VERSION ""

NS_ :

BS_:

BU_: WPC2 PSB SHVU_RR vHS_B2 FCS EMCU SLB GW_APSU GW_DLBCU RCM ARS CGW_CCU vDummy_HS_B GW_RLPSU ATS RLHV SGU PFSU GW_RRPSU ALBCU DSAU SWRC SHVU_FR RCS GW_DPSU BLTN_CAM SCM OHCL RWPC RRHV WPC HOD ASAU

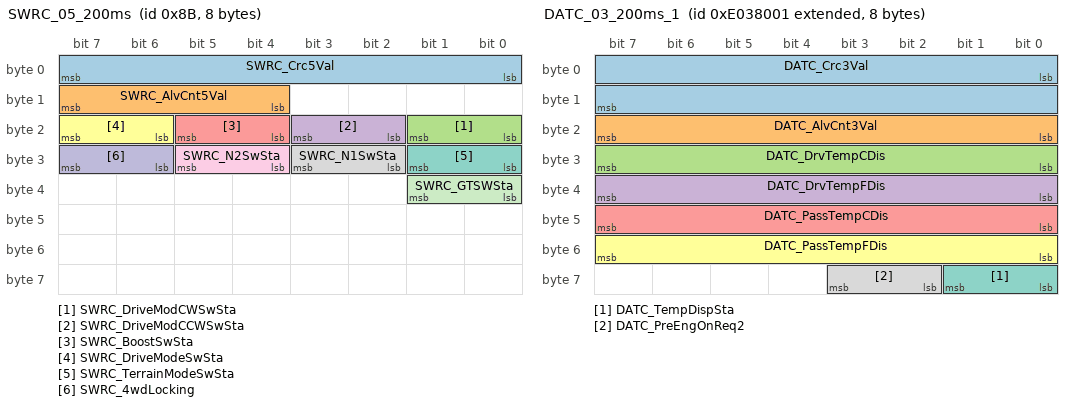
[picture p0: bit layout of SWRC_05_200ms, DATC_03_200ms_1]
BO_ 139 SWRC_05_200ms: 8 SWRC
 SG_ SWRC_Crc5Val : 0|8@1+ (1,0) [0|0] ""  CGW_CCU
 SG_ SWRC_AlvCnt5Val : 12|4@1+ (1,0) [0|0] ""  CGW_CCU
 SG_ SWRC_DriveModCWSwSta : 16|2@1+ (1,0) [0|0] ""  CGW_CCU
 SG_ SWRC_DriveModCCWSwSta : 18|2@1+ (1,0) [0|0] ""  CGW_CCU
 SG_ SWRC_BoostSwSta : 20|2@1+ (1,0) [0|0] ""  CGW_CCU
 SG_ SWRC_DriveModeSwSta : 22|2@1+ (1,0) [0|0] ""  CGW_CCU
 SG_ SWRC_TerrainModeSwSta : 24|2@1+ (1,0) [0|0] ""  CGW_CCU
 SG_ SWRC_N1SwSta : 26|2@1+ (1,0) [0|0] ""  CGW_CCU
 SG_ SWRC_N2SwSta : 28|2@1+ (1,0) [0|0] ""  CGW_CCU
 SG_ SWRC_4wdLocking : 30|2@1+ (1,0) [0|0] "Watt"  CGW_CCU
 SG_ SWRC_GTSWSta : 32|2@1+ (1,0) [0|0] ""  CGW_CCU

BO_ 2382594049 DATC_03_200ms_1: 8 CGW_CCU
 SG_ DATC_Crc3Val : 0|16@1+ (1,0) [0|0] ""  Vector__XXX
 SG_ DATC_AlvCnt3Val : 16|8@1+ (1,0) [0|0] ""  Vector__XXX
 SG_ DATC_DrvTempCDis : 24|8@1+ (0.5,14) [0|0] "¡É"  ATS
 SG_ DATC_DrvTempFDis : 32|8@1+ (1,56) [0|0] "¢µ"  ATS
 SG_ DATC_PassTempCDis : 40|8@1+ (0.5,14) [0|0] "¡É"  ATS
 SG_ DATC_PassTempFDis : 48|8@1+ (1,56) [0|0] "¢µ"  ATS
 SG_ DATC_TempDispSta : 56|2@1+ (1,0) [0|0] ""  Vector__XXX
 SG_ DATC_PreEngOnReq2 : 58|2@1+ (1,0) [0|0] ""  Vector__XXX

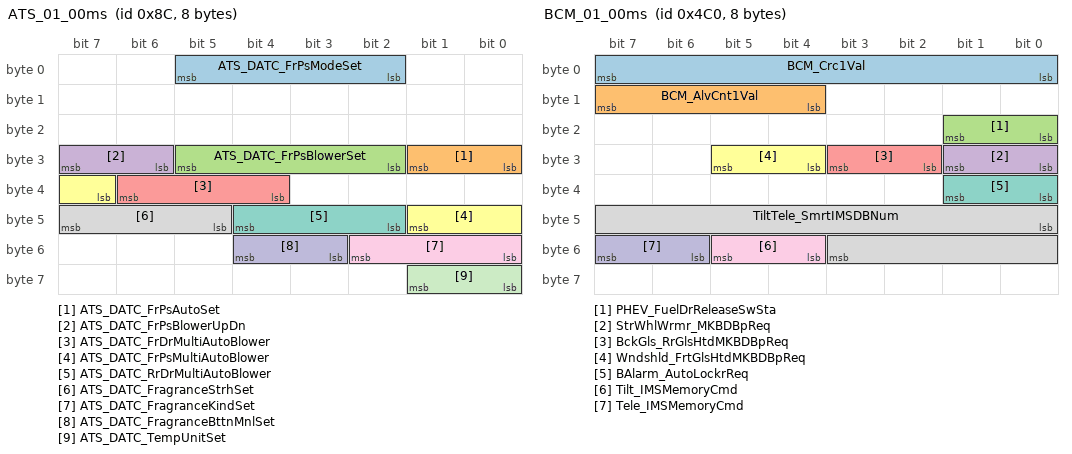
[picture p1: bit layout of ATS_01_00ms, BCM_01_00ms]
BO_ 140 ATS_01_00ms: 8 ATS
 SG_ ATS_DATC_FrPsModeSet : 2|4@1+ (1,0) [0|0] ""  CGW_CCU
 SG_ ATS_DATC_FrPsAutoSet : 24|2@1+ (1,0) [0|0] ""  CGW_CCU
 SG_ ATS_DATC_FrPsBlowerSet : 26|4@1+ (1,0) [0|0] ""  CGW_CCU
 SG_ ATS_DATC_FrPsBlowerUpDn : 30|2@1+ (1,0) [0|0] ""  CGW_CCU
 SG_ ATS_DATC_FrDrMultiAutoBlower : 36|3@1+ (1,0) [0|0] ""  CGW_CCU
 SG_ ATS_DATC_FrPsMultiAutoBlower : 39|3@1+ (1,0) [0|0] ""  CGW_CCU
 SG_ ATS_DATC_RrDrMultiAutoBlower : 42|3@1+ (1,0) [0|0] ""  CGW_CCU
 SG_ ATS_DATC_FragranceStrhSet : 45|3@1+ (1,0) [0|0] ""  CGW_CCU
 SG_ ATS_DATC_FragranceKindSet : 48|3@1+ (1,0) [0|0] ""  CGW_CCU
 SG_ ATS_DATC_FragranceBttnMnlSet : 51|2@1+ (1,0) [0|0] ""  CGW_CCU
 SG_ ATS_DATC_TempUnitSet : 56|2@1+ (1,0) [0|0] ""  CGW_CCU

BO_ 1216 BCM_01_00ms: 8 CGW_CCU
 SG_ BCM_Crc1Val : 0|8@1+ (1,0) [0|0] ""  Vector__XXX
 SG_ BCM_AlvCnt1Val : 12|4@1+ (1,0) [0|0] ""  Vector__XXX
 SG_ PHEV_FuelDrReleaseSwSta : 16|2@1+ (1,0) [0|0] ""  Vector__XXX
 SG_ StrWhlWrmr_MKBDBpReq : 24|2@1+ (1,0) [0|0] ""  Vector__XXX
 SG_ BckGls_RrGlsHtdMKBDBpReq : 26|2@1+ (1,0) [0|0] ""  Vector__XXX
 SG_ Wndshld_FrtGlsHtdMKBDBpReq : 28|2@1+ (1,0) [0|0] ""  Vector__XXX
 SG_ BAlarm_AutoLockrReq : 32|2@1+ (1,0) [0|0] ""  Vector__XXX
 SG_ TiltTele_SmrtIMSDBNum : 40|12@1+ (1,0) [0|0] ""  SCM
 SG_ Tilt_IMSMemoryCmd : 52|2@1+ (1,0) [0|0] ""  SCM
 SG_ Tele_IMSMemoryCmd : 54|2@1+ (1,0) [0|0] ""  SCM

BO_ 1219 HU_BLTN_CAM_E_00: 8 CGW_CCU
 SG_ BLTN_CAM_Rec_OWD_NvalueSet : 0|2@1+ (1,0) [0|0] ""  BLTN_CAM
 SG_ BLTN_CAM_Time_Stm_NvalueSet : 10|2@1+ (1,0) [0|0] ""  BLTN_CAM
 SG_ BLTN_CAM_Spd_Stm_NvalueSet : 12|2@1+ (1,0) [0|0] ""  BLTN_CAM
 SG_ BLTN_CAM_Locatn_Stm_NvalueSet : 14|2@1+ (1,0) [0|0] ""  BLTN_CAM
 SG_ BLTN_CAM_TrnSig_Stm_NvalueSet : 16|2@1+ (1,0) [0|0] ""  BLTN_CAM
 SG_ BLTN_CAM_AclBrk_Stm_NvalueSet : 18|2@1+ (1,0) [0|0] ""  BLTN_CAM
 SG_ BLTN_CAM_Rec_DEV_NvalueSet : 2|2@1+ (1,0) [0|0] ""  BLTN_CAM
 SG_ BLTN_CAM_GearPos_Stm_NvalueSet : 20|2@1+ (1,0) [0|0] ""  BLTN_CAM
 SG_ BLTN_CAM_EVSen_Stm_NvalueSet : 22|2@1+ (1,0) [0|0] ""  BLTN_CAM
 SG_ BLTN_CAM_Strangl_Stm_NvalueSet : 24|2@1+ (1,0) [0|0] ""  BLTN_CAM
 SG_ BLTN_CAM_EV_RecMaxTime_NvalueSet : 26|2@1+ (1,0) [0|0] ""  BLTN_CAM
 SG_ BLTN_CAM_PrkTime_NvalueSet : 30|8@1+ (1,0) [0|0] "Hour"  BLTN_CAM
 SG_ BLTN_CAM_EV_BfrTime_NvalueSet : 38|5@1+ (1,0) [0|0] ""  BLTN_CAM
 SG_ BLTN_CAM_Rec_OWP_NvalueSet : 4|2@1+ (1,0) [0|0] ""  BLTN_CAM
 SG_ BLTN_CAM_EV_AftTime_NvalueSet : 43|5@1+ (1,0) [0|0] ""  BLTN_CAM
 SG_ BLTN_CAM_TML_Int_NvalueSet : 48|4@1+ (1,0) [0|0] ""  BLTN_CAM
 SG_ BLTN_CAM_Sen_DEV_NvalueSet : 52|4@1+ (1,0) [0|0] ""  BLTN_CAM
 SG_ BLTN_CAM_Sen_PEV_NvalueSet : 56|4@1+ (1,0) [0|0] ""  BLTN_CAM
 SG_ BLTN_CAM_Rec_PEV_NvalueSet : 6|2@1+ (1,0) [0|0] ""  BLTN_CAM
 SG_ BLTN_CAM_AudRec_NvalueSet : 8|2@1+ (1,0) [0|0] ""  BLTN_CAM

BO_ 1218 HU_USM_E_08: 8 CGW_CCU
 SG_ C_AVN_PTGHeightNValueSet : 13|3@1+ (1,0) [0|0] ""  Vector__XXX
 SG_ CF_AVN_SCCMLReset : 16|2@1+ (1,0) [0|0] ""  Vector__XXX
 SG_ C_TgltAwayCloseNValue : 18|2@1+ (1,0) [0|0] ""  Vector__XXX
 SG_ C_HAnBNValueSet : 20|2@1+ (1,0) [0|0] ""  Vector__XXX
 SG_ CF_AVN_RrSeatRemindNValueSet : 22|2@1+ (1,0) [0|0] ""  Vector__XXX
 SG_ CF_AVN_DSWNValueSet : 24|2@1+ (1,0) [0|0] ""  Vector__XXX
 SG_ CF_AVN_RRPSU_RLNValueSet : 26|3@1+ (1,0) [0|0] ""  GW_APSU,GW_RLPSU,GW_RRPSU
 SG_ CF_AVN_APSUNValueSet : 29|3@1+ (1,0) [0|0] ""  GW_APSU
 SG_ CF_AVN_NCC_CameraNValueSet : 32|3@1+ (1,0) [0|0] ""  Vector__XXX
 SG_ CF_AVN_RRPSU_RRNValueSet : 37|3@1+ (1,0) [0|0] ""  GW_APSU,GW_RLPSU,GW_RRPSU
 SG_ CF_AVN_HtBlcAstNValueSet : 40|4@1+ (1,0) [0|0] ""  GW_APSU,SHVU_FR
 SG_ CF_AVN_HtBlcDrvNValueSet : 44|4@1+ (1,0) [0|0] ""  GW_APSU,GW_DPSU,SHVU_FR
 SG_ CF_AVN_SCCModeNValueSet : 48|2@1+ (1,0) [0|0] ""  Vector__XXX
 SG_ CF_AVN_SCCMLChar1Set : 50|3@1+ (1,0) [0|0] ""  Vector__XXX
 SG_ CF_AVN_UIPNValueSet : 54|2@1+ (1,0) [0|0] ""  Vector__XXX
 SG_ CF_AVN_SCCMLChar2Set : 56|3@1+ (1,0) [0|0] ""  Vector__XXX
 SG_ CF_AVN_SCCMLChar3Set : 59|3@1+ (1,0) [0|0] ""  Vector__XXX
 SG_ CF_AVN_HDALCFuncNValueSet : 8|2@1+ (1,0) [0|0] ""  Vector__XXX

BO_ 2323816451 CCU_CCS_01_00ms_3: 8 CGW_CCU

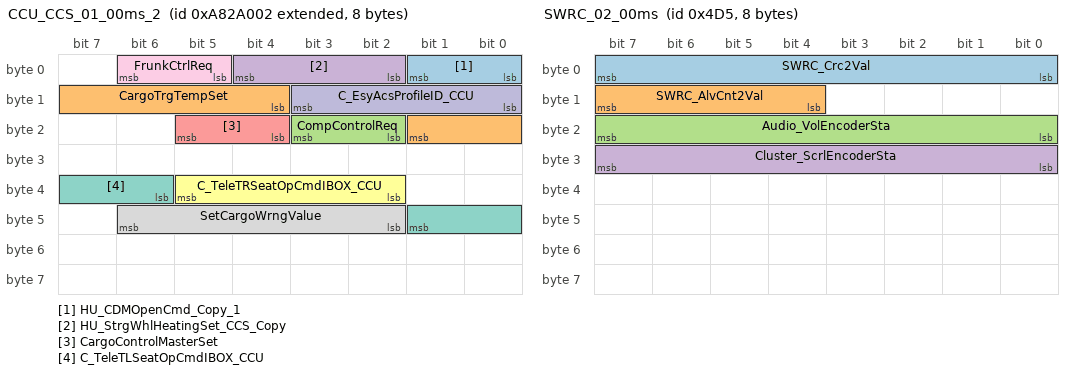
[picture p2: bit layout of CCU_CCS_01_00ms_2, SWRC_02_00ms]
BO_ 2323816450 CCU_CCS_01_00ms_2: 8 CGW_CCU
 SG_ HU_CDMOpenCmd_Copy_1 : 0|2@1+ (1,0) [0|0] ""  Vector__XXX
 SG_ CargoTrgTempSet : 12|6@1+ (1,-30) [0|0] "¡É"  Vector__XXX
 SG_ CompControlReq : 18|2@1+ (1,0) [0|0] ""  Vector__XXX
 SG_ HU_StrgWhlHeatingSet_CCS_Copy : 2|3@1+ (1,0) [0|0] ""  Vector__XXX
 SG_ CargoControlMasterSet : 20|2@1+ (1,0) [0|0] ""  Vector__XXX
 SG_ C_TeleTRSeatOpCmdIBOX_CCU : 34|4@1+ (1,0) [0|0] ""  Vector__XXX
 SG_ C_TeleTLSeatOpCmdIBOX_CCU : 38|4@1+ (1,0) [0|0] ""  Vector__XXX
 SG_ SetCargoWrngValue : 42|5@1+ (1,0) [0|0] "¡É"  Vector__XXX
 SG_ FrunkCtrlReq : 5|2@1+ (1,0) [0|0] ""  Vector__XXX
 SG_ C_EsyAcsProfileID_CCU : 8|4@1+ (1,0) [0|0] ""  GW_DPSU

BO_ 2323816449 CCU_CCS_01_00ms_1: 8 CGW_CCU
 SG_ C_CtrlDrLockRlyCCS_Copy_2 : 0|2@1+ (1,0) [0|0] ""  Vector__XXX
 SG_ C_TeleHeatingCmdIBOX_Copy_2 : 10|2@1+ (1,0) [0|0] ""  Vector__XXX
 SG_ C_TeleStrgWhlHeatingCmdIBOX_Copy_2 : 12|2@1+ (1,0) [0|0] ""  Vector__XXX
 SG_ C_TeleDefoggerHeatingCmdIBOX_Copy_2 : 14|2@1+ (1,0) [0|0] ""  Vector__XXX
 SG_ C_TeleDrvSeatOpCmdIBOX_Copy_2 : 16|4@1+ (1,0) [0|0] ""  GW_APSU,GW_DPSU,SHVU_FR
 SG_ C_CtrlDrUnlockRlyCCS_Copy_2 : 2|2@1+ (1,0) [0|0] ""  Vector__XXX
 SG_ C_TeleAstSeatOpCmdIBOX_Copy_2 : 20|4@1+ (1,0) [0|0] ""  GW_APSU,SHVU_FR
 SG_ C_TeleRRSeatOpCmdIBOX_Copy_2 : 24|4@1+ (1,0) [0|0] ""  ATS,GW_RRPSU,RRHV,SHVU_FR,SHVU_RR
 SG_ C_TeleRLSeatOpCmdIBOX_Copy_1 : 28|4@1+ (1,0) [0|0] ""  ATS,GW_RLPSU,RLHV,SHVU_FR,SHVU_RR
 SG_ C_DrvWindowCmdAVN_Copy_2 : 38|4@1+ (1,0) [0|0] ""  Vector__XXX
 SG_ C_HazardFromCCS_Copy_2 : 4|2@1+ (1,0) [0|0] ""  Vector__XXX
 SG_ C_AstWindowCmdAVN_Copy_2 : 42|4@1+ (1,0) [0|0] ""  Vector__XXX
 SG_ C_RRWindowCmdAVN_Copy_2 : 46|4@1+ (1,0) [0|0] ""  Vector__XXX
 SG_ C_RLWindowCmdAVN_Copy_2 : 50|4@1+ (1,0) [0|0] ""  Vector__XXX
 SG_ TailCtrlReq_Copy : 54|2@1+ (1,0) [0|0] ""  Vector__XXX
 SG_ HazardCtrlReq_Copy : 56|2@1+ (1,0) [0|0] ""  Vector__XXX
 SG_ HU_DATC_AirCleaningSet_Copy_1 : 58|2@1+ (1,0) [0|0] ""  Vector__XXX
 SG_ C_PanicFromCCS_Copy_2 : 6|2@1+ (1,0) [0|0] ""  Vector__XXX
 SG_ C_TeleFrontHeatingCmdIBOX_Copy_1 : 60|2@1+ (1,0) [0|0] ""  Vector__XXX
 SG_ RAC_AirCleaningCtrlReq_Copy_1 : 62|2@1+ (1,0) [0|0] ""  Vector__XXX
 SG_ C_PreCrankReq_Copy : 8|2@1+ (1,0) [0|0] ""  Vector__XXX

BO_ 1227 PSM_01_00ms: 8 GW_DPSU
 SG_ DrvIMS_MemoryP1Req : 0|2@1+ (1,0) [0|0] ""  CGW_CCU
 SG_ DrvIMS_PlyBckP2Req : 10|2@1+ (1,0) [0|0] ""  CGW_CCU
 SG_ DrvIMS_PlyBckP3Req : 12|2@1+ (1,0) [0|0] ""  CGW_CCU
 SG_ DrvIMS_PlyBckStpReq : 14|2@1+ (1,0) [0|0] ""  CGW_CCU
 SG_ SmrtIMS_PlyBckReq : 16|12@1+ (1,0) [0|0] ""  CGW_CCU
 SG_ DrvIMS_MemoryP2Req : 2|2@1+ (1,0) [0|0] ""  CGW_CCU
 SG_ PSM_IMSReq : 28|3@1+ (1,0) [0|0] ""  CGW_CCU
 SG_ SmrtIMS_ImgDBVal : 32|5@1+ (1,0) [0|0] ""  CGW_CCU
 SG_ SmrtIMS_PlyBckStpReq : 37|2@1+ (1,0) [0|0] ""  CGW_CCU
 SG_ DrvIMS_MemoryP3Req : 4|2@1+ (1,0) [0|0] ""  CGW_CCU
 SG_ SmrtIMS_EnterSwSta : 40|2@1+ (1,0) [0|0] ""  CGW_CCU
 SG_ DrvIMS_BzrReq : 42|2@1+ (1,0) [0|0] ""  CGW_CCU
 SG_ DrvIMS_ErrConWmgDis : 46|2@1+ (1,0) [0|0] ""  CGW_CCU
 SG_ PSM_DrvRlxReturn_Req : 48|3@1+ (1,0) [0|0] ""  CGW_CCU
 SG_ Drv_AutoRlxWrngDis : 51|3@1+ (1,0) [0|0] ""  CGW_CCU
 SG_ DrvIMS_AMPBzrReq : 54|2@1+ (1,0) [0|0] ""  CGW_CCU
 SG_ Drv_AutoRlxWrngDis_2 : 56|3@1+ (1,0) [0|0] ""  CGW_CCU
 SG_ Drv_2ndStStdPosMovReq : 59|2@1+ (1,0) [0|0] ""  GW_RLPSU,GW_RRPSU
 SG_ DrvIMS_MemorySetEnaSta : 6|2@1+ (1,0) [0|0] ""  CGW_CCU
 SG_ DrvIMS_PlyBckP1Req : 8|2@1+ (1,0) [0|0] ""  CGW_CCU

BO_ 2323816452 CCU_CCS_01_00ms_4: 8 CGW_CCU

BO_ 1237 SWRC_02_00ms: 8 SWRC
 SG_ SWRC_Crc2Val : 0|8@1+ (1,0) [0|0] ""  Vector__XXX
 SG_ SWRC_AlvCnt2Val : 12|4@1+ (1,0) [0|0] ""  Vector__XXX
 SG_ Audio_VolEncoderSta : 16|8@1+ (1,0) [0|0] ""  CGW_CCU
 SG_ Cluster_ScrlEncoderSta : 24|8@1+ (1,0) [0|0] ""  CGW_CCU

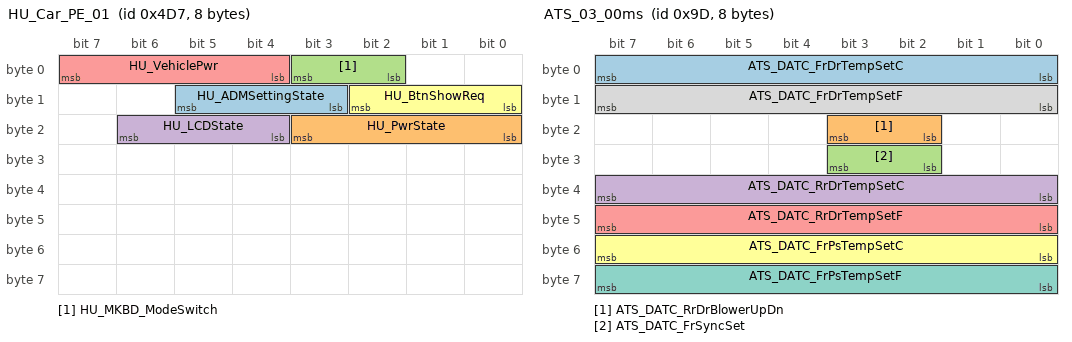
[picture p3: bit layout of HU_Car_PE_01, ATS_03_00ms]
BO_ 1239 HU_Car_PE_01: 8 CGW_CCU
 SG_ HU_ADMSettingState : 11|3@1+ (1,0) [0|0] ""  Vector__XXX
 SG_ HU_PwrState : 16|4@1+ (1,0) [0|0] ""  BLTN_CAM
 SG_ HU_MKBD_ModeSwitch : 2|2@1+ (1,0) [0|0] ""  Vector__XXX
 SG_ HU_LCDState : 20|3@1+ (1,0) [0|0] ""  Vector__XXX
 SG_ HU_VehiclePwr : 4|4@1+ (1,0) [0|0] ""  BLTN_CAM,SGU
 SG_ HU_BtnShowReq : 8|3@1+ (1,0) [0|0] ""  SWRC

BO_ 157 ATS_03_00ms: 8 ATS
 SG_ ATS_DATC_FrDrTempSetC : 0|8@1+ (0.5,14) [0|0] ""  CGW_CCU
 SG_ ATS_DATC_RrDrBlowerUpDn : 18|2@1+ (1,0) [0|0] ""  CGW_CCU
 SG_ ATS_DATC_FrSyncSet : 26|2@1+ (1,0) [0|0] ""  CGW_CCU
 SG_ ATS_DATC_RrDrTempSetC : 32|8@1+ (0.5,14) [0|0] ""  CGW_CCU
 SG_ ATS_DATC_RrDrTempSetF : 40|8@1+ (1,56) [0|0] ""  CGW_CCU
 SG_ ATS_DATC_FrPsTempSetC : 48|8@1+ (0.5,14) [0|0] ""  CGW_CCU
 SG_ ATS_DATC_FrPsTempSetF : 56|8@1+ (1,56) [0|0] ""  CGW_CCU
 SG_ ATS_DATC_FrDrTempSetF : 8|8@1+ (1,56) [0|0] ""  CGW_CCU

BO_ 158 ATS_02_00ms: 8 ATS
 SG_ ATS_DATC_FrDrBlowerSet : 12|4@1+ (1,0) [0|0] ""  CGW_CCU
 SG_ ATS_DATC_RrDrTempUpDn : 2|2@1+ (1,0) [0|0] ""  CGW_CCU
 SG_ ATS_DATC_RrDrBlowerSet : 20|4@1+ (1,0) [0|0] ""  CGW_CCU
 SG_ ATS_DATC_RrDrModeSet : 24|4@1+ (1,0) [0|0] ""  CGW_CCU
 SG_ ATS_DATC_FrDrModeSet : 28|4@1+ (1,0) [0|0] ""  CGW_CCU
 SG_ ATS_DATC_RrOnOffSet : 32|2@1+ (1,0) [0|0] ""  Vector__XXX
 SG_ ATS_DATC_IntakeSet : 34|2@1+ (1,0) [0|0] ""  CGW_CCU
 SG_ ATS_DATC_OffReq : 36|2@1+ (1,0) [0|0] ""  Vector__XXX
 SG_ ATS_DATC_FrDrAutoSet : 38|2@1+ (1,0) [0|0] ""  CGW_CCU
 SG_ ATS_DATC_FrPsTempUpDn : 4|2@1+ (1,0) [0|0] ""  CGW_CCU
 SG_ ATS_DATC_FrDefog : 42|2@1+ (1,0) [0|0] ""  CGW_CCU
 SG_ ATS_DATC_RrSyncSet : 44|2@1+ (1,0) [0|0] ""  CGW_CCU
 SG_ ATS_DATC_AcSet : 46|2@1+ (1,0) [0|0] ""  CGW_CCU
 SG_ ATS_DATC_AirCleaningSet : 56|2@1+ (1,0) [0|0] ""  CGW_CCU
 SG_ ATS_DATC_FrDrBlowerUpDn : 58|2@1+ (1,0) [0|0] ""  CGW_CCU
 SG_ ATS_DATC_FrDrTempUpDn : 6|2@1+ (1,0) [0|0] ""  CGW_CCU
 SG_ ATS_DATC_RrDrAutoSet : 62|2@1+ (1,0) [0|0] ""  CGW_CCU

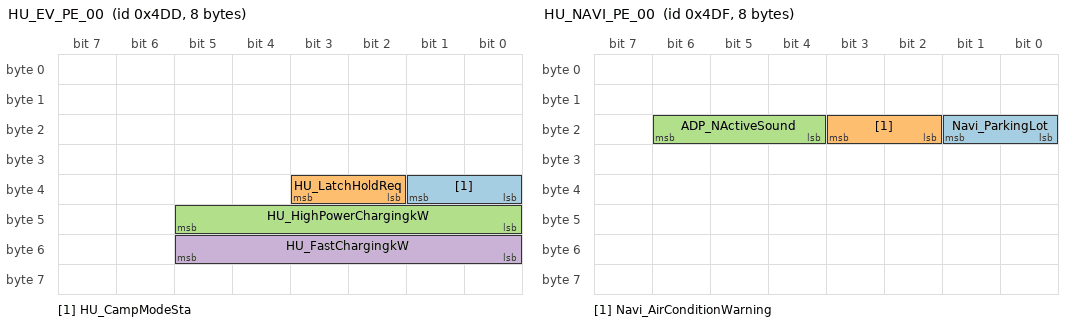
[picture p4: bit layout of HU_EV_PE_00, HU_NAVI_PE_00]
BO_ 1245 HU_EV_PE_00: 8 CGW_CCU
 SG_ HU_CampModeSta : 32|2@1+ (1,0) [0|0] ""  SWRC
 SG_ HU_LatchHoldReq : 34|2@1+ (1,0) [0|0] ""  Vector__XXX
 SG_ HU_HighPowerChargingkW : 40|6@1+ (10,0) [0|0] "kW"  Vector__XXX
 SG_ HU_FastChargingkW : 48|6@1+ (10,0) [0|0] "kW"  Vector__XXX

BO_ 1247 HU_NAVI_PE_00: 8 CGW_CCU
 SG_ Navi_ParkingLot : 16|2@1+ (1,0) [0|0] ""  Vector__XXX
 SG_ Navi_AirConditionWarning : 18|2@1+ (1,0) [0|0] ""  RCM
 SG_ ADP_NActiveSound : 20|3@1+ (1,0) [0|0] ""  Vector__XXX

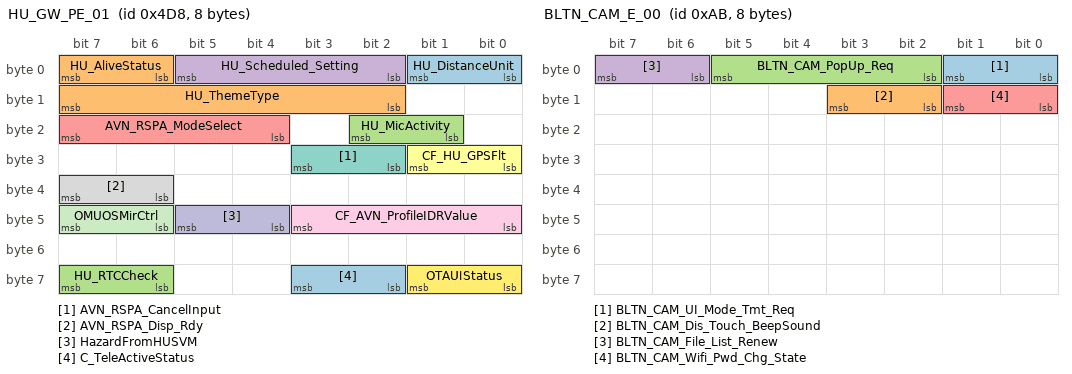
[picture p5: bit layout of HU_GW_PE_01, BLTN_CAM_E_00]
BO_ 1240 HU_GW_PE_01: 8 CGW_CCU
 SG_ HU_DistanceUnit : 0|2@1+ (1,0) [0|0] ""  Vector__XXX
 SG_ HU_ThemeType : 10|6@1+ (1,0) [0|0] ""  ATS,BLTN_CAM
 SG_ HU_MicActivity : 17|2@1+ (1,0) [0|0] ""  Vector__XXX
 SG_ HU_Scheduled_Setting : 2|4@1+ (1,0) [0|0] ""  Vector__XXX
 SG_ AVN_RSPA_ModeSelect : 20|4@1+ (1,0) [0|0] ""  Vector__XXX
 SG_ CF_HU_GPSFlt : 24|2@1+ (1,0) [0|0] ""  Vector__XXX
 SG_ AVN_RSPA_CancelInput : 26|2@1+ (1,0) [0|3] ""  Vector__XXX
 SG_ AVN_RSPA_Disp_Rdy : 38|2@1+ (1,0) [0|0] ""  Vector__XXX
 SG_ CF_AVN_ProfileIDRValue : 40|4@1+ (1,0) [0|0] ""  BLTN_CAM,GW_DLBCU,GW_DPSU,RCM,RWPC,SGU,WPC,WPC2
 SG_ HazardFromHUSVM : 44|2@1+ (1,0) [0|0] ""  Vector__XXX
 SG_ OMUOSMirCtrl : 46|2@1+ (1,0) [0|0] ""  Vector__XXX
 SG_ OTAUIStatus : 56|2@1+ (1,0) [0|0] ""  Vector__XXX
 SG_ C_TeleActiveStatus : 58|2@1+ (1,0) [0|0] ""  Vector__XXX
 SG_ HU_AliveStatus : 6|2@1+ (1,0) [0|0] ""  Vector__XXX
 SG_ HU_RTCCheck : 62|2@1+ (1,0) [0|0] ""  GW_APSU

BO_ 2424580353 DATC_12_200ms_1: 8 CGW_CCU
 SG_ DATC_Crc12Val : 0|16@1+ (1,0) [0|0] ""  Vector__XXX
 SG_ DATC_AlvCnt12Val : 16|8@1+ (1,0) [0|0] ""  Vector__XXX
 SG_ DATC_StrWhlHtrSwReq : 24|2@1+ (1,0) [0|0] ""  Vector__XXX
 SG_ DATC_FRStHtrSwReq : 26|2@1+ (1,0) [0|0] ""  GW_APSU,GW_DPSU,SHVU_FR,SHVU_RR
 SG_ DATC_FRStVentSwReq : 28|2@1+ (1,0) [0|0] ""  GW_APSU,GW_DPSU,SHVU_FR,SHVU_RR
 SG_ DATC_RrDefSw : 30|2@1+ (1,0) [0|0] ""  Vector__XXX
 SG_ DATC_FLStOpReq : 32|4@1+ (1,0) [0|0] ""  GW_APSU,GW_DPSU,SHVU_FR,SHVU_RR
 SG_ DATC_FRStOpReq : 36|4@1+ (1,0) [0|0] ""  GW_APSU,SHVU_FR,SHVU_RR
 SG_ DATC_FLStHtrSwReq : 40|2@1+ (1,0) [0|0] ""  GW_APSU,GW_DPSU,SHVU_FR,SHVU_RR
 SG_ DATC_FLStVentSwReq : 42|2@1+ (1,0) [0|0] ""  GW_APSU,GW_DPSU,SHVU_FR,SHVU_RR
 SG_ DATC_FLStTmblrSwReq : 44|2@1+ (1,0) [0|0] ""  GW_APSU,GW_DPSU,SHVU_FR
 SG_ DATC_FRStTmblrSwReq : 46|2@1+ (1,0) [0|0] ""  GW_APSU,GW_DPSU,SHVU_FR
 SG_ DATC_RRStHtrSwReq : 48|2@1+ (1,0) [0|0] ""  GW_RRPSU,RRHV,SHVU_FR,SHVU_RR
 SG_ DATC_RRStVentSwReq : 50|2@1+ (1,0) [0|0] ""  GW_RRPSU,RRHV,SHVU_FR,SHVU_RR
 SG_ DATC_RLStHtrSwReq : 52|2@1+ (1,0) [0|0] ""  GW_RLPSU,RLHV,SHVU_FR,SHVU_RR
 SG_ DATC_RLStVentSwReq : 54|2@1+ (1,0) [0|0] ""  GW_RLPSU,RLHV,SHVU_FR,SHVU_RR
 SG_ DATC_FRWndShldHtSW : 56|2@1+ (1,0) [0|0] ""  Vector__XXX
 SG_ DATC_WhistlelNoise : 58|2@1+ (1,0) [0|0] ""  Vector__XXX
 SG_ DATC_WdwClsReq : 60|2@1+ (1,0) [0|0] ""  Vector__XXX
 SG_ DATC_RRSyncDis : 62|2@1+ (1,0) [0|0] ""  ATS

BO_ 171 BLTN_CAM_E_00: 8 BLTN_CAM
 SG_ BLTN_CAM_UI_Mode_Tmt_Req : 0|2@1+ (1,0) [0|0] ""  CGW_CCU
 SG_ BLTN_CAM_Dis_Touch_BeepSound : 10|2@1+ (1,0) [0|0] ""  CGW_CCU
 SG_ BLTN_CAM_PopUp_Req : 2|4@1+ (1,0) [0|0] ""  CGW_CCU
 SG_ BLTN_CAM_File_List_Renew : 6|2@1+ (1,0) [0|0] ""  CGW_CCU
 SG_ BLTN_CAM_Wifi_Pwd_Chg_State : 8|2@1+ (1,0) [0|0] ""  CGW_CCU

BO_ 1253 SMK_01_00ms: 8 CGW_CCU
 SG_ SMK_Crc1Val : 0|8@1+ (1,0) [0|0] ""  Vector__XXX
 SG_ SMK_AlvCnt1Val : 12|4@1+ (1,0) [0|0] ""  Vector__XXX
 SG_ DoorLock_PsvDrLkReq : 16|3@1+ (1,0) [0|0] ""  Vector__XXX
 SG_ DoorLock_PsvDrUnLkReq : 19|3@1+ (1,0) [0|0] ""  Vector__XXX
 SG_ DoorLock_DrvDrPsvAcsReq : 22|2@1+ (1,0) [0|0] ""  Vector__XXX
 SG_ DoorLock_AsstDrPsvAcsReq : 24|2@1+ (1,0) [0|0] ""  Vector__XXX
 SG_ DoorLock_TrnkTlgtPsvAcsReq : 26|2@1+ (1,0) [0|0] ""  Vector__XXX
 SG_ DoorLock_RrLftDrPsvAcsReq : 28|2@1+ (1,0) [0|0] ""  Vector__XXX
 SG_ DoorLock_RrRtDrPsvAcsReq : 30|2@1+ (1,0) [0|0] ""  Vector__XXX
 SG_ DoorLock_PsdPsvAcsReq : 32|3@1+ (1,0) [0|0] ""  Vector__XXX
 SG_ Auth_Req : 35|3@1+ (1,0) [0|0] ""  Vector__XXX
 SG_ RSPA_DigitalKeyAuth : 38|2@1+ (1,0) [0|0] ""  Vector__XXX
 SG_ Auth_Method : 42|4@1+ (1,0) [0|0] ""  GW_DPSU
 SG_ DoorLock_StrgbxPsvAcsReq : 46|2@1+ (1,0) [0|0] ""  Vector__XXX
 SG_ Auth_ISKLearnFdbck : 50|4@1+ (1,0) [0|0] ""  Vector__XXX
 SG_ DoorLock_FrnkWrngOpnReq : 54|2@1+ (1,0) [0|0] ""  Vector__XXX
 SG_ DoorLock_SmrtPsdPsvAcsReq : 61|3@1+ (1,0) [0|0] ""  Vector__XXX
 SG_ Auth_Event : 8|4@1+ (1,0) [0|0] ""  GW_DPSU

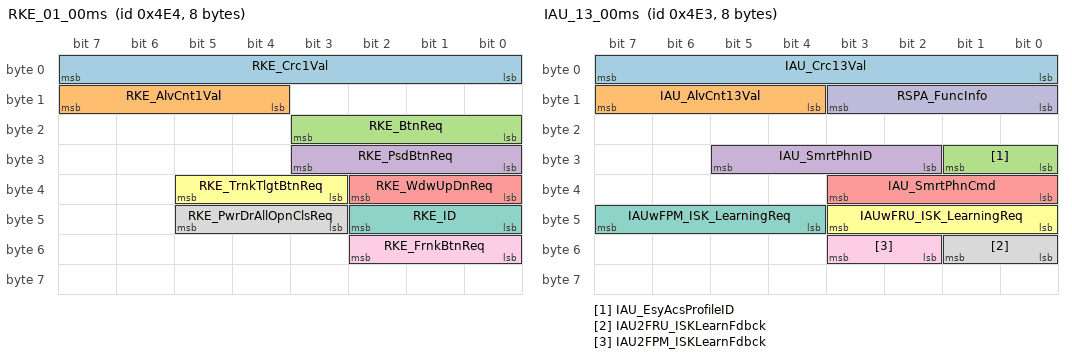
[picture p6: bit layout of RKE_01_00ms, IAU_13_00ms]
BO_ 1252 RKE_01_00ms: 8 CGW_CCU
 SG_ RKE_Crc1Val : 0|8@1+ (1,0) [0|0] ""  Vector__XXX
 SG_ RKE_AlvCnt1Val : 12|4@1+ (1,0) [0|0] ""  Vector__XXX
 SG_ RKE_BtnReq : 16|4@1+ (1,0) [0|0] ""  ATS
 SG_ RKE_PsdBtnReq : 24|4@1+ (1,0) [0|0] ""  Vector__XXX
 SG_ RKE_WdwUpDnReq : 32|3@1+ (1,0) [0|0] ""  RCM
 SG_ RKE_TrnkTlgtBtnReq : 35|3@1+ (1,0) [0|0] ""  Vector__XXX
 SG_ RKE_ID : 40|3@1+ (1,0) [0|0] ""  Vector__XXX
 SG_ RKE_PwrDrAllOpnClsReq : 43|3@1+ (1,0) [0|0] ""  Vector__XXX
 SG_ RKE_FrnkBtnReq : 48|3@1+ (1,0) [0|0] ""  Vector__XXX

BO_ 1251 IAU_13_00ms: 8 CGW_CCU
 SG_ IAU_Crc13Val : 0|8@1+ (1,0) [0|0] ""  Vector__XXX
 SG_ IAU_AlvCnt13Val : 12|4@1+ (1,0) [0|0] ""  Vector__XXX
 SG_ IAU_EsyAcsProfileID : 24|2@1+ (1,0) [0|0] ""  GW_DPSU
 SG_ IAU_SmrtPhnID : 26|4@1+ (1,0) [0|0] ""  Vector__XXX
 SG_ IAU_SmrtPhnCmd : 32|4@1+ (1,0) [0|0] ""  Vector__XXX
 SG_ IAUwFRU_ISK_LearningReq : 40|4@1+ (1,0) [0|0] ""  Vector__XXX
 SG_ IAUwFPM_ISK_LearningReq : 44|4@1+ (1,0) [0|0] ""  Vector__XXX
 SG_ IAU2FRU_ISKLearnFdbck : 48|2@1+ (1,0) [0|0] ""  Vector__XXX
 SG_ IAU2FPM_ISKLearnFdbck : 50|2@1+ (1,0) [0|0] ""  Vector__XXX
 SG_ RSPA_FuncInfo : 8|4@1+ (1,0) [0|0] ""  Vector__XXX

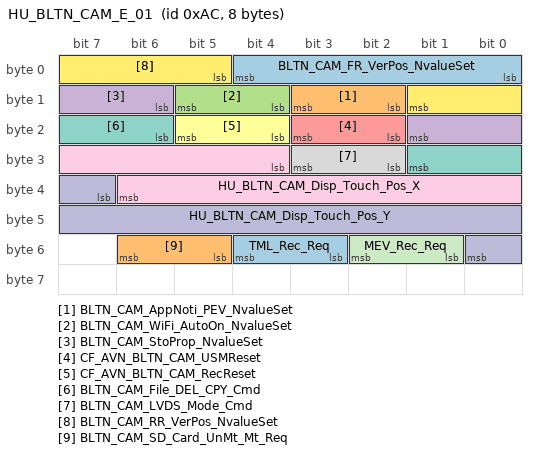
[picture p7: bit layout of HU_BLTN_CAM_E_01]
BO_ 172 HU_BLTN_CAM_E_01: 8 CGW_CCU
 SG_ BLTN_CAM_FR_VerPos_NvalueSet : 0|5@1+ (1,0) [0|0] ""  BLTN_CAM
 SG_ BLTN_CAM_AppNoti_PEV_NvalueSet : 10|2@1+ (1,0) [0|0] ""  BLTN_CAM
 SG_ BLTN_CAM_WiFi_AutoOn_NvalueSet : 12|2@1+ (1,0) [0|0] ""  BLTN_CAM
 SG_ BLTN_CAM_StoProp_NvalueSet : 14|4@1+ (1,0) [0|0] ""  BLTN_CAM
 SG_ CF_AVN_BLTN_CAM_USMReset : 18|2@1+ (1,0) [0|0] ""  BLTN_CAM
 SG_ CF_AVN_BLTN_CAM_RecReset : 20|2@1+ (1,0) [0|0] ""  BLTN_CAM
 SG_ BLTN_CAM_File_DEL_CPY_Cmd : 22|4@1+ (1,0) [0|0] ""  BLTN_CAM
 SG_ BLTN_CAM_LVDS_Mode_Cmd : 26|2@1+ (1,0) [0|0] ""  BLTN_CAM
 SG_ HU_BLTN_CAM_Disp_Touch_Pos_X : 28|11@1+ (1,0) [0|0] ""  BLTN_CAM
 SG_ HU_BLTN_CAM_Disp_Touch_Pos_Y : 39|10@1+ (1,0) [0|0] ""  BLTN_CAM
 SG_ MEV_Rec_Req : 49|2@1+ (1,0) [0|0] ""  BLTN_CAM
 SG_ BLTN_CAM_RR_VerPos_NvalueSet : 5|5@1+ (1,0) [0|0] ""  BLTN_CAM
 SG_ TML_Rec_Req : 51|2@1+ (1,0) [0|0] ""  BLTN_CAM
 SG_ BLTN_CAM_SD_Card_UnMt_Mt_Req : 53|2@1+ (1,0) [0|0] ""  BLTN_CAM

CM_ BO_ 140 "[EC] On Event and On Change";
CM_ SG_ 140 ATS_DATC_FrPsModeSet "Front Passenger side Mode Set";
CM_ SG_ 140 ATS_DATC_FrPsAutoSet "Front Passenger side Auto Set";
CM_ SG_ 140 ATS_DATC_FrPsBlowerSet "Front Passenger side Blower Set";
CM_ SG_ 140 ATS_DATC_FrPsBlowerUpDn "Front Passenger side Blower Up Down";
CM_ SG_ 140 ATS_DATC_FrDrMultiAutoBlower "Front Driver side Multi-Auto Blower set";
CM_ SG_ 140 ATS_DATC_FrPsMultiAutoBlower "Front Passenger side Multi-Auto Blower set";
CM_ SG_ 140 ATS_DATC_RrDrMultiAutoBlower "Rear Driver side Multi-Auto Blower set";
CM_ SG_ 140 ATS_DATC_FragranceStrhSet "Fragrance Strength Set (¹ßÇâ ±â´É Çâ ¼¼±â ¼³Á¤)";
CM_ SG_ 140 ATS_DATC_FragranceKindSet "Fragrance Kind Set (¹ßÇâ ±â´É Çâ Á¾·ù ¼³Á¤)";
CM_ SG_ 140 ATS_DATC_FragranceBttnMnlSet "Fragrance Button Manual Set (¹ßÇâ ±â´É ¹öÆ° ¼öµ¿ ÀÔ·Â)";
CM_ SG_ 140 ATS_DATC_TempUnitSet "Temp Unit Set (¿Âµµ ´ÜÀ§ ¼³Á¤)";
CM_ BO_ 158 "[EC] On Event and On Change";
CM_ SG_ 158 ATS_DATC_FrDrBlowerSet "Front Driver side Blower Set";
CM_ SG_ 158 ATS_DATC_RrDrTempUpDn "Rear Driver side Temp Up Down";
CM_ SG_ 158 ATS_DATC_RrDrBlowerSet "Rear Driver side Blower Up Down";
CM_ SG_ 158 ATS_DATC_RrDrModeSet "Rear Driver side Mode Set";
CM_ SG_ 158 ATS_DATC_FrDrModeSet "Front Driver side Mode Set";
CM_ SG_ 158 ATS_DATC_RrOnOffSet "Rear Climate On/Off Set";
CM_ SG_ 158 ATS_DATC_IntakeSet "Intake Set";
CM_ SG_ 158 ATS_DATC_OffReq "Front Climate Off Set";
CM_ SG_ 158 ATS_DATC_FrDrAutoSet "Front Driver side Auto Set";
CM_ SG_ 158 ATS_DATC_FrPsTempUpDn "Front Passenger side Temp Up Down";
CM_ SG_ 158 ATS_DATC_FrDefog "Front Defog set";
CM_ SG_ 158 ATS_DATC_RrSyncSet "Rear Sync Set";
CM_ SG_ 158 ATS_DATC_AcSet "Ac Set";
CM_ SG_ 158 ATS_DATC_AirCleaningSet "AirCleaning Set";
CM_ SG_ 158 ATS_DATC_FrDrBlowerUpDn "Front Driver Blower Up Down";
CM_ SG_ 158 ATS_DATC_FrDrTempUpDn "Front Driver side Temp Up Down";
CM_ SG_ 158 ATS_DATC_RrDrAutoSet "Rear Driver side Auto Set";
CM_ BO_ 157 "[EC] On Event and On Change";
CM_ SG_ 157 ATS_DATC_FrDrTempSetC "Front Driver side Temp Set (Celsius)";
CM_ SG_ 157 ATS_DATC_RrDrBlowerUpDn "Rear Driver side Blower Up Down";
CM_ SG_ 157 ATS_DATC_FrSyncSet "Front Sync Set";
CM_ SG_ 157 ATS_DATC_RrDrTempSetC "Rear Driver side Temp Set (Celsius)";
CM_ SG_ 157 ATS_DATC_RrDrTempSetF "Rear Driver side Temp Set (Fahrenheit)";
CM_ SG_ 157 ATS_DATC_FrPsTempSetC "Front Passenger side Temp Set (Celsius)";
CM_ SG_ 157 ATS_DATC_FrPsTempSetF "Front Passenger side Temp Set (Fahrenheit)";
CM_ SG_ 157 ATS_DATC_FrDrTempSetF "Front Driver side Temp Set (Fahrenheit)";
CM_ BO_ 1216 "[EC] On Event and On Change";
CM_ SG_ 1216 BCM_Crc1Val "BCM_CyclicRedundancyCheck1Value";
CM_ SG_ 1216 BCM_AlvCnt1Val "BCM_AliveCounter1Value";
CM_ SG_ 1216 PHEV_FuelDrReleaseSwSta "PHEV Fuel Filler Door Release Sw State";
CM_ SG_ 1216 BAlarm_AutoLockrReq "BAlarm_AutoLockRequest ##2G##BCM - BCMmsg01 - C_AutoLockCmd";
CM_ BO_ 171 "[EC] On Event and On Change";
CM_ SG_ 171 BLTN_CAM_UI_Mode_Tmt_Req "Built-in Cam UI Mode terminate request.";
CM_ SG_ 171 BLTN_CAM_Dis_Touch_BeepSound "Display Touch Beep Sound of valid space touch.";
CM_ SG_ 171 BLTN_CAM_PopUp_Req "Built-in Cam Operating and SD Card related Popup Request on HU Display.";
CM_ SG_ 171 BLTN_CAM_File_List_Renew "The Storage information is renewed inform to HU.";
CM_ SG_ 171 BLTN_CAM_Wifi_Pwd_Chg_State "The Response, when HU change Wifi Passowrd via SOME/IP";
CM_ BO_ 2323816449 "[EC] On Event and On Change";
CM_ SG_ 2323816449 C_CtrlDrLockRlyCCS_Copy_2 "Command for Remote Door Lock";
CM_ SG_ 2323816449 C_TeleHeatingCmdIBOX_Copy_2 "'Command for Remote Heating

(Steering Wheel, Rear Window, Side Mirror)";
CM_ SG_ 2323816449 C_TeleStrgWhlHeatingCmdIBOX_Copy_2 "'Command for Remote Heating
(Steering Wheel)";
CM_ SG_ 2323816449 C_TeleDefoggerHeatingCmdIBOX_Copy_2 "'Command for Remote Heating
(Rear Window, Side Mirror)";
CM_ SG_ 2323816449 C_TeleDrvSeatOpCmdIBOX_Copy_2 "Command for Remote Seat Heat/Vent control (Driver)";
CM_ SG_ 2323816449 C_CtrlDrUnlockRlyCCS_Copy_2 "Command for Remote Door UnLock";
CM_ SG_ 2323816449 C_TeleAstSeatOpCmdIBOX_Copy_2 "Command for Remote Seat Heat/Vent control (Passenger)";
CM_ SG_ 2323816449 C_TeleRRSeatOpCmdIBOX_Copy_2 "Command for Remote Seat Heat/Vent control (Rear Right)";
CM_ SG_ 2323816449 C_TeleRLSeatOpCmdIBOX_Copy_1 "Command for Remote Seat Heat/Vent control (Rear Left)";
CM_ SG_ 2323816449 C_DrvWindowCmdAVN_Copy_2 "This signal indicates DRV Window Open/Close Command";
CM_ SG_ 2323816449 C_HazardFromCCS_Copy_2 "Command for Remote Hazard";
CM_ SG_ 2323816449 C_AstWindowCmdAVN_Copy_2 "This signal indicates AST Window Open/Close Command";
CM_ SG_ 2323816449 C_RRWindowCmdAVN_Copy_2 "This signal indicates RR Window Open/Close Command";
CM_ SG_ 2323816449 C_RLWindowCmdAVN_Copy_2 "This signal indicates RL Window Open/Close Command";
CM_ SG_ 2323816449 TailCtrlReq_Copy "This signal is for cotroling Tail lamp.";
CM_ SG_ 2323816449 HazardCtrlReq_Copy "This signal is request for controling Hazard lamp.";
CM_ SG_ 2323816449 HU_DATC_AirCleaningSet_Copy_1 "Air Cleaning System set";
CM_ SG_ 2323816449 C_PanicFromCCS_Copy_2 "Command for Remote Panic (Only for USA)";
CM_ SG_ 2323816449 C_TeleFrontHeatingCmdIBOX_Copy_1 "Command for Remote Heating (Front Window)";
CM_ SG_ 2323816449 RAC_AirCleaningCtrlReq_Copy_1 "RAC_Air Cleaning Control Request";
CM_ SG_ 2323816449 C_PreCrankReq_Copy "Command for B-CAN wake up singal (Need to send this signal before other remote commands)";
CM_ BO_ 2323816450 "[EC] On Event and On Change";
CM_ SG_ 2323816450 HU_CDMOpenCmd_Copy_1 "Command for CDM open/close";
CM_ SG_ 2323816450 CargoTrgTempSet "This signal is to set the target temperature of cargo";
CM_ SG_ 2323816450 CompControlReq "This signal to control the compressor of Cargo";
CM_ SG_ 2323816450 CargoControlMasterSet "This signal is to set the control master of Carge teperature control.";
CM_ SG_ 2323816450 C_TeleTRSeatOpCmdIBOX_CCU "Command for Remote Seat Heat/Vent control (3RD Right)";
CM_ SG_ 2323816450 C_TeleTLSeatOpCmdIBOX_CCU "Command for Remote Seat Heat/Vent control (3RD Left)";
CM_ SG_ 2323816450 SetCargoWrngValue "This signal is to set the Threshold value for the Cargo warning.";
CM_ SG_ 2323816450 FrunkCtrlReq "This signal is request for controling Frunk.";
CM_ SG_ 2323816450 C_EsyAcsProfileID_CCU "This signal indicates the current detected profile ID by smartphone APP.
(The drv seat move to the easy access position of the detected profile ID when receive the signal)";
CM_ BO_ 2323816451 "[EC] On Event and On Change";
CM_ BO_ 2323816452 "[EC] On Event and On Change";
CM_ BO_ 2382594049 "[PE] Periodic and On Event";
CM_ SG_ 2382594049 DATC_Crc3Val "DATC_CyclicRedundancyCheck3Value";
CM_ SG_ 2382594049 DATC_AlvCnt3Val "DATC_AliveCounter3Value";
CM_ SG_ 2382594049 DATC_DrvTempCDis "DATC_DriverTemperatureCelciusDisplay";
CM_ SG_ 2382594049 DATC_DrvTempFDis "DATC_DriverTemperatureFahrenheitDisplay";
CM_ SG_ 2382594049 DATC_PassTempCDis "DATC_PassengerTemperatureCelciusDisplay";
CM_ SG_ 2382594049 DATC_PassTempFDis "DATC_PassengerTemperatureFahrenheitDisplay";
CM_ SG_ 2382594049 DATC_TempDispSta "DATCTempDisplayStatus";
CM_ SG_ 2382594049 DATC_PreEngOnReq2 "Pre Engine On Request";
CM_ BO_ 2424580353 "[PE] Periodic and On Event";
CM_ SG_ 2424580353 DATC_Crc12Val "DATC_CyclicRedundancyCheck12Value";
CM_ SG_ 2424580353 DATC_AlvCnt12Val "DATC_AliveCounter12Value";
CM_ SG_ 2424580353 DATC_StrWhlHtrSwReq "DATC_SteeringWheelHeaterSwitchRequest";
CM_ SG_ 2424580353 DATC_FRStHtrSwReq "DATC_FrontRightSeatHeaterSwitchRequest";
CM_ SG_ 2424580353 DATC_FRStVentSwReq "DATC_FrontRightSeatVentilationSwitchRequest";
CM_ SG_ 2424580353 DATC_RrDefSw "Rear Defog Switch";
CM_ SG_ 2424580353 DATC_FLStOpReq "DATC_FrontLeftSeatOperationRequest";
CM_ SG_ 2424580353 DATC_FRStOpReq "DATC_FrontRightSeatOperationRequest";
CM_ SG_ 2424580353 DATC_FLStHtrSwReq "DATC_FrontLeftSeatHeaterSwitchRequest";
CM_ SG_ 2424580353 DATC_FLStVentSwReq "DATC_FrontLefttSeatVentilationSwitchRequest";
CM_ SG_ 2424580353 DATC_FLStTmblrSwReq "DATC_FrontLefttSeatTumblerSwitchRequest";
CM_ SG_ 2424580353 DATC_FRStTmblrSwReq "DATC_FrontRightSeatTumblerSwitchRequest";
CM_ SG_ 2424580353 DATC_RRStHtrSwReq "DATC_RearRightSeatHeaterSwitchRequest";
CM_ SG_ 2424580353 DATC_RRStVentSwReq "DATC_RearRightSeatVentilationSwitchRequest";
CM_ SG_ 2424580353 DATC_RLStHtrSwReq "DATC_RearLeftSeatHeaterSwitchRequest";
CM_ SG_ 2424580353 DATC_RLStVentSwReq "DATC_RearLefttSeatVentilationSwitchRequest";
CM_ SG_ 2424580353 DATC_WdwClsReq "DATC_WindowCloseRequest";
CM_ SG_ 2424580353 DATC_RRSyncDis "DATC_RRSyncDisplay";
CM_ BO_ 1219 "[EC] On Event and On Change";
CM_ SG_ 1219 BLTN_CAM_Rec_OWD_NvalueSet "Record On/Off Set of On While Driving";
CM_ SG_ 1219 BLTN_CAM_Time_Stm_NvalueSet "Record Set of Date and Time Stamp";
CM_ SG_ 1219 BLTN_CAM_Spd_Stm_NvalueSet "Record Set of Speed Stamp";
CM_ SG_ 1219 BLTN_CAM_Locatn_Stm_NvalueSet "Record Set of Location Stamp";
CM_ SG_ 1219 BLTN_CAM_TrnSig_Stm_NvalueSet "Record Set of Turn Signal Stamp";
CM_ SG_ 1219 BLTN_CAM_AclBrk_Stm_NvalueSet "Record Set of Accelerator Brake Stamp";
CM_ SG_ 1219 BLTN_CAM_Rec_DEV_NvalueSet "Record On/Off Set of Driving Event";
CM_ SG_ 1219 BLTN_CAM_GearPos_Stm_NvalueSet "Record Set of Gear Position Stamp";
CM_ SG_ 1219 BLTN_CAM_EVSen_Stm_NvalueSet "Record Set of Event Sensitivity Stamp";
CM_ SG_ 1219 BLTN_CAM_Strangl_Stm_NvalueSet "Record Set of Steering Angle Stamp";
CM_ SG_ 1219 BLTN_CAM_EV_RecMaxTime_NvalueSet "Record Set of  EV Parking Rec Max Time On/Off";
CM_ SG_ 1219 BLTN_CAM_PrkTime_NvalueSet "Parking Operation Setting Time, Resolution : hr";
CM_ SG_ 1219 BLTN_CAM_EV_BfrTime_NvalueSet "Driving Event Time Setting - Before, Resolution : sec";
CM_ SG_ 1219 BLTN_CAM_Rec_OWP_NvalueSet "Record On/Off Set of On While Parked, 0x0(Default) : Parking recording function not supported";
CM_ SG_ 1219 BLTN_CAM_EV_AftTime_NvalueSet "Driving Event Time Setting - After, Resolution : sec";
CM_ SG_ 1219 BLTN_CAM_TML_Int_NvalueSet "Record Set of Time-lapse Interval, Resolution : sec";
CM_ SG_ 1219 BLTN_CAM_Sen_DEV_NvalueSet "Set of Event  Detection Sensitivity of Driving Mode";
CM_ SG_ 1219 BLTN_CAM_Sen_PEV_NvalueSet "Set of Event  Detection Sensitivity of Parking Mode";
CM_ SG_ 1219 BLTN_CAM_Rec_PEV_NvalueSet "Record Set of Parked Event, 0x0(Default) : Parking recording function not supported";
CM_ SG_ 1219 BLTN_CAM_AudRec_NvalueSet "Audio Record On/Off Set";
CM_ BO_ 172 "[EC] On Event and On Change";
CM_ SG_ 172 BLTN_CAM_FR_VerPos_NvalueSet "Front Camera Vertical position setting value.";
CM_ SG_ 172 BLTN_CAM_AppNoti_PEV_NvalueSet "Parked Event notification to Connectivity Phone App. On/Off";
CM_ SG_ 172 BLTN_CAM_WiFi_AutoOn_NvalueSet "Wifi On/Off User setting";
CM_ SG_ 172 BLTN_CAM_StoProp_NvalueSet "Propotion of built-in Cam SD card Propotion set of the Recording Categories";
CM_ SG_ 172 CF_AVN_BLTN_CAM_USMReset "Buit-in Cam USM Reset Request.";
CM_ SG_ 172 CF_AVN_BLTN_CAM_RecReset "Buit-in Cam format(all file delete/Reset) Request.";
CM_ SG_ 172 BLTN_CAM_File_DEL_CPY_Cmd "Buit-in Cam operation control of copying and deleting.";
CM_ SG_ 172 BLTN_CAM_LVDS_Mode_Cmd "This Signal is for LVDS output commend to BLTN_CAM";
CM_ SG_ 172 HU_BLTN_CAM_Disp_Touch_Pos_X "X position of touch of display when BLTN-in CAM Engineer mode in";
CM_ SG_ 172 HU_BLTN_CAM_Disp_Touch_Pos_Y "Y position of touch of display when BLTN-in CAM Engineer mode in";
CM_ SG_ 172 MEV_Rec_Req "0x1(On) : MEV Record Request.";
CM_ SG_ 172 BLTN_CAM_RR_VerPos_NvalueSet "Rear Camera Vertical position setting value.";
CM_ SG_ 172 TML_Rec_Req "0x1 : Start Request, 0x2 : End Request";
CM_ SG_ 172 BLTN_CAM_SD_Card_UnMt_Mt_Req "0x0(Default), 0x1(UnMount Request), 0x2(Mount Request), 0x3(Invalid)";
CM_ BO_ 1239 "[PE] Periodic and On Event";
CM_ SG_ 1239 HU_ADMSettingState "Information for ADM(Accessry Delay Mode) Setting Vaule in HU / Made at 2021.1.25";
CM_ SG_ 1239 HU_MKBD_ModeSwitch "This signal is used for the 'AVNT/Climate Switching Keyboard' to switch the display of buttons.";
CM_ SG_ 1239 HU_VehiclePwr "Information for the H/U power status for ADM(Accessary Delay Mode)";
CM_ BO_ 1245 "[PE] Periodic and On Event";
CM_ SG_ 1245 HU_LatchHoldReq "Request Signal for Latchlod of control uni to get valid info during HU ADM condition";
CM_ SG_ 1245 HU_HighPowerChargingkW "High Power Charging Power value(kW) of charger";
CM_ SG_ 1245 HU_FastChargingkW "Fast Power Charging Power value(kW) of charger";
CM_ BO_ 1240 "[PE] Periodic and On Event";
CM_ SG_ 1240 HU_DistanceUnit "Request to set CLU Distance Unit";
CM_ SG_ 1240 HU_MicActivity "HU send this signal to eCall for MIC using status.
eCall unit stop the diagonosis when received 0x1:Activated from HU
Otherwise, eCall unit keep diagnosis every 1 sec. and HU can not use MIC";
CM_ SG_ 1240 CF_HU_GPSFlt "Information of GPS Fault 

0x0: Normal
0x1 : Fault operation
0x2 : RESERVED
0x3:Invalid";
CM_ SG_ 1240 AVN_RSPA_CancelInput "Request Signal to cancel RSPA function";
CM_ SG_ 1240 AVN_RSPA_Disp_Rdy "Signal to inform RSPA of AVN's display ready status
(RSPA È­¸é Ç¥½Ã °¡´É/ºÒ°¡´É »óÅÂ¸¦ ¾Ë¸®±â À§ÇÑ ½ÅÈ£)";
CM_ SG_ 1240 CF_AVN_ProfileIDRValue "This signal is User ID value in H/Unit.";
CM_ SG_ 1240 HazardFromHUSVM "This signal is for Hazard control";
CM_ SG_ 1240 OMUOSMirCtrl "This signal is for the OutSide Mirror Control (Fold or Unfold)";
CM_ SG_ 1240 OTAUIStatus "Information of the status of Head Unit";
CM_ SG_ 1240 C_TeleActiveStatus "This signal is for check TMS active status";
CM_ SG_ 1240 HU_AliveStatus "Information of the status of Head Unit
0x00 : Headunit is booting so, Headunit cant display any state
0x01 : Headunit is normal state, Headunit could display according to MM CAN  command.
0x02 : Headunit is doing their internal process, so Headunit cant communicate with other node.
For CLU/SCC/eCall
-AVN System transmission signal";
CM_ SG_ 1240 HU_RTCCheck "Checking whether RTC of AVN and HCU is operationg normally.";
CM_ BO_ 1247 "[PE] Periodic and On Event";
CM_ SG_ 1247 Navi_ParkingLot "Parking Lot Information";
CM_ SG_ 1247 Navi_AirConditionWarning "this signal describe the circumstance and window state.";
CM_ SG_ 1247 ADP_NActiveSound "This signal is transmitted from navigation for ADP's N Active Sound function.";
CM_ BO_ 1218 "[EC] On Event and On Change";
CM_ SG_ 1218 C_AVN_PTGHeightNValueSet "Power Tailgate(Trunk) Height Request Signal";
CM_ SG_ 1218 CF_AVN_SCCMLReset "Request for SCC-ML reset";
CM_ SG_ 1218 C_HAnBNValueSet "USM Request for Horn Feedback";
CM_ SG_ 1218 CF_AVN_RrSeatRemindNValueSet "USM Request for Rear Seat Remind function";
CM_ SG_ 1218 CF_AVN_DSWNValueSet "Request for driver state warning";
CM_ SG_ 1218 CF_AVN_RRPSU_RLNValueSet "Request for Seat easy access of rear left seat";
CM_ SG_ 1218 CF_AVN_APSUNValueSet "Request for easy access of passenger seat";
CM_ SG_ 1218 CF_AVN_NCC_CameraNValueSet "Request for Eco Vehicle NCC";
CM_ SG_ 1218 CF_AVN_RRPSU_RRNValueSet "Request for seat easy access of rear right seat";
CM_ SG_ 1218 CF_AVN_HtBlcAstNValueSet "Request for Passenger seat heater balance";
CM_ SG_ 1218 CF_AVN_HtBlcDrvNValueSet "Request for Driver seat heater balance";
CM_ SG_ 1218 CF_AVN_SCCModeNValueSet "This signal request for scc setting(Whether sccml or following driving mode)";
CM_ SG_ 1218 CF_AVN_SCCMLChar1Set "Request for scc-ml acceleration learning result change";
CM_ SG_ 1218 CF_AVN_UIPNValueSet "USM Request for Ultrasonic Intrusion Protection function";
CM_ SG_ 1218 CF_AVN_SCCMLChar2Set "Request for scc-ml distnace learning result change";
CM_ SG_ 1218 CF_AVN_SCCMLChar3Set "Request for scc-ml reaction learning result change";
CM_ SG_ 1218 CF_AVN_HDALCFuncNValueSet "Request for highway lane change assist";
CM_ BO_ 1251 "[EC] On Event and On Change";
CM_ SG_ 1251 IAU_Crc13Val "IAU_CyclicRedundancyCheck13Value";
CM_ SG_ 1251 IAU_AlvCnt13Val "IAU_AliveCounter13Value";
CM_ SG_ 1251 RSPA_FuncInfo "RSPA Function selection";
CM_ BO_ 1227 "[EC] On Event and On Change";
CM_ SG_ 1227 DrvIMS_MemoryP1Req "PSM_DriverSeatPositionMemoryP1Request";
CM_ SG_ 1227 DrvIMS_PlyBckP2Req "PSM_PlayBackP2Request";
CM_ SG_ 1227 DrvIMS_PlyBckP3Req "PSM_PlayBackP3Request";
CM_ SG_ 1227 DrvIMS_PlyBckStpReq "PSM_PlayBackStopRequest";
CM_ SG_ 1227 SmrtIMS_PlyBckReq "HCIMS_PlayBackRequest";
CM_ SG_ 1227 DrvIMS_MemoryP2Req "PSM_DriverSeatPositionMemoryP2Request";
CM_ SG_ 1227 SmrtIMS_ImgDBVal "Smart IMS image DB number";
CM_ SG_ 1227 SmrtIMS_PlyBckStpReq "HCIMS_Status";
CM_ SG_ 1227 DrvIMS_MemoryP3Req "PSM_DriverSeatPositionMemoryP3Request";
CM_ SG_ 1227 SmrtIMS_EnterSwSta "Smart IMS switch on using IMS switch";
CM_ SG_ 1227 DrvIMS_BzrReq "PSM_DriverSeatImsBuzzerRequest";
CM_ SG_ 1227 DrvIMS_ErrConWmgDis "Warning about IMS Mem/Play Error Condition";
CM_ SG_ 1227 Drv_AutoRlxWrngDis "Drive seat auto relax warning information for AVN display";
CM_ SG_ 1227 DrvIMS_AMPBzrReq "SEAT IMS Buzzer Request for AMP";
CM_ SG_ 1227 Drv_AutoRlxWrngDis_2 "Drive seat auto relax warning information for AVN display";
CM_ SG_ 1227 DrvIMS_MemorySetEnaSta "PSM_MemorySetEnableStatus";
CM_ SG_ 1227 DrvIMS_PlyBckP1Req "PSM_PlayBackP1Request";
CM_ BO_ 1252 "[EC] On Event and On Change";
CM_ SG_ 1252 RKE_Crc1Val "RKE_CyclicRedundancyCheck1Value";
CM_ SG_ 1252 RKE_AlvCnt1Val "RKE_AliveCounter1Value";
CM_ SG_ 1252 RKE_BtnReq "RemoteKey_ButtonRequest ##2G##BCM - BCMmsg01 - C_RKECmd";
CM_ SG_ 1252 RKE_PsdBtnReq "RemoteKey_PowerSlindingDoorButtonRequest ##2G##BCM - BCMmsg01 - C_RKEPSDCmd";
CM_ SG_ 1252 RKE_WdwUpDnReq "RemoteKey_WindowUpDownRequest ##2G##BCM - BCMmsg01 - C_WdwComfortCMDBCM";
CM_ SG_ 1252 RKE_TrnkTlgtBtnReq "RemoteKey_Trunk/TailgateButtonRequest ##2G##BCM - BCMmsg01 - C_TailgateTrunkRKECMD";
CM_ SG_ 1252 RKE_ID "RemoteKey_ID ##2G##BCM - BCMmsg01 - C_BCMRKEID";
CM_ BO_ 1253 "[EC] On Event and On Change";
CM_ SG_ 1253 SMK_Crc1Val "SMK_CyclicRedundancyCheck1Value";
CM_ SG_ 1253 SMK_AlvCnt1Val "SMK_AliveCounter1Value";
CM_ SG_ 1253 DoorLock_PsvDrLkReq "DoorLock_PassiveDoorLockRequest ##2G##SMK - SMKmsg01 - C_PassiveAccessLock";
CM_ SG_ 1253 DoorLock_PsvDrUnLkReq "DoorLock_PassiveDoorUnLockRequest ##2G##SMK - SMKmsg01 - C_PassiveAccessUnlock";
CM_ SG_ 1253 DoorLock_DrvDrPsvAcsReq "DoorLock_DriverDoorPassiveAccessRequest ##2G##SMK - SMKmsg01 - C_PassiveFrtDrv";
CM_ SG_ 1253 DoorLock_AsstDrPsvAcsReq "DoorLock_AssistDoorPassiveAccessRequest ##2G##SMK - SMKmsg01 - C_PassiveFrtAst";
CM_ SG_ 1253 DoorLock_TrnkTlgtPsvAcsReq "DoorLock_TrunkTailgatePassiveAccessRequest ##2G##SMK - SMKmsg01 - C_PassiveTrunkTg";
CM_ SG_ 1253 DoorLock_RrLftDrPsvAcsReq "DoorLock_RearLeftDoorPassiveAccessRequest ##2G##SMK - SMKmsg01 - C_PassiveRrDrv";
CM_ SG_ 1253 DoorLock_RrRtDrPsvAcsReq "DoorLock_RearRightDoorPassiveAccessRequest ##2G##SMK - SMKmsg01 - C_PassiveRrAst";
CM_ SG_ 1253 DoorLock_PsdPsvAcsReq "DoorLock_PowerSlidingDoorPassiveAccessRequest ##2G##SMK - SMKmsg01 - C_PassivePSD";
CM_ SG_ 1253 Auth_Req "Authentication_Request ##2G##SMK - SMKmsg03 - C_SMK_AuthReq";
CM_ SG_ 1253 RSPA_DigitalKeyAuth "2G##SMK - SMKmsg01 - C_RSPADigitalKeyAuth";
CM_ SG_ 1253 Auth_Method "Authentication_Request ##2G##SMK - SMKmsg01 -C_SMK_AuthMethod";
CM_ SG_ 1253 DoorLock_StrgbxPsvAcsReq "DoorLock_StorageBoxPassiveAccessRequest";
CM_ SG_ 1253 Auth_ISKLearnFdbck "Authentication_Request ##2G##SMK - SMKmsg01 - C_IBUISKLearnFB";
CM_ BO_ 1237 "[EC] On Event and On Change";
CM_ SG_ 1237 SWRC_Crc2Val "SWRC_CyclicRedundancyCheck2Value";
CM_ SG_ 1237 SWRC_AlvCnt2Val "SWRC_AliveCounter2Value";
CM_ SG_ 1237 Audio_VolEncoderSta "Audio_VolumeScrollSwitchStatus";
CM_ SG_ 1237 Cluster_ScrlEncoderSta "Cluster_ScrollSwitchStatus";
CM_ BO_ 139 "[PE] Periodic and On Event";
CM_ SG_ 139 SWRC_Crc5Val "SWRC_CyclicRedundancyCheck5Value";
CM_ SG_ 139 SWRC_AlvCnt5Val "SWRC_AliveCounter5Value";
CM_ SG_ 139 SWRC_4wdLocking "4wd locking on/off signal";
BA_DEF_ BO_ "DiagState" ENUM "No","Yes" ;
BA_DEF_ BO_ "DiagResponse" ENUM "No","Yes" ;
BA_DEF_ BO_ "DiagRequest" ENUM "No","Yes" ;
BA_DEF_ BO_ "TpMessage" ENUM "No","Yes" ;
BA_DEF_ BO_ "UsrMsgIDSforwardDeviation" INT 0 100 ;
BA_DEF_ BO_ "UsrMsgIDSbackwardDeviation" INT 50 1000 ;
BA_DEF_ BO_ "GenMsgCycleTime" INT 0 2000 ;
BA_DEF_ BO_ "GenMsgStartDelayTime" INT 0 2000 ;
BA_DEF_ BO_ "GenMsgSendType" ENUM "Cyclic","NoMsgSendType" ;
BA_DEF_ BO_ "GenMsgCycleTimeFast" INT 0 500 ;
BA_DEF_ BO_ "GenMsgDelayTime" INT 0 20 ;
BA_DEF_ BO_ "GenMsgILSupport" ENUM "No","Yes" ;
BA_DEF_ BO_ "GenMsgNrOfRepetition" INT 0 3 ;
BA_DEF_ BO_ "NmMessage" ENUM "No","Yes" ;
BA_DEF_ BO_ "NWM-Botschaft" ENUM "No","Yes" ;
BA_DEF_ BO_ "TpTxIndex" INT 0 65535 ;
BA_DEF_ BO_ "VFrameFormat" ENUM "StandardCAN","ExtendedCAN","reserved","reserved","reserved","reserved","reserved","reserved","reserved","reserved","reserved","reserved","reserved","reserved","StandardCAN_FD","ExtendedCAN_FD" ;
BA_DEF_ SG_ "UserSigValidity" ENUM "B+","ACC","IG","IG1","IG2","IG3","IG1 or IG2","IG1 or IG3","Undef" ;
BA_DEF_ SG_ "TimeoutValue" STRING ;
BA_DEF_ SG_ "UsrSigPurpose" ENUM "Undef","FN","DIAG","DIAG(Req)","DIAG(Res)","DIAG(Phy)","DEV","CCP(Req)","CCP(Res)","NM","TP" ;
BA_DEF_ SG_ "GenSigStartValue" INT 0 1215752192 ;
BA_DEF_ SG_ "NetworkRequest" ENUM "Yes","No" ;
BA_DEF_ SG_ "NetworkRequestHoldingTime" INT 0 65535 ;
BA_DEF_ SG_ "Description" STRING ;
BA_DEF_ SG_ "Version" STRING ;
BA_DEF_ SG_ "GenSigEnvVarType" ENUM "Int","Float","Undef" ;
BA_DEF_ SG_ "GenSigSendType" ENUM "Cyclic","OnWrite","OnWriteWithRepetition","OnChange","OnChangeWithRepetition","IfActive","IfActiveWithRepetition","NoSigSendType","OnChangeAndIfActive","OnChangeAndIfActiveWithRepetition" ;
BA_DEF_ SG_ "GwSigLatencyTime" INT 0 65536 ;
BA_DEF_ SG_ "GwSigMissingSourceType" ENUM "Undef","OldValue","DefaultValue","InitialValue" ;
BA_DEF_ SG_ "NWM-WakeupAllowed" ENUM "<n.a.>" ;
BA_DEF_ SG_ "RoutingFactor" INT 1 1215752192 ;
BA_DEF_REL_ BU_SG_REL_ "GenSigTimeoutTime" INT 0 7000 ;
BA_DEF_DEF_ "DiagState" "No" ;
BA_DEF_DEF_ "DiagResponse" "No" ;
BA_DEF_DEF_ "DiagRequest" "No" ;
BA_DEF_DEF_ "TpMessage" "No" ;
BA_DEF_DEF_ "UsrMsgIDSforwardDeviation" 10 ;
BA_DEF_DEF_ "UsrMsgIDSbackwardDeviation" 100 ;
BA_DEF_DEF_ "GenMsgCycleTime" 200 ;
BA_DEF_DEF_ "GenMsgStartDelayTime" 0 ;
BA_DEF_DEF_ "GenMsgSendType" "NoMsgSendType" ;
BA_DEF_DEF_ "GenMsgCycleTimeFast" 40 ;
BA_DEF_DEF_ "GenMsgDelayTime" 20 ;
BA_DEF_DEF_ "GenMsgILSupport" "Yes" ;
BA_DEF_DEF_ "GenMsgNrOfRepetition" 3 ;
BA_DEF_DEF_ "NmMessage" "No" ;
BA_DEF_DEF_ "NWM-Botschaft" "No" ;
BA_DEF_DEF_ "TpTxIndex" 0 ;
BA_DEF_DEF_ "VFrameFormat" "StandardCAN" ;
BA_DEF_DEF_ "UserSigValidity" "IG" ;
BA_DEF_DEF_ "TimeoutValue" "" ;
BA_DEF_DEF_ "UsrSigPurpose" "FN" ;
BA_DEF_DEF_ "GenSigStartValue" 0 ;
BA_DEF_DEF_ "NetworkRequest" "No" ;
BA_DEF_DEF_ "NetworkRequestHoldingTime" 0 ;
BA_DEF_DEF_ "Description" "" ;
BA_DEF_DEF_ "Version" "" ;
BA_DEF_DEF_ "GenSigEnvVarType" "Undef" ;
BA_DEF_DEF_ "GenSigSendType" "NoSigSendType" ;
BA_DEF_DEF_ "GwSigLatencyTime" 40 ;
BA_DEF_DEF_ "GwSigMissingSourceType" "Undef" ;
BA_DEF_DEF_ "NWM-WakeupAllowed" "<n.a.>" ;
BA_DEF_DEF_ "RoutingFactor" 1 ;
BA_DEF_DEF_REL_ "GenSigTimeoutTime" 500 ;
BA_ "GenMsgCycleTime" BO_ 140 0;
BA_ "Description" SG_ 140 ATS_DATC_FrPsModeSet "Àü¼® Á¶¼ö¼® Ãø ¸ðµå ¼³Á¤";
BA_ "GenSigSendType" SG_ 140 ATS_DATC_FrPsModeSet 4;
BA_ "UserSigValidity" SG_ 140 ATS_DATC_FrPsModeSet 3;
BA_REL_ "GenSigTimeoutTime" BU_SG_REL_ CGW_CCU SG_ 140 ATS_DATC_FrPsModeSet 0;
BA_ "Version" SG_ 140 ATS_DATC_FrPsModeSet "19.12.08";
BA_ "Description" SG_ 140 ATS_DATC_FrPsAutoSet "Àü¼® Á¶¼ö¼® Ãø AUTO ¼³Á¤";
BA_ "GenSigSendType" SG_ 140 ATS_DATC_FrPsAutoSet 4;
BA_ "UserSigValidity" SG_ 140 ATS_DATC_FrPsAutoSet 3;
BA_REL_ "GenSigTimeoutTime" BU_SG_REL_ CGW_CCU SG_ 140 ATS_DATC_FrPsAutoSet 0;
BA_ "Version" SG_ 140 ATS_DATC_FrPsAutoSet "19.12.08";
BA_ "Description" SG_ 140 ATS_DATC_FrPsBlowerSet "Àü¼® Á¶¼ö¼® Ãø ºí·Î¿ö ´Ü¼ö ¼³Á¤";
BA_ "GenSigSendType" SG_ 140 ATS_DATC_FrPsBlowerSet 4;
BA_ "GenSigStartValue" SG_ 140 ATS_DATC_FrPsBlowerSet 15;
BA_ "UserSigValidity" SG_ 140 ATS_DATC_FrPsBlowerSet 3;
BA_REL_ "GenSigTimeoutTime" BU_SG_REL_ CGW_CCU SG_ 140 ATS_DATC_FrPsBlowerSet 0;
BA_ "Version" SG_ 140 ATS_DATC_FrPsBlowerSet "19.12.08";
BA_ "Description" SG_ 140 ATS_DATC_FrPsBlowerUpDn "Àü¼® Á¶¼ö¼® Ãø ºí·Î¿ö Áõ°¨ ¼³Á¤";
BA_ "GenSigSendType" SG_ 140 ATS_DATC_FrPsBlowerUpDn 4;
BA_ "UserSigValidity" SG_ 140 ATS_DATC_FrPsBlowerUpDn 3;
BA_REL_ "GenSigTimeoutTime" BU_SG_REL_ CGW_CCU SG_ 140 ATS_DATC_FrPsBlowerUpDn 0;
BA_ "Version" SG_ 140 ATS_DATC_FrPsBlowerUpDn "19.12.08";
BA_ "Description" SG_ 140 ATS_DATC_FrDrMultiAutoBlower "Àü¼® ¿îÀü¼® Ãø ¸ÖÆ¼¿ÀÅäºí·Î¿ö ¼³Á¤";
BA_ "GenSigSendType" SG_ 140 ATS_DATC_FrDrMultiAutoBlower 4;
BA_ "UserSigValidity" SG_ 140 ATS_DATC_FrDrMultiAutoBlower 3;
BA_REL_ "GenSigTimeoutTime" BU_SG_REL_ CGW_CCU SG_ 140 ATS_DATC_FrDrMultiAutoBlower 0;
BA_ "Version" SG_ 140 ATS_DATC_FrDrMultiAutoBlower "19.12.08";
BA_ "Description" SG_ 140 ATS_DATC_FrPsMultiAutoBlower "Àü¼® Á¶¼ö¼® Ãø ¸ÖÆ¼¿ÀÅäºí·Î¿ö ¼³Á¤";
BA_ "GenSigSendType" SG_ 140 ATS_DATC_FrPsMultiAutoBlower 4;
BA_ "UserSigValidity" SG_ 140 ATS_DATC_FrPsMultiAutoBlower 3;
BA_REL_ "GenSigTimeoutTime" BU_SG_REL_ CGW_CCU SG_ 140 ATS_DATC_FrPsMultiAutoBlower 0;
BA_ "Version" SG_ 140 ATS_DATC_FrPsMultiAutoBlower "19.12.08";
BA_ "Description" SG_ 140 ATS_DATC_RrDrMultiAutoBlower "ÈÄ¼® ¿îÀü¼® Ãø ¸ÖÆ¼¿ÀÅäºí·Î¿ö ¼³Á¤";
BA_ "GenSigSendType" SG_ 140 ATS_DATC_RrDrMultiAutoBlower 4;
BA_ "UserSigValidity" SG_ 140 ATS_DATC_RrDrMultiAutoBlower 3;
BA_REL_ "GenSigTimeoutTime" BU_SG_REL_ CGW_CCU SG_ 140 ATS_DATC_RrDrMultiAutoBlower 0;
BA_ "Version" SG_ 140 ATS_DATC_RrDrMultiAutoBlower "19.12.08";
BA_ "Description" SG_ 140 ATS_DATC_FragranceStrhSet "Fragrance Strength Set (¹ßÇâ ±â´É Çâ ¼¼±â ¼³Á¤)";
BA_ "GenSigSendType" SG_ 140 ATS_DATC_FragranceStrhSet 4;
BA_ "GenSigStartValue" SG_ 140 ATS_DATC_FragranceStrhSet 7;
BA_ "UserSigValidity" SG_ 140 ATS_DATC_FragranceStrhSet 3;
BA_REL_ "GenSigTimeoutTime" BU_SG_REL_ CGW_CCU SG_ 140 ATS_DATC_FragranceStrhSet 0;
BA_ "Version" SG_ 140 ATS_DATC_FragranceStrhSet "20.03.01";
BA_ "Description" SG_ 140 ATS_DATC_FragranceKindSet "Fragrance Kind Set (¹ßÇâ ±â´É Çâ Á¾·ù ¼³Á¤)";
BA_ "GenSigSendType" SG_ 140 ATS_DATC_FragranceKindSet 4;
BA_ "GenSigStartValue" SG_ 140 ATS_DATC_FragranceKindSet 7;
BA_ "UserSigValidity" SG_ 140 ATS_DATC_FragranceKindSet 3;
BA_REL_ "GenSigTimeoutTime" BU_SG_REL_ CGW_CCU SG_ 140 ATS_DATC_FragranceKindSet 0;
BA_ "Version" SG_ 140 ATS_DATC_FragranceKindSet "20.03.01";
BA_ "Description" SG_ 140 ATS_DATC_FragranceBttnMnlSet "Fragrance Button Manual Set (¹ßÇâ ±â´É ¹öÆ° ¼öµ¿ ÀÔ·Â)";
BA_ "GenSigSendType" SG_ 140 ATS_DATC_FragranceBttnMnlSet 4;
BA_ "GenSigStartValue" SG_ 140 ATS_DATC_FragranceBttnMnlSet 3;
BA_ "UserSigValidity" SG_ 140 ATS_DATC_FragranceBttnMnlSet 3;
BA_REL_ "GenSigTimeoutTime" BU_SG_REL_ CGW_CCU SG_ 140 ATS_DATC_FragranceBttnMnlSet 0;
BA_ "Version" SG_ 140 ATS_DATC_FragranceBttnMnlSet "20.03.01";
BA_ "Description" SG_ 140 ATS_DATC_TempUnitSet "Temp Unit Set (¿Âµµ ´ÜÀ§ ¼³Á¤)";
BA_ "GenSigSendType" SG_ 140 ATS_DATC_TempUnitSet 4;
BA_ "GenSigStartValue" SG_ 140 ATS_DATC_TempUnitSet 3;
BA_ "UserSigValidity" SG_ 140 ATS_DATC_TempUnitSet 3;
BA_REL_ "GenSigTimeoutTime" BU_SG_REL_ CGW_CCU SG_ 140 ATS_DATC_TempUnitSet 0;
BA_ "Version" SG_ 140 ATS_DATC_TempUnitSet "20.04.02";
BA_ "GenMsgCycleTime" BO_ 158 0;
BA_ "Description" SG_ 158 ATS_DATC_FrDrBlowerSet "Àü¼® ¿îÀü¼® Ãø ºí·Î¿ö ´Ü¼ö ¼³Á¤";
BA_ "GenSigSendType" SG_ 158 ATS_DATC_FrDrBlowerSet 4;
BA_ "GenSigStartValue" SG_ 158 ATS_DATC_FrDrBlowerSet 15;
BA_ "UserSigValidity" SG_ 158 ATS_DATC_FrDrBlowerSet 3;
BA_REL_ "GenSigTimeoutTime" BU_SG_REL_ CGW_CCU SG_ 158 ATS_DATC_FrDrBlowerSet 0;
BA_ "Version" SG_ 158 ATS_DATC_FrDrBlowerSet "19.12.08";
BA_ "Description" SG_ 158 ATS_DATC_RrDrTempUpDn "ÈÄ¼® ¿îÀü¼® Ãø ¼³Á¤¿Âµµ Áõ°¨ ¼³Á¤";
BA_ "GenSigSendType" SG_ 158 ATS_DATC_RrDrTempUpDn 4;
BA_ "UserSigValidity" SG_ 158 ATS_DATC_RrDrTempUpDn 3;
BA_REL_ "GenSigTimeoutTime" BU_SG_REL_ CGW_CCU SG_ 158 ATS_DATC_RrDrTempUpDn 0;
BA_ "Version" SG_ 158 ATS_DATC_RrDrTempUpDn "19.12.08";
BA_ "Description" SG_ 158 ATS_DATC_RrDrBlowerSet "ÈÄ¼® ¿îÀü¼® Ãø ºí·Î¿ö Áõ°¨ ¼³Á¤";
BA_ "GenSigSendType" SG_ 158 ATS_DATC_RrDrBlowerSet 4;
BA_ "GenSigStartValue" SG_ 158 ATS_DATC_RrDrBlowerSet 15;
BA_ "UserSigValidity" SG_ 158 ATS_DATC_RrDrBlowerSet 3;
BA_REL_ "GenSigTimeoutTime" BU_SG_REL_ CGW_CCU SG_ 158 ATS_DATC_RrDrBlowerSet 0;
BA_ "Version" SG_ 158 ATS_DATC_RrDrBlowerSet "19.12.08";
BA_ "Description" SG_ 158 ATS_DATC_RrDrModeSet "ÈÄ¼® ¿îÀü¼® Ãø ¸ðµå ¼³Á¤";
BA_ "GenSigSendType" SG_ 158 ATS_DATC_RrDrModeSet 4;
BA_ "GenSigStartValue" SG_ 158 ATS_DATC_RrDrModeSet 15;
BA_ "UserSigValidity" SG_ 158 ATS_DATC_RrDrModeSet 3;
BA_REL_ "GenSigTimeoutTime" BU_SG_REL_ CGW_CCU SG_ 158 ATS_DATC_RrDrModeSet 0;
BA_ "Version" SG_ 158 ATS_DATC_RrDrModeSet "19.12.08";
BA_ "Description" SG_ 158 ATS_DATC_FrDrModeSet "Àü¼® ¿îÀü¼® Ãø ¸ðµå ¼³Á¤";
BA_ "GenSigSendType" SG_ 158 ATS_DATC_FrDrModeSet 4;
BA_ "UserSigValidity" SG_ 158 ATS_DATC_FrDrModeSet 3;
BA_REL_ "GenSigTimeoutTime" BU_SG_REL_ CGW_CCU SG_ 158 ATS_DATC_FrDrModeSet 0;
BA_ "Version" SG_ 158 ATS_DATC_FrDrModeSet "19.12.08";
BA_ "Description" SG_ 158 ATS_DATC_RrOnOffSet "ÈÄ¼® °øÁ¶ ¿Â¿ÀÇÁ ¼³Á¤";
BA_ "GenSigSendType" SG_ 158 ATS_DATC_RrOnOffSet 4;
BA_ "GenSigStartValue" SG_ 158 ATS_DATC_RrOnOffSet 3;
BA_ "UserSigValidity" SG_ 158 ATS_DATC_RrOnOffSet 3;
BA_ "Version" SG_ 158 ATS_DATC_RrOnOffSet "19.12.08";
BA_ "Description" SG_ 158 ATS_DATC_IntakeSet "³»¿Ü±â ¼³Á¤";
BA_ "GenSigSendType" SG_ 158 ATS_DATC_IntakeSet 4;
BA_ "GenSigStartValue" SG_ 158 ATS_DATC_IntakeSet 3;
BA_ "UserSigValidity" SG_ 158 ATS_DATC_IntakeSet 3;
BA_REL_ "GenSigTimeoutTime" BU_SG_REL_ CGW_CCU SG_ 158 ATS_DATC_IntakeSet 0;
BA_ "Version" SG_ 158 ATS_DATC_IntakeSet "19.12.08";
BA_ "Description" SG_ 158 ATS_DATC_OffReq "Àü¼® °øÁ¶ ¿ÀÇÁ ¼³Á¤";
BA_ "GenSigSendType" SG_ 158 ATS_DATC_OffReq 4;
BA_ "UserSigValidity" SG_ 158 ATS_DATC_OffReq 3;
BA_ "Version" SG_ 158 ATS_DATC_OffReq "19.12.08";
BA_ "Description" SG_ 158 ATS_DATC_FrDrAutoSet "Àü¼® ¿îÀü¼® Ãø AUTO ¼³Á¤";
BA_ "GenSigSendType" SG_ 158 ATS_DATC_FrDrAutoSet 4;
BA_ "UserSigValidity" SG_ 158 ATS_DATC_FrDrAutoSet 3;
BA_REL_ "GenSigTimeoutTime" BU_SG_REL_ CGW_CCU SG_ 158 ATS_DATC_FrDrAutoSet 0;
BA_ "Version" SG_ 158 ATS_DATC_FrDrAutoSet "19.12.08";
BA_ "Description" SG_ 158 ATS_DATC_FrPsTempUpDn "Àü¼® Á¶¼ö¼® Ãø ¼³Á¤¿Âµµ Áõ°¨ ¼³Á¤";
BA_ "GenSigSendType" SG_ 158 ATS_DATC_FrPsTempUpDn 4;
BA_ "UserSigValidity" SG_ 158 ATS_DATC_FrPsTempUpDn 3;
BA_REL_ "GenSigTimeoutTime" BU_SG_REL_ CGW_CCU SG_ 158 ATS_DATC_FrPsTempUpDn 0;
BA_ "Version" SG_ 158 ATS_DATC_FrPsTempUpDn "19.12.08";
BA_ "Description" SG_ 158 ATS_DATC_FrDefog "Àü¼® DEF ¼³Á¤";
BA_ "GenSigSendType" SG_ 158 ATS_DATC_FrDefog 4;
BA_ "GenSigStartValue" SG_ 158 ATS_DATC_FrDefog 3;
BA_ "UserSigValidity" SG_ 158 ATS_DATC_FrDefog 3;
BA_REL_ "GenSigTimeoutTime" BU_SG_REL_ CGW_CCU SG_ 158 ATS_DATC_FrDefog 0;
BA_ "Version" SG_ 158 ATS_DATC_FrDefog "19.12.08";
BA_ "Description" SG_ 158 ATS_DATC_RrSyncSet "ÈÄ¼® SYNC ¼³Á¤";
BA_ "GenSigSendType" SG_ 158 ATS_DATC_RrSyncSet 4;
BA_ "UserSigValidity" SG_ 158 ATS_DATC_RrSyncSet 3;
BA_REL_ "GenSigTimeoutTime" BU_SG_REL_ CGW_CCU SG_ 158 ATS_DATC_RrSyncSet 0;
BA_ "Version" SG_ 158 ATS_DATC_RrSyncSet "19.12.08";
BA_ "Description" SG_ 158 ATS_DATC_AcSet "AC ¼³Á¤";
BA_ "GenSigSendType" SG_ 158 ATS_DATC_AcSet 4;
BA_ "GenSigStartValue" SG_ 158 ATS_DATC_AcSet 3;
BA_ "UserSigValidity" SG_ 158 ATS_DATC_AcSet 3;
BA_REL_ "GenSigTimeoutTime" BU_SG_REL_ CGW_CCU SG_ 158 ATS_DATC_AcSet 0;
BA_ "Version" SG_ 158 ATS_DATC_AcSet "19.12.08";
BA_ "Description" SG_ 158 ATS_DATC_AirCleaningSet "°ø±âÃ»Á¤¸ðµå ¼³Á¤";
BA_ "GenSigSendType" SG_ 158 ATS_DATC_AirCleaningSet 4;
BA_ "GenSigStartValue" SG_ 158 ATS_DATC_AirCleaningSet 3;
BA_ "UserSigValidity" SG_ 158 ATS_DATC_AirCleaningSet 3;
BA_REL_ "GenSigTimeoutTime" BU_SG_REL_ CGW_CCU SG_ 158 ATS_DATC_AirCleaningSet 0;
BA_ "Version" SG_ 158 ATS_DATC_AirCleaningSet "19.12.08";
BA_ "Description" SG_ 158 ATS_DATC_FrDrBlowerUpDn "Àü¼® ¿îÀü¼® Ãø ºí·Î¿ö Áõ°¨ ¼³Á¤";
BA_ "GenSigSendType" SG_ 158 ATS_DATC_FrDrBlowerUpDn 4;
BA_ "UserSigValidity" SG_ 158 ATS_DATC_FrDrBlowerUpDn 3;
BA_REL_ "GenSigTimeoutTime" BU_SG_REL_ CGW_CCU SG_ 158 ATS_DATC_FrDrBlowerUpDn 0;
BA_ "Version" SG_ 158 ATS_DATC_FrDrBlowerUpDn "19.12.08";
BA_ "Description" SG_ 158 ATS_DATC_FrDrTempUpDn "Àü¼® ¿îÀü¼® Ãø ¼³Á¤¿Âµµ Áõ°¨ ¼³Á¤";
BA_ "GenSigSendType" SG_ 158 ATS_DATC_FrDrTempUpDn 4;
BA_ "UserSigValidity" SG_ 158 ATS_DATC_FrDrTempUpDn 3;
BA_REL_ "GenSigTimeoutTime" BU_SG_REL_ CGW_CCU SG_ 158 ATS_DATC_FrDrTempUpDn 0;
BA_ "Version" SG_ 158 ATS_DATC_FrDrTempUpDn "19.12.08";
BA_ "Description" SG_ 158 ATS_DATC_RrDrAutoSet "ÈÄ¼® ¿îÀü¼® Ãø AUTO ¼³Á¤";
BA_ "GenSigSendType" SG_ 158 ATS_DATC_RrDrAutoSet 4;
BA_ "GenSigStartValue" SG_ 158 ATS_DATC_RrDrAutoSet 3;
BA_ "UserSigValidity" SG_ 158 ATS_DATC_RrDrAutoSet 3;
BA_REL_ "GenSigTimeoutTime" BU_SG_REL_ CGW_CCU SG_ 158 ATS_DATC_RrDrAutoSet 0;
BA_ "Version" SG_ 158 ATS_DATC_RrDrAutoSet "19.12.08";
BA_ "GenMsgCycleTime" BO_ 157 0;
BA_ "Description" SG_ 157 ATS_DATC_FrDrTempSetC "Àü¼® ¿îÀü¼® Ãø ¼³Á¤¿Âµµ°ª(¼·¾¾) ¼³Á¤";
BA_ "GenSigSendType" SG_ 157 ATS_DATC_FrDrTempSetC 4;
BA_ "GenSigStartValue" SG_ 157 ATS_DATC_FrDrTempSetC 255;
BA_ "UserSigValidity" SG_ 157 ATS_DATC_FrDrTempSetC 3;
BA_REL_ "GenSigTimeoutTime" BU_SG_REL_ CGW_CCU SG_ 157 ATS_DATC_FrDrTempSetC 0;
BA_ "Version" SG_ 157 ATS_DATC_FrDrTempSetC "19.12.08";
BA_ "Description" SG_ 157 ATS_DATC_RrDrBlowerUpDn "ÈÄ¼® ¿îÀü¼® Ãø ºí·Î¿ö Áõ°¨ ¼³Á¤";
BA_ "GenSigSendType" SG_ 157 ATS_DATC_RrDrBlowerUpDn 4;
BA_ "UserSigValidity" SG_ 157 ATS_DATC_RrDrBlowerUpDn 3;
BA_REL_ "GenSigTimeoutTime" BU_SG_REL_ CGW_CCU SG_ 157 ATS_DATC_RrDrBlowerUpDn 0;
BA_ "Version" SG_ 157 ATS_DATC_RrDrBlowerUpDn "19.12.08";
BA_ "Description" SG_ 157 ATS_DATC_FrSyncSet "Àü¼® SYNC ¼³Á¤";
BA_ "GenSigSendType" SG_ 157 ATS_DATC_FrSyncSet 4;
BA_ "UserSigValidity" SG_ 157 ATS_DATC_FrSyncSet 3;
BA_REL_ "GenSigTimeoutTime" BU_SG_REL_ CGW_CCU SG_ 157 ATS_DATC_FrSyncSet 0;
BA_ "Version" SG_ 157 ATS_DATC_FrSyncSet "19.12.08";
BA_ "Description" SG_ 157 ATS_DATC_RrDrTempSetC "ÈÄ¼® ¿îÀü¼® Ãø ¼³Á¤¿Âµµ°ª(¼·¾¾) ¼³Á¤";
BA_ "GenSigSendType" SG_ 157 ATS_DATC_RrDrTempSetC 4;
BA_ "GenSigStartValue" SG_ 157 ATS_DATC_RrDrTempSetC 255;
BA_ "UserSigValidity" SG_ 157 ATS_DATC_RrDrTempSetC 3;
BA_REL_ "GenSigTimeoutTime" BU_SG_REL_ CGW_CCU SG_ 157 ATS_DATC_RrDrTempSetC 0;
BA_ "Version" SG_ 157 ATS_DATC_RrDrTempSetC "19.12.08";
BA_ "Description" SG_ 157 ATS_DATC_RrDrTempSetF "ÈÄ¼® ¿îÀü¼® Ãø ¼³Á¤¿Âµµ°ª(È­¾¾) ¼³Á¤";
BA_ "GenSigSendType" SG_ 157 ATS_DATC_RrDrTempSetF 4;
BA_ "GenSigStartValue" SG_ 157 ATS_DATC_RrDrTempSetF 255;
BA_ "UserSigValidity" SG_ 157 ATS_DATC_RrDrTempSetF 3;
BA_REL_ "GenSigTimeoutTime" BU_SG_REL_ CGW_CCU SG_ 157 ATS_DATC_RrDrTempSetF 0;
BA_ "Version" SG_ 157 ATS_DATC_RrDrTempSetF "19.12.08";
BA_ "Description" SG_ 157 ATS_DATC_FrPsTempSetC "Àü¼® Á¶¼ö¼® Ãø ¼³Á¤¿Âµµ°ª(¼·¾¾) ¼³Á¤";
BA_ "GenSigSendType" SG_ 157 ATS_DATC_FrPsTempSetC 4;
BA_ "GenSigStartValue" SG_ 157 ATS_DATC_FrPsTempSetC 255;
BA_ "UserSigValidity" SG_ 157 ATS_DATC_FrPsTempSetC 3;
BA_REL_ "GenSigTimeoutTime" BU_SG_REL_ CGW_CCU SG_ 157 ATS_DATC_FrPsTempSetC 0;
BA_ "Version" SG_ 157 ATS_DATC_FrPsTempSetC "19.12.08";
BA_ "Description" SG_ 157 ATS_DATC_FrPsTempSetF "Àü¼® Á¶¼ö¼® Ãø ¼³Á¤¿Âµµ°ª(È­¾¾) ¼³Á¤";
BA_ "GenSigSendType" SG_ 157 ATS_DATC_FrPsTempSetF 4;
BA_ "GenSigStartValue" SG_ 157 ATS_DATC_FrPsTempSetF 255;
BA_ "UserSigValidity" SG_ 157 ATS_DATC_FrPsTempSetF 3;
BA_REL_ "GenSigTimeoutTime" BU_SG_REL_ CGW_CCU SG_ 157 ATS_DATC_FrPsTempSetF 0;
BA_ "Version" SG_ 157 ATS_DATC_FrPsTempSetF "19.12.08";
BA_ "Description" SG_ 157 ATS_DATC_FrDrTempSetF "Àü¼® ¿îÀü¼® Ãø ¼³Á¤¿Âµµ°ª(È­¾¾) ¼³Á¤";
BA_ "GenSigSendType" SG_ 157 ATS_DATC_FrDrTempSetF 4;
BA_ "GenSigStartValue" SG_ 157 ATS_DATC_FrDrTempSetF 255;
BA_ "UserSigValidity" SG_ 157 ATS_DATC_FrDrTempSetF 3;
BA_REL_ "GenSigTimeoutTime" BU_SG_REL_ CGW_CCU SG_ 157 ATS_DATC_FrDrTempSetF 0;
BA_ "Version" SG_ 157 ATS_DATC_FrDrTempSetF "19.12.08";
BA_ "GenMsgCycleTime" BO_ 1216 0;
BA_ "Description" SG_ 1216 BCM_Crc1Val "The data area for CRC calculation is based on the data length (DLC) of the message DB.

The CRC shall be calculated over the entire data block (excluding the CRC bytes) including the user data, alive counter and Data ID 

 

- CRC Polynomial (0x1D) , Initial Value : 0x00, XOR value : 0xFF, Data ID Mode : Both, Data ID : Message ID + 0xF800 

- The initial value is for CRC calculation and the message should be sent with the calculated result value. 

The mathematical expression to 8 bit CRC polynomial is given here. G(x) = x8 + x4 + x3 + x2 + 1";
BA_ "GenSigSendType" SG_ 1216 BCM_Crc1Val 4;
BA_ "UserSigValidity" SG_ 1216 BCM_Crc1Val 0;
BA_ "Version" SG_ 1216 BCM_Crc1Val "21.09.03";
BA_ "Description" SG_ 1216 BCM_AlvCnt1Val "For the first transmission request for a data element the counter shall be initialized with 0 and shall be incremented by 1

for every subsequent send request. When the counter reaches the maximum value(0xE), then it shall restart with 0 for the next send request";
BA_ "GenSigSendType" SG_ 1216 BCM_AlvCnt1Val 4;
BA_ "UserSigValidity" SG_ 1216 BCM_AlvCnt1Val 0;
BA_ "Version" SG_ 1216 BCM_AlvCnt1Val "21.09.03";
BA_ "Description" SG_ 1216 PHEV_FuelDrReleaseSwSta "PHEV Fuel Filler Door Release SW State

- BDC transmits 0x1 value when the circuit (h/wire) between switch and BDC is connected. If it is not connected (e.g., FCS applied), BDC always transmits 0x0 default value.";
BA_ "GenSigSendType" SG_ 1216 PHEV_FuelDrReleaseSwSta 4;
BA_ "UserSigValidity" SG_ 1216 PHEV_FuelDrReleaseSwSta 0;
BA_ "NetworkRequest" SG_ 1216 PHEV_FuelDrReleaseSwSta 0;
BA_ "NetworkRequestHoldingTime" SG_ 1216 PHEV_FuelDrReleaseSwSta 5000;
BA_ "Version" SG_ 1216 PHEV_FuelDrReleaseSwSta "23.10.01";
BA_ "Description" SG_ 1216 StrWhlWrmr_MKBDBpReq "Steering Wheel Warmer Switch Beep Command";
BA_ "GenSigSendType" SG_ 1216 StrWhlWrmr_MKBDBpReq 4;
BA_ "UserSigValidity" SG_ 1216 StrWhlWrmr_MKBDBpReq 0;
BA_ "NetworkRequest" SG_ 1216 StrWhlWrmr_MKBDBpReq 0;
BA_ "NetworkRequestHoldingTime" SG_ 1216 StrWhlWrmr_MKBDBpReq 5000;
BA_ "Version" SG_ 1216 StrWhlWrmr_MKBDBpReq "20.08.02";
BA_ "Description" SG_ 1216 BckGls_RrGlsHtdMKBDBpReq "Rear Glass Heated Switch Beep Request";
BA_ "GenSigSendType" SG_ 1216 BckGls_RrGlsHtdMKBDBpReq 4;
BA_ "UserSigValidity" SG_ 1216 BckGls_RrGlsHtdMKBDBpReq 0;
BA_ "NetworkRequest" SG_ 1216 BckGls_RrGlsHtdMKBDBpReq 0;
BA_ "NetworkRequestHoldingTime" SG_ 1216 BckGls_RrGlsHtdMKBDBpReq 5000;
BA_ "Version" SG_ 1216 BckGls_RrGlsHtdMKBDBpReq "22.05.02";
BA_ "Description" SG_ 1216 Wndshld_FrtGlsHtdMKBDBpReq "Front Glass Heated Switch Beep Request";
BA_ "GenSigSendType" SG_ 1216 Wndshld_FrtGlsHtdMKBDBpReq 4;
BA_ "UserSigValidity" SG_ 1216 Wndshld_FrtGlsHtdMKBDBpReq 0;
BA_ "NetworkRequest" SG_ 1216 Wndshld_FrtGlsHtdMKBDBpReq 0;
BA_ "NetworkRequestHoldingTime" SG_ 1216 Wndshld_FrtGlsHtdMKBDBpReq 5000;
BA_ "Version" SG_ 1216 Wndshld_FrtGlsHtdMKBDBpReq "22.05.02";
BA_ "Description" SG_ 1216 BAlarm_AutoLockrReq "-Lock request by Auto Locking

 (BurglarAlarmFunction)";
BA_ "GenSigSendType" SG_ 1216 BAlarm_AutoLockrReq 4;
BA_ "UserSigValidity" SG_ 1216 BAlarm_AutoLockrReq 0;
BA_ "NetworkRequest" SG_ 1216 BAlarm_AutoLockrReq 0;
BA_ "NetworkRequestHoldingTime" SG_ 1216 BAlarm_AutoLockrReq 5000;
BA_ "Version" SG_ 1216 BAlarm_AutoLockrReq "17.12.00";
BA_ "Description" SG_ 1216 TiltTele_SmrtIMSDBNum "Smart IMS DB Number Information";
BA_ "GenSigSendType" SG_ 1216 TiltTele_SmrtIMSDBNum 4;
BA_ "UserSigValidity" SG_ 1216 TiltTele_SmrtIMSDBNum 0;
BA_REL_ "GenSigTimeoutTime" BU_SG_REL_ SCM SG_ 1216 TiltTele_SmrtIMSDBNum 0;
BA_ "NetworkRequest" SG_ 1216 TiltTele_SmrtIMSDBNum 0;
BA_ "NetworkRequestHoldingTime" SG_ 1216 TiltTele_SmrtIMSDBNum 5000;
BA_ "Version" SG_ 1216 TiltTele_SmrtIMSDBNum "21.07.05";
BA_ "Description" SG_ 1216 Tilt_IMSMemoryCmd "Command for IMS Memory";
BA_ "GenSigSendType" SG_ 1216 Tilt_IMSMemoryCmd 4;
BA_ "UserSigValidity" SG_ 1216 Tilt_IMSMemoryCmd 0;
BA_REL_ "GenSigTimeoutTime" BU_SG_REL_ SCM SG_ 1216 Tilt_IMSMemoryCmd 0;
BA_ "NetworkRequest" SG_ 1216 Tilt_IMSMemoryCmd 0;
BA_ "NetworkRequestHoldingTime" SG_ 1216 Tilt_IMSMemoryCmd 5000;
BA_ "Version" SG_ 1216 Tilt_IMSMemoryCmd "20.08.07";
BA_ "Description" SG_ 1216 Tele_IMSMemoryCmd "Command for IMS Memory";
BA_ "GenSigSendType" SG_ 1216 Tele_IMSMemoryCmd 4;
BA_ "UserSigValidity" SG_ 1216 Tele_IMSMemoryCmd 0;
BA_REL_ "GenSigTimeoutTime" BU_SG_REL_ SCM SG_ 1216 Tele_IMSMemoryCmd 0;
BA_ "NetworkRequest" SG_ 1216 Tele_IMSMemoryCmd 0;
BA_ "NetworkRequestHoldingTime" SG_ 1216 Tele_IMSMemoryCmd 5000;
BA_ "Version" SG_ 1216 Tele_IMSMemoryCmd "20.08.07";
BA_ "GenMsgCycleTime" BO_ 171 0;
BA_ "Description" SG_ 171 BLTN_CAM_UI_Mode_Tmt_Req "Built-in Cam UI Mode terminate request.";
BA_ "GenSigSendType" SG_ 171 BLTN_CAM_UI_Mode_Tmt_Req 4;
BA_ "UserSigValidity" SG_ 171 BLTN_CAM_UI_Mode_Tmt_Req 1;
BA_REL_ "GenSigTimeoutTime" BU_SG_REL_ CGW_CCU SG_ 171 BLTN_CAM_UI_Mode_Tmt_Req 0;
BA_ "Version" SG_ 171 BLTN_CAM_UI_Mode_Tmt_Req "21.05.02";
BA_ "Description" SG_ 171 BLTN_CAM_Dis_Touch_BeepSound "Display Touch Beep Sound of valid space touch.";
BA_ "GenSigSendType" SG_ 171 BLTN_CAM_Dis_Touch_BeepSound 4;
BA_ "UserSigValidity" SG_ 171 BLTN_CAM_Dis_Touch_BeepSound 1;
BA_REL_ "GenSigTimeoutTime" BU_SG_REL_ CGW_CCU SG_ 171 BLTN_CAM_Dis_Touch_BeepSound 0;
BA_ "Version" SG_ 171 BLTN_CAM_Dis_Touch_BeepSound "21.09.05";
BA_ "Description" SG_ 171 BLTN_CAM_PopUp_Req "Built-in Cam Operating and SD Card related Popup Request on HU Display.";
BA_ "GenSigSendType" SG_ 171 BLTN_CAM_PopUp_Req 4;
BA_ "UserSigValidity" SG_ 171 BLTN_CAM_PopUp_Req 0;
BA_REL_ "GenSigTimeoutTime" BU_SG_REL_ CGW_CCU SG_ 171 BLTN_CAM_PopUp_Req 0;
BA_ "Version" SG_ 171 BLTN_CAM_PopUp_Req "23.02.02";
BA_ "Description" SG_ 171 BLTN_CAM_File_List_Renew "The Storage information is renewed inform to HU.";
BA_ "GenSigSendType" SG_ 171 BLTN_CAM_File_List_Renew 4;
BA_ "UserSigValidity" SG_ 171 BLTN_CAM_File_List_Renew 1;
BA_REL_ "GenSigTimeoutTime" BU_SG_REL_ CGW_CCU SG_ 171 BLTN_CAM_File_List_Renew 0;
BA_ "Version" SG_ 171 BLTN_CAM_File_List_Renew "21.05.02";
BA_ "Description" SG_ 171 BLTN_CAM_Wifi_Pwd_Chg_State "The Response, when HU change Wifi Passowrd via SOME/IP";
BA_ "GenSigSendType" SG_ 171 BLTN_CAM_Wifi_Pwd_Chg_State 4;
BA_ "UserSigValidity" SG_ 171 BLTN_CAM_Wifi_Pwd_Chg_State 1;
BA_REL_ "GenSigTimeoutTime" BU_SG_REL_ CGW_CCU SG_ 171 BLTN_CAM_Wifi_Pwd_Chg_State 0;
BA_ "Version" SG_ 171 BLTN_CAM_Wifi_Pwd_Chg_State "21.05.04";
BA_ "GenMsgCycleTime" BO_ 2323816449 0;
BA_ "VFrameFormat" BO_ 2323816449 1;
BA_ "GenSigSendType" SG_ 2323816449 C_CtrlDrLockRlyCCS_Copy_2 4;
BA_ "UserSigValidity" SG_ 2323816449 C_CtrlDrLockRlyCCS_Copy_2 0;
BA_ "NetworkRequest" SG_ 2323816449 C_CtrlDrLockRlyCCS_Copy_2 0;
BA_ "NetworkRequestHoldingTime" SG_ 2323816449 C_CtrlDrLockRlyCCS_Copy_2 2000;
BA_ "Version" SG_ 2323816449 C_CtrlDrLockRlyCCS_Copy_2 "20.08.07";
BA_ "GenSigSendType" SG_ 2323816449 C_TeleHeatingCmdIBOX_Copy_2 4;
BA_ "GenSigStartValue" SG_ 2323816449 C_TeleHeatingCmdIBOX_Copy_2 3;
BA_ "UserSigValidity" SG_ 2323816449 C_TeleHeatingCmdIBOX_Copy_2 0;
BA_ "NetworkRequest" SG_ 2323816449 C_TeleHeatingCmdIBOX_Copy_2 0;
BA_ "NetworkRequestHoldingTime" SG_ 2323816449 C_TeleHeatingCmdIBOX_Copy_2 2000;
BA_ "Version" SG_ 2323816449 C_TeleHeatingCmdIBOX_Copy_2 "20.08.07";
BA_ "GenSigSendType" SG_ 2323816449 C_TeleStrgWhlHeatingCmdIBOX_Copy_2 4;
BA_ "GenSigStartValue" SG_ 2323816449 C_TeleStrgWhlHeatingCmdIBOX_Copy_2 3;
BA_ "UserSigValidity" SG_ 2323816449 C_TeleStrgWhlHeatingCmdIBOX_Copy_2 0;
BA_ "NetworkRequest" SG_ 2323816449 C_TeleStrgWhlHeatingCmdIBOX_Copy_2 0;
BA_ "NetworkRequestHoldingTime" SG_ 2323816449 C_TeleStrgWhlHeatingCmdIBOX_Copy_2 2000;
BA_ "Version" SG_ 2323816449 C_TeleStrgWhlHeatingCmdIBOX_Copy_2 "20.08.07";
BA_ "GenSigSendType" SG_ 2323816449 C_TeleDefoggerHeatingCmdIBOX_Copy_2 4;
BA_ "GenSigStartValue" SG_ 2323816449 C_TeleDefoggerHeatingCmdIBOX_Copy_2 3;
BA_ "UserSigValidity" SG_ 2323816449 C_TeleDefoggerHeatingCmdIBOX_Copy_2 0;
BA_ "NetworkRequest" SG_ 2323816449 C_TeleDefoggerHeatingCmdIBOX_Copy_2 0;
BA_ "NetworkRequestHoldingTime" SG_ 2323816449 C_TeleDefoggerHeatingCmdIBOX_Copy_2 2000;
BA_ "Version" SG_ 2323816449 C_TeleDefoggerHeatingCmdIBOX_Copy_2 "20.08.07";
BA_ "GenSigSendType" SG_ 2323816449 C_TeleDrvSeatOpCmdIBOX_Copy_2 4;
BA_ "UserSigValidity" SG_ 2323816449 C_TeleDrvSeatOpCmdIBOX_Copy_2 3;
BA_REL_ "GenSigTimeoutTime" BU_SG_REL_ GW_APSU SG_ 2323816449 C_TeleDrvSeatOpCmdIBOX_Copy_2 0;
BA_REL_ "GenSigTimeoutTime" BU_SG_REL_ GW_DPSU SG_ 2323816449 C_TeleDrvSeatOpCmdIBOX_Copy_2 0;
BA_REL_ "GenSigTimeoutTime" BU_SG_REL_ SHVU_FR SG_ 2323816449 C_TeleDrvSeatOpCmdIBOX_Copy_2 0;
BA_ "Version" SG_ 2323816449 C_TeleDrvSeatOpCmdIBOX_Copy_2 "20.08.07";
BA_ "GenSigSendType" SG_ 2323816449 C_CtrlDrUnlockRlyCCS_Copy_2 4;
BA_ "UserSigValidity" SG_ 2323816449 C_CtrlDrUnlockRlyCCS_Copy_2 0;
BA_ "NetworkRequest" SG_ 2323816449 C_CtrlDrUnlockRlyCCS_Copy_2 0;
BA_ "NetworkRequestHoldingTime" SG_ 2323816449 C_CtrlDrUnlockRlyCCS_Copy_2 2000;
BA_ "Version" SG_ 2323816449 C_CtrlDrUnlockRlyCCS_Copy_2 "20.08.07";
BA_ "GenSigSendType" SG_ 2323816449 C_TeleAstSeatOpCmdIBOX_Copy_2 4;
BA_ "UserSigValidity" SG_ 2323816449 C_TeleAstSeatOpCmdIBOX_Copy_2 3;
BA_REL_ "GenSigTimeoutTime" BU_SG_REL_ GW_APSU SG_ 2323816449 C_TeleAstSeatOpCmdIBOX_Copy_2 0;
BA_REL_ "GenSigTimeoutTime" BU_SG_REL_ SHVU_FR SG_ 2323816449 C_TeleAstSeatOpCmdIBOX_Copy_2 0;
BA_ "Version" SG_ 2323816449 C_TeleAstSeatOpCmdIBOX_Copy_2 "20.08.07";
BA_ "GenSigSendType" SG_ 2323816449 C_TeleRRSeatOpCmdIBOX_Copy_2 4;
BA_ "UserSigValidity" SG_ 2323816449 C_TeleRRSeatOpCmdIBOX_Copy_2 3;
BA_REL_ "GenSigTimeoutTime" BU_SG_REL_ ATS SG_ 2323816449 C_TeleRRSeatOpCmdIBOX_Copy_2 0;
BA_REL_ "GenSigTimeoutTime" BU_SG_REL_ GW_RRPSU SG_ 2323816449 C_TeleRRSeatOpCmdIBOX_Copy_2 0;
BA_REL_ "GenSigTimeoutTime" BU_SG_REL_ RRHV SG_ 2323816449 C_TeleRRSeatOpCmdIBOX_Copy_2 0;
BA_REL_ "GenSigTimeoutTime" BU_SG_REL_ SHVU_FR SG_ 2323816449 C_TeleRRSeatOpCmdIBOX_Copy_2 0;
BA_REL_ "GenSigTimeoutTime" BU_SG_REL_ SHVU_RR SG_ 2323816449 C_TeleRRSeatOpCmdIBOX_Copy_2 0;
BA_ "Version" SG_ 2323816449 C_TeleRRSeatOpCmdIBOX_Copy_2 "20.08.07";
BA_ "GenSigSendType" SG_ 2323816449 C_TeleRLSeatOpCmdIBOX_Copy_1 4;
BA_ "UserSigValidity" SG_ 2323816449 C_TeleRLSeatOpCmdIBOX_Copy_1 3;
BA_REL_ "GenSigTimeoutTime" BU_SG_REL_ ATS SG_ 2323816449 C_TeleRLSeatOpCmdIBOX_Copy_1 0;
BA_REL_ "GenSigTimeoutTime" BU_SG_REL_ GW_RLPSU SG_ 2323816449 C_TeleRLSeatOpCmdIBOX_Copy_1 0;
BA_REL_ "GenSigTimeoutTime" BU_SG_REL_ RLHV SG_ 2323816449 C_TeleRLSeatOpCmdIBOX_Copy_1 0;
BA_REL_ "GenSigTimeoutTime" BU_SG_REL_ SHVU_FR SG_ 2323816449 C_TeleRLSeatOpCmdIBOX_Copy_1 0;
BA_REL_ "GenSigTimeoutTime" BU_SG_REL_ SHVU_RR SG_ 2323816449 C_TeleRLSeatOpCmdIBOX_Copy_1 0;
BA_ "Version" SG_ 2323816449 C_TeleRLSeatOpCmdIBOX_Copy_1 "20.08.07";
BA_ "GenSigSendType" SG_ 2323816449 C_DrvWindowCmdAVN_Copy_2 4;
BA_ "GenSigStartValue" SG_ 2323816449 C_DrvWindowCmdAVN_Copy_2 15;
BA_ "UserSigValidity" SG_ 2323816449 C_DrvWindowCmdAVN_Copy_2 0;
BA_ "Version" SG_ 2323816449 C_DrvWindowCmdAVN_Copy_2 "20.08.07";
BA_ "GenSigSendType" SG_ 2323816449 C_HazardFromCCS_Copy_2 4;
BA_ "UserSigValidity" SG_ 2323816449 C_HazardFromCCS_Copy_2 0;
BA_ "NetworkRequest" SG_ 2323816449 C_HazardFromCCS_Copy_2 0;
BA_ "NetworkRequestHoldingTime" SG_ 2323816449 C_HazardFromCCS_Copy_2 2000;
BA_ "Version" SG_ 2323816449 C_HazardFromCCS_Copy_2 "20.08.07";
BA_ "GenSigSendType" SG_ 2323816449 C_AstWindowCmdAVN_Copy_2 4;
BA_ "GenSigStartValue" SG_ 2323816449 C_AstWindowCmdAVN_Copy_2 15;
BA_ "UserSigValidity" SG_ 2323816449 C_AstWindowCmdAVN_Copy_2 0;
BA_ "Version" SG_ 2323816449 C_AstWindowCmdAVN_Copy_2 "20.08.07";
BA_ "GenSigSendType" SG_ 2323816449 C_RRWindowCmdAVN_Copy_2 4;
BA_ "GenSigStartValue" SG_ 2323816449 C_RRWindowCmdAVN_Copy_2 15;
BA_ "UserSigValidity" SG_ 2323816449 C_RRWindowCmdAVN_Copy_2 0;
BA_ "Version" SG_ 2323816449 C_RRWindowCmdAVN_Copy_2 "20.08.07";
BA_ "GenSigSendType" SG_ 2323816449 C_RLWindowCmdAVN_Copy_2 4;
BA_ "GenSigStartValue" SG_ 2323816449 C_RLWindowCmdAVN_Copy_2 15;
BA_ "UserSigValidity" SG_ 2323816449 C_RLWindowCmdAVN_Copy_2 0;
BA_ "Version" SG_ 2323816449 C_RLWindowCmdAVN_Copy_2 "20.08.07";
BA_ "Description" SG_ 2323816449 TailCtrlReq_Copy "This signal is for cotroling Tail lamp.";
BA_ "GenSigSendType" SG_ 2323816449 TailCtrlReq_Copy 4;
BA_ "UserSigValidity" SG_ 2323816449 TailCtrlReq_Copy 0;
BA_ "Version" SG_ 2323816449 TailCtrlReq_Copy "20.08.07";
BA_ "Description" SG_ 2323816449 HazardCtrlReq_Copy "This signal is request for controling Hazard lamp.";
BA_ "GenSigSendType" SG_ 2323816449 HazardCtrlReq_Copy 4;
BA_ "UserSigValidity" SG_ 2323816449 HazardCtrlReq_Copy 0;
BA_ "Version" SG_ 2323816449 HazardCtrlReq_Copy "20.08.07";
BA_ "GenSigSendType" SG_ 2323816449 HU_DATC_AirCleaningSet_Copy_1 4;
BA_ "GenSigStartValue" SG_ 2323816449 HU_DATC_AirCleaningSet_Copy_1 3;
BA_ "UserSigValidity" SG_ 2323816449 HU_DATC_AirCleaningSet_Copy_1 3;
BA_ "Version" SG_ 2323816449 HU_DATC_AirCleaningSet_Copy_1 "20.08.07";
BA_ "GenSigSendType" SG_ 2323816449 C_PanicFromCCS_Copy_2 4;
BA_ "UserSigValidity" SG_ 2323816449 C_PanicFromCCS_Copy_2 0;
BA_ "NetworkRequest" SG_ 2323816449 C_PanicFromCCS_Copy_2 0;
BA_ "NetworkRequestHoldingTime" SG_ 2323816449 C_PanicFromCCS_Copy_2 2000;
BA_ "Version" SG_ 2323816449 C_PanicFromCCS_Copy_2 "20.08.07";
BA_ "Description" SG_ 2323816449 C_TeleFrontHeatingCmdIBOX_Copy_1 "Command for Remote Heating (Front Window)";
BA_ "GenSigSendType" SG_ 2323816449 C_TeleFrontHeatingCmdIBOX_Copy_1 4;
BA_ "GenSigStartValue" SG_ 2323816449 C_TeleFrontHeatingCmdIBOX_Copy_1 3;
BA_ "UserSigValidity" SG_ 2323816449 C_TeleFrontHeatingCmdIBOX_Copy_1 0;
BA_ "NetworkRequest" SG_ 2323816449 C_TeleFrontHeatingCmdIBOX_Copy_1 0;
BA_ "NetworkRequestHoldingTime" SG_ 2323816449 C_TeleFrontHeatingCmdIBOX_Copy_1 2000;
BA_ "Version" SG_ 2323816449 C_TeleFrontHeatingCmdIBOX_Copy_1 "20.08.07";
BA_ "Description" SG_ 2323816449 RAC_AirCleaningCtrlReq_Copy_1 "CCS Module(Telematics unit) transmits this signal to control the air cleaning when the remote air-condition is request.";
BA_ "GenSigSendType" SG_ 2323816449 RAC_AirCleaningCtrlReq_Copy_1 4;
BA_ "UserSigValidity" SG_ 2323816449 RAC_AirCleaningCtrlReq_Copy_1 3;
BA_ "Version" SG_ 2323816449 RAC_AirCleaningCtrlReq_Copy_1 "20.09.00";
BA_ "GenSigSendType" SG_ 2323816449 C_PreCrankReq_Copy 4;
BA_ "UserSigValidity" SG_ 2323816449 C_PreCrankReq_Copy 0;
BA_ "NetworkRequest" SG_ 2323816449 C_PreCrankReq_Copy 0;
BA_ "Version" SG_ 2323816449 C_PreCrankReq_Copy "20.08.07";
BA_ "GenMsgCycleTime" BO_ 2323816450 0;
BA_ "VFrameFormat" BO_ 2323816450 1;
BA_ "Description" SG_ 2323816450 HU_CDMOpenCmd_Copy_1 "Command for CDM open/close";
BA_ "GenSigSendType" SG_ 2323816450 HU_CDMOpenCmd_Copy_1 4;
BA_ "UserSigValidity" SG_ 2323816450 HU_CDMOpenCmd_Copy_1 7;
BA_ "Version" SG_ 2323816450 HU_CDMOpenCmd_Copy_1 "20.09.00";
BA_ "Description" SG_ 2323816450 CargoTrgTempSet "This signal is to set the target temperature of cargo";
BA_ "GenSigSendType" SG_ 2323816450 CargoTrgTempSet 4;
BA_ "UserSigValidity" SG_ 2323816450 CargoTrgTempSet 0;
BA_ "NetworkRequest" SG_ 2323816450 CargoTrgTempSet 0;
BA_ "NetworkRequestHoldingTime" SG_ 2323816450 CargoTrgTempSet 2000;
BA_ "Version" SG_ 2323816450 CargoTrgTempSet "22.10.19";
BA_ "Description" SG_ 2323816450 CompControlReq "This signal to control the compressor of Cargo";
BA_ "GenSigSendType" SG_ 2323816450 CompControlReq 4;
BA_ "UserSigValidity" SG_ 2323816450 CompControlReq 0;
BA_ "NetworkRequest" SG_ 2323816450 CompControlReq 0;
BA_ "NetworkRequestHoldingTime" SG_ 2323816450 CompControlReq 2000;
BA_ "Version" SG_ 2323816450 CompControlReq "22.10.19";
BA_ "Description" SG_ 2323816450 HU_StrgWhlHeatingSet_CCS_Copy "steering wheel heating control by step1/2";
BA_ "GenSigSendType" SG_ 2323816450 HU_StrgWhlHeatingSet_CCS_Copy 4;
BA_ "GenSigStartValue" SG_ 2323816450 HU_StrgWhlHeatingSet_CCS_Copy 7;
BA_ "UserSigValidity" SG_ 2323816450 HU_StrgWhlHeatingSet_CCS_Copy 0;
BA_ "Version" SG_ 2323816450 HU_StrgWhlHeatingSet_CCS_Copy "21.05.02";
BA_ "Description" SG_ 2323816450 CargoControlMasterSet "This signal is to set the control master of Carge teperature control.";
BA_ "GenSigSendType" SG_ 2323816450 CargoControlMasterSet 4;
BA_ "UserSigValidity" SG_ 2323816450 CargoControlMasterSet 0;
BA_ "NetworkRequest" SG_ 2323816450 CargoControlMasterSet 0;
BA_ "NetworkRequestHoldingTime" SG_ 2323816450 CargoControlMasterSet 2000;
BA_ "Version" SG_ 2323816450 CargoControlMasterSet "22.10.19";
BA_ "Description" SG_ 2323816450 C_TeleTRSeatOpCmdIBOX_CCU "Command for Remote Seat Heat/Vent control (3RD Right)";
BA_ "GenSigSendType" SG_ 2323816450 C_TeleTRSeatOpCmdIBOX_CCU 4;
BA_ "UserSigValidity" SG_ 2323816450 C_TeleTRSeatOpCmdIBOX_CCU 7;
BA_ "Version" SG_ 2323816450 C_TeleTRSeatOpCmdIBOX_CCU "23.02.05";
BA_ "Description" SG_ 2323816450 C_TeleTLSeatOpCmdIBOX_CCU "Command for Remote Seat Heat/Vent control (3RD Left)";
BA_ "GenSigSendType" SG_ 2323816450 C_TeleTLSeatOpCmdIBOX_CCU 4;
BA_ "UserSigValidity" SG_ 2323816450 C_TeleTLSeatOpCmdIBOX_CCU 7;
BA_ "Version" SG_ 2323816450 C_TeleTLSeatOpCmdIBOX_CCU "23.02.05";
BA_ "Description" SG_ 2323816450 SetCargoWrngValue "This signal is to set the Threshold value for the Cargo warning.";
BA_ "GenSigSendType" SG_ 2323816450 SetCargoWrngValue 4;
BA_ "GenSigStartValue" SG_ 2323816450 SetCargoWrngValue 31;
BA_ "UserSigValidity" SG_ 2323816450 SetCargoWrngValue 0;
BA_ "NetworkRequest" SG_ 2323816450 SetCargoWrngValue 0;
BA_ "NetworkRequestHoldingTime" SG_ 2323816450 SetCargoWrngValue 2000;
BA_ "Version" SG_ 2323816450 SetCargoWrngValue "23.09.00";
BA_ "Description" SG_ 2323816450 FrunkCtrlReq "This signal is request for controling Frunk.";
BA_ "GenSigSendType" SG_ 2323816450 FrunkCtrlReq 4;
BA_ "UserSigValidity" SG_ 2323816450 FrunkCtrlReq 0;
BA_ "NetworkRequest" SG_ 2323816450 FrunkCtrlReq 0;
BA_ "NetworkRequestHoldingTime" SG_ 2323816450 FrunkCtrlReq 2000;
BA_ "Version" SG_ 2323816450 FrunkCtrlReq "22.03.02";
BA_ "Description" SG_ 2323816450 C_EsyAcsProfileID_CCU "This signal indicates the current detected profile ID by smartphone APP.(The drv seat move to the easy access position of the detected profile ID when receive the signal)";
BA_ "GenSigSendType" SG_ 2323816450 C_EsyAcsProfileID_CCU 4;
BA_ "UserSigValidity" SG_ 2323816450 C_EsyAcsProfileID_CCU 0;
BA_REL_ "GenSigTimeoutTime" BU_SG_REL_ GW_DPSU SG_ 2323816450 C_EsyAcsProfileID_CCU 0;
BA_ "Version" SG_ 2323816450 C_EsyAcsProfileID_CCU "23.02.05";
BA_ "GenMsgCycleTime" BO_ 2323816451 0;
BA_ "VFrameFormat" BO_ 2323816451 1;
BA_ "GenMsgCycleTime" BO_ 2323816452 0;
BA_ "VFrameFormat" BO_ 2323816452 1;
BA_ "GenMsgSendType" BO_ 2382594049 0;
BA_ "VFrameFormat" BO_ 2382594049 1;
BA_ "Description" SG_ 2382594049 DATC_Crc3Val "The data area for CRC calculation is based on the data length (DLC) of the message DB.

The CRC shall be calculated over the entire data block (excluding the CRC bytes) including the user data, alive counter and Data ID



- CRC Polynomial (0x1021) , Initial Value : 0xFFFF, XOR value : 0x0000, Data ID : Message ID + 0xF800 

- The initial value is for CRC calculation and the message should be sent with the calculated result value. 

- The mathematical expression to 16 bit CRC polynomial is given here. G(x) = x16 + x12 + x5 + 1



<For CRC calculation of CAN-FD Msg for HS CAN domain ECUs>



- HS-CAN Messages that routed from CAN-FD domain are using 29 bit Extended CAN ID and splitted into 8 Byte Messages.

(from 1 to 4 Msgs, depending on source CAN-FD Msg¡¯s DLC)

- For splitted CAN-FD Msgs¡¯ CRC calculation, HS CAN ECUs should use source CAN-FD Msg¡¯s original STD ID. 

- The original STD ID can be read from Ext ID¡¯s 4~6th Byte.

Eg. STD 0x6AA : EXT SPLT 0x1A8[6AA]01 / 0x1A8[6AA]02 / 0x1A8[6AA]03 / 0x1A8[6AA]04 

(2~4th splitited Msgs can be omitted depending on source CAN-FD Msg¡¯s DLC)

- Aslo, HS-CAN ECUs should use merged data block (from whole splitted Msg) for CRC calculation.";
BA_ "GenSigSendType" SG_ 2382594049 DATC_Crc3Val 4;
BA_ "GenSigStartValue" SG_ 2382594049 DATC_Crc3Val 65535;
BA_ "UserSigValidity" SG_ 2382594049 DATC_Crc3Val 3;
BA_ "Version" SG_ 2382594049 DATC_Crc3Val "21.09.03";
BA_ "Description" SG_ 2382594049 DATC_AlvCnt3Val "For the first transmission request for a data element the counter shall be initialized with 0 and shall be incremented by 1 for every subsequent send request. 

When the counter reaches the maximum value(0xFF), then it shall restart with 0 for the next send request";
BA_ "GenSigSendType" SG_ 2382594049 DATC_AlvCnt3Val 4;
BA_ "UserSigValidity" SG_ 2382594049 DATC_AlvCnt3Val 3;
BA_ "Version" SG_ 2382594049 DATC_AlvCnt3Val "21.09.03";
BA_ "Description" SG_ 2382594049 DATC_DrvTempCDis "This signal indicates setting temperature (¡É) of Driver Side.";
BA_ "GenSigSendType" SG_ 2382594049 DATC_DrvTempCDis 4;
BA_ "UserSigValidity" SG_ 2382594049 DATC_DrvTempCDis 6;
BA_REL_ "GenSigTimeoutTime" BU_SG_REL_ ATS SG_ 2382594049 DATC_DrvTempCDis 1500;
BA_ "Version" SG_ 2382594049 DATC_DrvTempCDis "18.05.01";
BA_ "Description" SG_ 2382594049 DATC_DrvTempFDis "This signal indicates setting temperature (¢µ) of Driver Side.";
BA_ "GenSigSendType" SG_ 2382594049 DATC_DrvTempFDis 4;
BA_ "UserSigValidity" SG_ 2382594049 DATC_DrvTempFDis 6;
BA_REL_ "GenSigTimeoutTime" BU_SG_REL_ ATS SG_ 2382594049 DATC_DrvTempFDis 1500;
BA_ "Version" SG_ 2382594049 DATC_DrvTempFDis "18.05.01";
BA_ "Description" SG_ 2382594049 DATC_PassTempCDis "This signal indicates setting temperature (¡É) of Passenger Side.";
BA_ "GenSigSendType" SG_ 2382594049 DATC_PassTempCDis 4;
BA_ "UserSigValidity" SG_ 2382594049 DATC_PassTempCDis 6;
BA_REL_ "GenSigTimeoutTime" BU_SG_REL_ ATS SG_ 2382594049 DATC_PassTempCDis 1500;
BA_ "Version" SG_ 2382594049 DATC_PassTempCDis "18.05.01";
BA_ "Description" SG_ 2382594049 DATC_PassTempFDis "This signal indicates setting temperature (¢µ) of Passenger Side.";
BA_ "GenSigSendType" SG_ 2382594049 DATC_PassTempFDis 4;
BA_ "UserSigValidity" SG_ 2382594049 DATC_PassTempFDis 6;
BA_REL_ "GenSigTimeoutTime" BU_SG_REL_ ATS SG_ 2382594049 DATC_PassTempFDis 1500;
BA_ "Version" SG_ 2382594049 DATC_PassTempFDis "18.05.01";
BA_ "Description" SG_ 2382594049 DATC_TempDispSta "This signal is an information display of the set temperature range of DATC.";
BA_ "GenSigSendType" SG_ 2382594049 DATC_TempDispSta 4;
BA_ "UserSigValidity" SG_ 2382594049 DATC_TempDispSta 7;
BA_ "Version" SG_ 2382594049 DATC_TempDispSta "21.07.06";
BA_ "Description" SG_ 2382594049 DATC_PreEngOnReq2 "Pre Engine On Request";
BA_ "GenSigSendType" SG_ 2382594049 DATC_PreEngOnReq2 4;
BA_ "UserSigValidity" SG_ 2382594049 DATC_PreEngOnReq2 4;
BA_ "Version" SG_ 2382594049 DATC_PreEngOnReq2 "20.04.03";
BA_ "GenMsgSendType" BO_ 2424580353 0;
BA_ "VFrameFormat" BO_ 2424580353 1;
BA_ "Description" SG_ 2424580353 DATC_Crc12Val "The data area for CRC calculation is based on the data length (DLC) of the message DB.

The CRC shall be calculated over the entire data block (excluding the CRC bytes) including the user data, alive counter and Data ID



- CRC Polynomial (0x1021) , Initial Value : 0xFFFF, XOR value : 0x0000, Data ID : Message ID + 0xF800 

- The initial value is for CRC calculation and the message should be sent with the calculated result value. 

- The mathematical expression to 16 bit CRC polynomial is given here. G(x) = x16 + x12 + x5 + 1



<For CRC calculation of CAN-FD Msg for HS CAN domain ECUs>



- HS-CAN Messages that routed from CAN-FD domain are using 29 bit Extended CAN ID and splitted into 8 Byte Messages.

(from 1 to 4 Msgs, depending on source CAN-FD Msg¡¯s DLC)

- For splitted CAN-FD Msgs¡¯ CRC calculation, HS CAN ECUs should use source CAN-FD Msg¡¯s original STD ID. 

- The original STD ID can be read from Ext ID¡¯s 4~6th Byte.

Eg. STD 0x6AA : EXT SPLT 0x1A8[6AA]01 / 0x1A8[6AA]02 / 0x1A8[6AA]03 / 0x1A8[6AA]04 

(2~4th splitited Msgs can be omitted depending on source CAN-FD Msg¡¯s DLC)

- Aslo, HS-CAN ECUs should use merged data block (from whole splitted Msg) for CRC calculation.";
BA_ "GenSigSendType" SG_ 2424580353 DATC_Crc12Val 4;
BA_ "GenSigStartValue" SG_ 2424580353 DATC_Crc12Val 65535;
BA_ "UserSigValidity" SG_ 2424580353 DATC_Crc12Val 3;
BA_ "Version" SG_ 2424580353 DATC_Crc12Val "21.09.03";
BA_ "Description" SG_ 2424580353 DATC_AlvCnt12Val "For the first transmission request for a data element the counter shall be initialized with 0 and shall be incremented by 1 for every subsequent send request. 

When the counter reaches the maximum value(0xFF), then it shall restart with 0 for the next send request";
BA_ "GenSigSendType" SG_ 2424580353 DATC_AlvCnt12Val 4;
BA_ "UserSigValidity" SG_ 2424580353 DATC_AlvCnt12Val 3;
BA_ "Version" SG_ 2424580353 DATC_AlvCnt12Val "21.09.03";
BA_ "Description" SG_ 2424580353 DATC_StrWhlHtrSwReq "Steering Wheel heater S/W";
BA_ "GenSigSendType" SG_ 2424580353 DATC_StrWhlHtrSwReq 4;
BA_ "UserSigValidity" SG_ 2424580353 DATC_StrWhlHtrSwReq 7;
BA_ "Version" SG_ 2424580353 DATC_StrWhlHtrSwReq "17.11.00";
BA_ "Description" SG_ 2424580353 DATC_FRStHtrSwReq "Front Right Seat heater S/W";
BA_ "GenSigSendType" SG_ 2424580353 DATC_FRStHtrSwReq 4;
BA_ "UserSigValidity" SG_ 2424580353 DATC_FRStHtrSwReq 7;
BA_REL_ "GenSigTimeoutTime" BU_SG_REL_ GW_APSU SG_ 2424580353 DATC_FRStHtrSwReq 1500;
BA_REL_ "GenSigTimeoutTime" BU_SG_REL_ GW_DPSU SG_ 2424580353 DATC_FRStHtrSwReq 1500;
BA_REL_ "GenSigTimeoutTime" BU_SG_REL_ SHVU_FR SG_ 2424580353 DATC_FRStHtrSwReq 1500;
BA_REL_ "GenSigTimeoutTime" BU_SG_REL_ SHVU_RR SG_ 2424580353 DATC_FRStHtrSwReq 1500;
BA_ "Version" SG_ 2424580353 DATC_FRStHtrSwReq "17.11.00";
BA_ "Description" SG_ 2424580353 DATC_FRStVentSwReq "Front Right Seat cooler S/W";
BA_ "GenSigSendType" SG_ 2424580353 DATC_FRStVentSwReq 4;
BA_ "UserSigValidity" SG_ 2424580353 DATC_FRStVentSwReq 7;
BA_REL_ "GenSigTimeoutTime" BU_SG_REL_ GW_APSU SG_ 2424580353 DATC_FRStVentSwReq 1500;
BA_REL_ "GenSigTimeoutTime" BU_SG_REL_ GW_DPSU SG_ 2424580353 DATC_FRStVentSwReq 1500;
BA_REL_ "GenSigTimeoutTime" BU_SG_REL_ SHVU_FR SG_ 2424580353 DATC_FRStVentSwReq 1500;
BA_REL_ "GenSigTimeoutTime" BU_SG_REL_ SHVU_RR SG_ 2424580353 DATC_FRStVentSwReq 1500;
BA_ "Version" SG_ 2424580353 DATC_FRStVentSwReq "17.11.00";
BA_ "Description" SG_ 2424580353 DATC_RrDefSw "Rear Defog Switch";
BA_ "GenSigSendType" SG_ 2424580353 DATC_RrDefSw 4;
BA_ "UserSigValidity" SG_ 2424580353 DATC_RrDefSw 3;
BA_ "Version" SG_ 2424580353 DATC_RrDefSw "19.04.06";
BA_ "Description" SG_ 2424580353 DATC_FLStOpReq "Left Seat warmer / Ventilation Operation request";
BA_ "GenSigSendType" SG_ 2424580353 DATC_FLStOpReq 4;
BA_ "UserSigValidity" SG_ 2424580353 DATC_FLStOpReq 7;
BA_REL_ "GenSigTimeoutTime" BU_SG_REL_ GW_APSU SG_ 2424580353 DATC_FLStOpReq 1500;
BA_REL_ "GenSigTimeoutTime" BU_SG_REL_ GW_DPSU SG_ 2424580353 DATC_FLStOpReq 1500;
BA_REL_ "GenSigTimeoutTime" BU_SG_REL_ SHVU_FR SG_ 2424580353 DATC_FLStOpReq 1500;
BA_REL_ "GenSigTimeoutTime" BU_SG_REL_ SHVU_RR SG_ 2424580353 DATC_FLStOpReq 1500;
BA_ "Version" SG_ 2424580353 DATC_FLStOpReq "17.11.00";
BA_ "Description" SG_ 2424580353 DATC_FRStOpReq "Right Seat Warmer / Ventilation Operation request";
BA_ "GenSigSendType" SG_ 2424580353 DATC_FRStOpReq 4;
BA_ "UserSigValidity" SG_ 2424580353 DATC_FRStOpReq 7;
BA_REL_ "GenSigTimeoutTime" BU_SG_REL_ GW_APSU SG_ 2424580353 DATC_FRStOpReq 1500;
BA_REL_ "GenSigTimeoutTime" BU_SG_REL_ SHVU_FR SG_ 2424580353 DATC_FRStOpReq 1500;
BA_REL_ "GenSigTimeoutTime" BU_SG_REL_ SHVU_RR SG_ 2424580353 DATC_FRStOpReq 1500;
BA_ "Version" SG_ 2424580353 DATC_FRStOpReq "17.11.00";
BA_ "Description" SG_ 2424580353 DATC_FLStHtrSwReq "Front Left Seat heater S/W";
BA_ "GenSigSendType" SG_ 2424580353 DATC_FLStHtrSwReq 4;
BA_ "UserSigValidity" SG_ 2424580353 DATC_FLStHtrSwReq 7;
BA_REL_ "GenSigTimeoutTime" BU_SG_REL_ GW_APSU SG_ 2424580353 DATC_FLStHtrSwReq 1500;
BA_REL_ "GenSigTimeoutTime" BU_SG_REL_ GW_DPSU SG_ 2424580353 DATC_FLStHtrSwReq 1500;
BA_REL_ "GenSigTimeoutTime" BU_SG_REL_ SHVU_FR SG_ 2424580353 DATC_FLStHtrSwReq 1500;
BA_REL_ "GenSigTimeoutTime" BU_SG_REL_ SHVU_RR SG_ 2424580353 DATC_FLStHtrSwReq 1500;
BA_ "Version" SG_ 2424580353 DATC_FLStHtrSwReq "17.11.00";
BA_ "Description" SG_ 2424580353 DATC_FLStVentSwReq "Front Left Seat cooler S/W";
BA_ "GenSigSendType" SG_ 2424580353 DATC_FLStVentSwReq 4;
BA_ "UserSigValidity" SG_ 2424580353 DATC_FLStVentSwReq 7;
BA_REL_ "GenSigTimeoutTime" BU_SG_REL_ GW_APSU SG_ 2424580353 DATC_FLStVentSwReq 1500;
BA_REL_ "GenSigTimeoutTime" BU_SG_REL_ GW_DPSU SG_ 2424580353 DATC_FLStVentSwReq 1500;
BA_REL_ "GenSigTimeoutTime" BU_SG_REL_ SHVU_FR SG_ 2424580353 DATC_FLStVentSwReq 1500;
BA_REL_ "GenSigTimeoutTime" BU_SG_REL_ SHVU_RR SG_ 2424580353 DATC_FLStVentSwReq 1500;
BA_ "Version" SG_ 2424580353 DATC_FLStVentSwReq "17.11.00";
BA_ "Description" SG_ 2424580353 DATC_FLStTmblrSwReq "Front Left Seat cooler S/W";
BA_ "GenSigSendType" SG_ 2424580353 DATC_FLStTmblrSwReq 4;
BA_ "UserSigValidity" SG_ 2424580353 DATC_FLStTmblrSwReq 3;
BA_REL_ "GenSigTimeoutTime" BU_SG_REL_ GW_APSU SG_ 2424580353 DATC_FLStTmblrSwReq 1500;
BA_REL_ "GenSigTimeoutTime" BU_SG_REL_ GW_DPSU SG_ 2424580353 DATC_FLStTmblrSwReq 1500;
BA_REL_ "GenSigTimeoutTime" BU_SG_REL_ SHVU_FR SG_ 2424580353 DATC_FLStTmblrSwReq 1500;
BA_ "Version" SG_ 2424580353 DATC_FLStTmblrSwReq "18.01.07";
BA_ "Description" SG_ 2424580353 DATC_FRStTmblrSwReq "Front Left Seat cooler S/W";
BA_ "GenSigSendType" SG_ 2424580353 DATC_FRStTmblrSwReq 4;
BA_ "UserSigValidity" SG_ 2424580353 DATC_FRStTmblrSwReq 3;
BA_REL_ "GenSigTimeoutTime" BU_SG_REL_ GW_APSU SG_ 2424580353 DATC_FRStTmblrSwReq 1500;
BA_REL_ "GenSigTimeoutTime" BU_SG_REL_ GW_DPSU SG_ 2424580353 DATC_FRStTmblrSwReq 1500;
BA_REL_ "GenSigTimeoutTime" BU_SG_REL_ SHVU_FR SG_ 2424580353 DATC_FRStTmblrSwReq 1500;
BA_ "Version" SG_ 2424580353 DATC_FRStTmblrSwReq "18.01.07";
BA_ "Description" SG_ 2424580353 DATC_RRStHtrSwReq "This signal indicate DATC Rear Right Seat Heater Switch Request";
BA_ "GenSigSendType" SG_ 2424580353 DATC_RRStHtrSwReq 4;
BA_ "UserSigValidity" SG_ 2424580353 DATC_RRStHtrSwReq 7;
BA_REL_ "GenSigTimeoutTime" BU_SG_REL_ GW_RRPSU SG_ 2424580353 DATC_RRStHtrSwReq 1500;
BA_REL_ "GenSigTimeoutTime" BU_SG_REL_ RRHV SG_ 2424580353 DATC_RRStHtrSwReq 1500;
BA_REL_ "GenSigTimeoutTime" BU_SG_REL_ SHVU_FR SG_ 2424580353 DATC_RRStHtrSwReq 1500;
BA_REL_ "GenSigTimeoutTime" BU_SG_REL_ SHVU_RR SG_ 2424580353 DATC_RRStHtrSwReq 1500;
BA_ "Version" SG_ 2424580353 DATC_RRStHtrSwReq "18.03.05";
BA_ "Description" SG_ 2424580353 DATC_RRStVentSwReq "This signal indicates DATC Rear Right Seat Ventilation Switch Request";
BA_ "GenSigSendType" SG_ 2424580353 DATC_RRStVentSwReq 4;
BA_ "UserSigValidity" SG_ 2424580353 DATC_RRStVentSwReq 7;
BA_REL_ "GenSigTimeoutTime" BU_SG_REL_ GW_RRPSU SG_ 2424580353 DATC_RRStVentSwReq 1500;
BA_REL_ "GenSigTimeoutTime" BU_SG_REL_ RRHV SG_ 2424580353 DATC_RRStVentSwReq 1500;
BA_REL_ "GenSigTimeoutTime" BU_SG_REL_ SHVU_FR SG_ 2424580353 DATC_RRStVentSwReq 1500;
BA_REL_ "GenSigTimeoutTime" BU_SG_REL_ SHVU_RR SG_ 2424580353 DATC_RRStVentSwReq 1500;
BA_ "Version" SG_ 2424580353 DATC_RRStVentSwReq "18.03.05";
BA_ "Description" SG_ 2424580353 DATC_RLStHtrSwReq "This signal indicates DATC Rear Left Seat Heater Switch Request";
BA_ "GenSigSendType" SG_ 2424580353 DATC_RLStHtrSwReq 4;
BA_ "UserSigValidity" SG_ 2424580353 DATC_RLStHtrSwReq 7;
BA_REL_ "GenSigTimeoutTime" BU_SG_REL_ GW_RLPSU SG_ 2424580353 DATC_RLStHtrSwReq 1500;
BA_REL_ "GenSigTimeoutTime" BU_SG_REL_ RLHV SG_ 2424580353 DATC_RLStHtrSwReq 1500;
BA_REL_ "GenSigTimeoutTime" BU_SG_REL_ SHVU_FR SG_ 2424580353 DATC_RLStHtrSwReq 1500;
BA_REL_ "GenSigTimeoutTime" BU_SG_REL_ SHVU_RR SG_ 2424580353 DATC_RLStHtrSwReq 1500;
BA_ "Version" SG_ 2424580353 DATC_RLStHtrSwReq "19.06.00";
BA_ "Description" SG_ 2424580353 DATC_RLStVentSwReq "This signal indicates DATC Rear Left Seat Ventilation Switch Request";
BA_ "GenSigSendType" SG_ 2424580353 DATC_RLStVentSwReq 4;
BA_ "UserSigValidity" SG_ 2424580353 DATC_RLStVentSwReq 7;
BA_REL_ "GenSigTimeoutTime" BU_SG_REL_ GW_RLPSU SG_ 2424580353 DATC_RLStVentSwReq 1500;
BA_REL_ "GenSigTimeoutTime" BU_SG_REL_ RLHV SG_ 2424580353 DATC_RLStVentSwReq 1500;
BA_REL_ "GenSigTimeoutTime" BU_SG_REL_ SHVU_FR SG_ 2424580353 DATC_RLStVentSwReq 1500;
BA_REL_ "GenSigTimeoutTime" BU_SG_REL_ SHVU_RR SG_ 2424580353 DATC_RLStVentSwReq 1500;
BA_ "Version" SG_ 2424580353 DATC_RLStVentSwReq "18.03.05";
BA_ "Description" SG_ 2424580353 DATC_FRWndShldHtSW "Front windshield glass heating switch

(Russia / Canada regions applied)";
BA_ "GenSigSendType" SG_ 2424580353 DATC_FRWndShldHtSW 4;
BA_ "UserSigValidity" SG_ 2424580353 DATC_FRWndShldHtSW 3;
BA_ "Version" SG_ 2424580353 DATC_FRWndShldHtSW "19.04.06";
BA_ "Description" SG_ 2424580353 DATC_WhistlelNoise "This signal is to prevent whistle noise from the door glass

(Fresh & Blower more than 4 Step condition)";
BA_ "GenSigSendType" SG_ 2424580353 DATC_WhistlelNoise 4;
BA_ "UserSigValidity" SG_ 2424580353 DATC_WhistlelNoise 3;
BA_ "Version" SG_ 2424580353 DATC_WhistlelNoise "19.04.06";
BA_ "Description" SG_ 2424580353 DATC_WdwClsReq "This signal indicates Window Close Request.

(This signal is used for Closing Control of Window when AirClean Switch is selecting)";
BA_ "GenSigSendType" SG_ 2424580353 DATC_WdwClsReq 4;
BA_ "UserSigValidity" SG_ 2424580353 DATC_WdwClsReq 7;
BA_ "Version" SG_ 2424580353 DATC_WdwClsReq "19.07.06";
BA_ "Description" SG_ 2424580353 DATC_RRSyncDis "This signal indicates SYNC Graphic On & Off.

This signal occurs when Rear SYNC switch(button) is selected either manually or automatically.";
BA_ "GenSigSendType" SG_ 2424580353 DATC_RRSyncDis 4;
BA_ "UserSigValidity" SG_ 2424580353 DATC_RRSyncDis 7;
BA_REL_ "GenSigTimeoutTime" BU_SG_REL_ ATS SG_ 2424580353 DATC_RRSyncDis 1500;
BA_ "Version" SG_ 2424580353 DATC_RRSyncDis "19.12.00";
BA_ "GenMsgCycleTime" BO_ 1219 0;
BA_ "Description" SG_ 1219 BLTN_CAM_Rec_OWD_NvalueSet "Record On/Off Set of On While Driving";
BA_ "GenSigSendType" SG_ 1219 BLTN_CAM_Rec_OWD_NvalueSet 4;
BA_ "UserSigValidity" SG_ 1219 BLTN_CAM_Rec_OWD_NvalueSet 0;
BA_REL_ "GenSigTimeoutTime" BU_SG_REL_ BLTN_CAM SG_ 1219 BLTN_CAM_Rec_OWD_NvalueSet 0;
BA_ "Version" SG_ 1219 BLTN_CAM_Rec_OWD_NvalueSet "21.05.02";
BA_ "Description" SG_ 1219 BLTN_CAM_Time_Stm_NvalueSet "Record Set of Date and Time Stamp";
BA_ "GenSigSendType" SG_ 1219 BLTN_CAM_Time_Stm_NvalueSet 4;
BA_ "UserSigValidity" SG_ 1219 BLTN_CAM_Time_Stm_NvalueSet 0;
BA_REL_ "GenSigTimeoutTime" BU_SG_REL_ BLTN_CAM SG_ 1219 BLTN_CAM_Time_Stm_NvalueSet 0;
BA_ "Version" SG_ 1219 BLTN_CAM_Time_Stm_NvalueSet "21.05.02";
BA_ "Description" SG_ 1219 BLTN_CAM_Spd_Stm_NvalueSet "Record Set of Speed Stamp";
BA_ "GenSigSendType" SG_ 1219 BLTN_CAM_Spd_Stm_NvalueSet 4;
BA_ "UserSigValidity" SG_ 1219 BLTN_CAM_Spd_Stm_NvalueSet 0;
BA_REL_ "GenSigTimeoutTime" BU_SG_REL_ BLTN_CAM SG_ 1219 BLTN_CAM_Spd_Stm_NvalueSet 0;
BA_ "Version" SG_ 1219 BLTN_CAM_Spd_Stm_NvalueSet "21.11.07";
BA_ "Description" SG_ 1219 BLTN_CAM_Locatn_Stm_NvalueSet "Record Set of Location Stamp";
BA_ "GenSigSendType" SG_ 1219 BLTN_CAM_Locatn_Stm_NvalueSet 4;
BA_ "UserSigValidity" SG_ 1219 BLTN_CAM_Locatn_Stm_NvalueSet 0;
BA_REL_ "GenSigTimeoutTime" BU_SG_REL_ BLTN_CAM SG_ 1219 BLTN_CAM_Locatn_Stm_NvalueSet 0;
BA_ "Version" SG_ 1219 BLTN_CAM_Locatn_Stm_NvalueSet "21.05.02";
BA_ "Description" SG_ 1219 BLTN_CAM_TrnSig_Stm_NvalueSet "Record Set of Turn Signal Stamp";
BA_ "GenSigSendType" SG_ 1219 BLTN_CAM_TrnSig_Stm_NvalueSet 4;
BA_ "UserSigValidity" SG_ 1219 BLTN_CAM_TrnSig_Stm_NvalueSet 0;
BA_REL_ "GenSigTimeoutTime" BU_SG_REL_ BLTN_CAM SG_ 1219 BLTN_CAM_TrnSig_Stm_NvalueSet 0;
BA_ "Version" SG_ 1219 BLTN_CAM_TrnSig_Stm_NvalueSet "21.05.02";
BA_ "Description" SG_ 1219 BLTN_CAM_AclBrk_Stm_NvalueSet "Record Set of Accelerator Brake Stamp";
BA_ "GenSigSendType" SG_ 1219 BLTN_CAM_AclBrk_Stm_NvalueSet 4;
BA_ "UserSigValidity" SG_ 1219 BLTN_CAM_AclBrk_Stm_NvalueSet 0;
BA_REL_ "GenSigTimeoutTime" BU_SG_REL_ BLTN_CAM SG_ 1219 BLTN_CAM_AclBrk_Stm_NvalueSet 0;
BA_ "Version" SG_ 1219 BLTN_CAM_AclBrk_Stm_NvalueSet "21.11.07";
BA_ "Description" SG_ 1219 BLTN_CAM_Rec_DEV_NvalueSet "Record On/Off Set of Driving Event";
BA_ "GenSigSendType" SG_ 1219 BLTN_CAM_Rec_DEV_NvalueSet 4;
BA_ "UserSigValidity" SG_ 1219 BLTN_CAM_Rec_DEV_NvalueSet 0;
BA_REL_ "GenSigTimeoutTime" BU_SG_REL_ BLTN_CAM SG_ 1219 BLTN_CAM_Rec_DEV_NvalueSet 0;
BA_ "Version" SG_ 1219 BLTN_CAM_Rec_DEV_NvalueSet "21.05.02";
BA_ "Description" SG_ 1219 BLTN_CAM_GearPos_Stm_NvalueSet "Record Set of Gear Position Stamp";
BA_ "GenSigSendType" SG_ 1219 BLTN_CAM_GearPos_Stm_NvalueSet 4;
BA_ "UserSigValidity" SG_ 1219 BLTN_CAM_GearPos_Stm_NvalueSet 0;
BA_REL_ "GenSigTimeoutTime" BU_SG_REL_ BLTN_CAM SG_ 1219 BLTN_CAM_GearPos_Stm_NvalueSet 0;
BA_ "Version" SG_ 1219 BLTN_CAM_GearPos_Stm_NvalueSet "21.11.07";
BA_ "Description" SG_ 1219 BLTN_CAM_EVSen_Stm_NvalueSet "Record Set of Event Sensitivity Stamp";
BA_ "GenSigSendType" SG_ 1219 BLTN_CAM_EVSen_Stm_NvalueSet 4;
BA_ "UserSigValidity" SG_ 1219 BLTN_CAM_EVSen_Stm_NvalueSet 0;
BA_REL_ "GenSigTimeoutTime" BU_SG_REL_ BLTN_CAM SG_ 1219 BLTN_CAM_EVSen_Stm_NvalueSet 0;
BA_ "Version" SG_ 1219 BLTN_CAM_EVSen_Stm_NvalueSet "21.05.02";
BA_ "Description" SG_ 1219 BLTN_CAM_Strangl_Stm_NvalueSet "Record Set of Steering Angle Stamp";
BA_ "GenSigSendType" SG_ 1219 BLTN_CAM_Strangl_Stm_NvalueSet 4;
BA_ "UserSigValidity" SG_ 1219 BLTN_CAM_Strangl_Stm_NvalueSet 0;
BA_REL_ "GenSigTimeoutTime" BU_SG_REL_ BLTN_CAM SG_ 1219 BLTN_CAM_Strangl_Stm_NvalueSet 0;
BA_ "Version" SG_ 1219 BLTN_CAM_Strangl_Stm_NvalueSet "21.07.05";
BA_ "Description" SG_ 1219 BLTN_CAM_EV_RecMaxTime_NvalueSet "BLTN_CAM EV Parking Rec Max Time NvalueSet";
BA_ "GenSigSendType" SG_ 1219 BLTN_CAM_EV_RecMaxTime_NvalueSet 4;
BA_ "UserSigValidity" SG_ 1219 BLTN_CAM_EV_RecMaxTime_NvalueSet 0;
BA_REL_ "GenSigTimeoutTime" BU_SG_REL_ BLTN_CAM SG_ 1219 BLTN_CAM_EV_RecMaxTime_NvalueSet 0;
BA_ "Version" SG_ 1219 BLTN_CAM_EV_RecMaxTime_NvalueSet "23.02.02";
BA_ "Description" SG_ 1219 BLTN_CAM_PrkTime_NvalueSet "Parking Operation Setting Time, Resolution : hr";
BA_ "GenSigSendType" SG_ 1219 BLTN_CAM_PrkTime_NvalueSet 4;
BA_ "UserSigValidity" SG_ 1219 BLTN_CAM_PrkTime_NvalueSet 0;
BA_REL_ "GenSigTimeoutTime" BU_SG_REL_ BLTN_CAM SG_ 1219 BLTN_CAM_PrkTime_NvalueSet 0;
BA_ "Version" SG_ 1219 BLTN_CAM_PrkTime_NvalueSet "21.11.07";
BA_ "Description" SG_ 1219 BLTN_CAM_EV_BfrTime_NvalueSet "Driving Event Time Setting - Before, Resolution : sec";
BA_ "GenSigSendType" SG_ 1219 BLTN_CAM_EV_BfrTime_NvalueSet 4;
BA_ "GenSigStartValue" SG_ 1219 BLTN_CAM_EV_BfrTime_NvalueSet 31;
BA_ "UserSigValidity" SG_ 1219 BLTN_CAM_EV_BfrTime_NvalueSet 0;
BA_REL_ "GenSigTimeoutTime" BU_SG_REL_ BLTN_CAM SG_ 1219 BLTN_CAM_EV_BfrTime_NvalueSet 0;
BA_ "Version" SG_ 1219 BLTN_CAM_EV_BfrTime_NvalueSet "23.04.02";
BA_ "Description" SG_ 1219 BLTN_CAM_Rec_OWP_NvalueSet "Record On/Off Set of On While Parked, 0x0(Default) : Parking recording function not supported";
BA_ "GenSigSendType" SG_ 1219 BLTN_CAM_Rec_OWP_NvalueSet 4;
BA_ "UserSigValidity" SG_ 1219 BLTN_CAM_Rec_OWP_NvalueSet 0;
BA_REL_ "GenSigTimeoutTime" BU_SG_REL_ BLTN_CAM SG_ 1219 BLTN_CAM_Rec_OWP_NvalueSet 0;
BA_ "Version" SG_ 1219 BLTN_CAM_Rec_OWP_NvalueSet "21.05.02";
BA_ "Description" SG_ 1219 BLTN_CAM_EV_AftTime_NvalueSet "Driving Event Time Setting - After, Resolution : sec";
BA_ "GenSigSendType" SG_ 1219 BLTN_CAM_EV_AftTime_NvalueSet 4;
BA_ "GenSigStartValue" SG_ 1219 BLTN_CAM_EV_AftTime_NvalueSet 31;
BA_ "UserSigValidity" SG_ 1219 BLTN_CAM_EV_AftTime_NvalueSet 0;
BA_REL_ "GenSigTimeoutTime" BU_SG_REL_ BLTN_CAM SG_ 1219 BLTN_CAM_EV_AftTime_NvalueSet 0;
BA_ "Version" SG_ 1219 BLTN_CAM_EV_AftTime_NvalueSet "23.04.02";
BA_ "Description" SG_ 1219 BLTN_CAM_TML_Int_NvalueSet "Record Set of Time-lapse Interval, Resolution : sec";
BA_ "GenSigSendType" SG_ 1219 BLTN_CAM_TML_Int_NvalueSet 4;
BA_ "UserSigValidity" SG_ 1219 BLTN_CAM_TML_Int_NvalueSet 0;
BA_REL_ "GenSigTimeoutTime" BU_SG_REL_ BLTN_CAM SG_ 1219 BLTN_CAM_TML_Int_NvalueSet 0;
BA_ "Version" SG_ 1219 BLTN_CAM_TML_Int_NvalueSet "21.05.02";
BA_ "Description" SG_ 1219 BLTN_CAM_Sen_DEV_NvalueSet "Set of Event  Detection Sensitivity of Driving Mode";
BA_ "GenSigSendType" SG_ 1219 BLTN_CAM_Sen_DEV_NvalueSet 4;
BA_ "UserSigValidity" SG_ 1219 BLTN_CAM_Sen_DEV_NvalueSet 0;
BA_REL_ "GenSigTimeoutTime" BU_SG_REL_ BLTN_CAM SG_ 1219 BLTN_CAM_Sen_DEV_NvalueSet 0;
BA_ "Version" SG_ 1219 BLTN_CAM_Sen_DEV_NvalueSet "21.05.02";
BA_ "Description" SG_ 1219 BLTN_CAM_Sen_PEV_NvalueSet "Set of Event  Detection Sensitivity of Parking Mode";
BA_ "GenSigSendType" SG_ 1219 BLTN_CAM_Sen_PEV_NvalueSet 4;
BA_ "UserSigValidity" SG_ 1219 BLTN_CAM_Sen_PEV_NvalueSet 0;
BA_REL_ "GenSigTimeoutTime" BU_SG_REL_ BLTN_CAM SG_ 1219 BLTN_CAM_Sen_PEV_NvalueSet 0;
BA_ "Version" SG_ 1219 BLTN_CAM_Sen_PEV_NvalueSet "21.05.02";
BA_ "Description" SG_ 1219 BLTN_CAM_Rec_PEV_NvalueSet "Record Set of Parked Event, 0x0(Default) : Parking recording function not supported";
BA_ "GenSigSendType" SG_ 1219 BLTN_CAM_Rec_PEV_NvalueSet 4;
BA_ "UserSigValidity" SG_ 1219 BLTN_CAM_Rec_PEV_NvalueSet 0;
BA_REL_ "GenSigTimeoutTime" BU_SG_REL_ BLTN_CAM SG_ 1219 BLTN_CAM_Rec_PEV_NvalueSet 0;
BA_ "Version" SG_ 1219 BLTN_CAM_Rec_PEV_NvalueSet "21.05.02";
BA_ "Description" SG_ 1219 BLTN_CAM_AudRec_NvalueSet "Audio Record On/Off Set";
BA_ "GenSigSendType" SG_ 1219 BLTN_CAM_AudRec_NvalueSet 4;
BA_ "UserSigValidity" SG_ 1219 BLTN_CAM_AudRec_NvalueSet 0;
BA_REL_ "GenSigTimeoutTime" BU_SG_REL_ BLTN_CAM SG_ 1219 BLTN_CAM_AudRec_NvalueSet 0;
BA_ "Version" SG_ 1219 BLTN_CAM_AudRec_NvalueSet "21.06.10";
BA_ "GenMsgCycleTime" BO_ 172 0;
BA_ "Description" SG_ 172 BLTN_CAM_FR_VerPos_NvalueSet "Front Camera Vertical position setting value.";
BA_ "GenSigSendType" SG_ 172 BLTN_CAM_FR_VerPos_NvalueSet 4;
BA_ "GenSigStartValue" SG_ 172 BLTN_CAM_FR_VerPos_NvalueSet 31;
BA_ "UserSigValidity" SG_ 172 BLTN_CAM_FR_VerPos_NvalueSet 0;
BA_REL_ "GenSigTimeoutTime" BU_SG_REL_ BLTN_CAM SG_ 172 BLTN_CAM_FR_VerPos_NvalueSet 0;
BA_ "Version" SG_ 172 BLTN_CAM_FR_VerPos_NvalueSet "23.04.02";
BA_ "Description" SG_ 172 BLTN_CAM_AppNoti_PEV_NvalueSet "Parked Event notification to Connectivity Phone App. On/Off";
BA_ "GenSigSendType" SG_ 172 BLTN_CAM_AppNoti_PEV_NvalueSet 4;
BA_ "UserSigValidity" SG_ 172 BLTN_CAM_AppNoti_PEV_NvalueSet 0;
BA_REL_ "GenSigTimeoutTime" BU_SG_REL_ BLTN_CAM SG_ 172 BLTN_CAM_AppNoti_PEV_NvalueSet 0;
BA_ "Version" SG_ 172 BLTN_CAM_AppNoti_PEV_NvalueSet "21.05.02";
BA_ "Description" SG_ 172 BLTN_CAM_WiFi_AutoOn_NvalueSet "Wifi On/Off User setting";
BA_ "GenSigSendType" SG_ 172 BLTN_CAM_WiFi_AutoOn_NvalueSet 4;
BA_ "UserSigValidity" SG_ 172 BLTN_CAM_WiFi_AutoOn_NvalueSet 0;
BA_REL_ "GenSigTimeoutTime" BU_SG_REL_ BLTN_CAM SG_ 172 BLTN_CAM_WiFi_AutoOn_NvalueSet 0;
BA_ "Version" SG_ 172 BLTN_CAM_WiFi_AutoOn_NvalueSet "21.05.02";
BA_ "Description" SG_ 172 BLTN_CAM_StoProp_NvalueSet "Propotion of built-in Cam SD card Propotion set of the Recording Categories";
BA_ "GenSigSendType" SG_ 172 BLTN_CAM_StoProp_NvalueSet 4;
BA_ "UserSigValidity" SG_ 172 BLTN_CAM_StoProp_NvalueSet 0;
BA_REL_ "GenSigTimeoutTime" BU_SG_REL_ BLTN_CAM SG_ 172 BLTN_CAM_StoProp_NvalueSet 0;
BA_ "Version" SG_ 172 BLTN_CAM_StoProp_NvalueSet "21.05.02";
BA_ "Description" SG_ 172 CF_AVN_BLTN_CAM_USMReset "Buit-in Cam USM Reset Request.";
BA_ "GenSigSendType" SG_ 172 CF_AVN_BLTN_CAM_USMReset 4;
BA_ "UserSigValidity" SG_ 172 CF_AVN_BLTN_CAM_USMReset 0;
BA_REL_ "GenSigTimeoutTime" BU_SG_REL_ BLTN_CAM SG_ 172 CF_AVN_BLTN_CAM_USMReset 0;
BA_ "Version" SG_ 172 CF_AVN_BLTN_CAM_USMReset "21.05.02";
BA_ "Description" SG_ 172 CF_AVN_BLTN_CAM_RecReset "Buit-in Cam format(all file delete/Reset) Request.";
BA_ "GenSigSendType" SG_ 172 CF_AVN_BLTN_CAM_RecReset 4;
BA_ "UserSigValidity" SG_ 172 CF_AVN_BLTN_CAM_RecReset 0;
BA_REL_ "GenSigTimeoutTime" BU_SG_REL_ BLTN_CAM SG_ 172 CF_AVN_BLTN_CAM_RecReset 0;
BA_ "Version" SG_ 172 CF_AVN_BLTN_CAM_RecReset "21.05.02";
BA_ "Description" SG_ 172 BLTN_CAM_File_DEL_CPY_Cmd "Buit-in Cam operation control of copying and deleting.";
BA_ "GenSigSendType" SG_ 172 BLTN_CAM_File_DEL_CPY_Cmd 4;
BA_ "UserSigValidity" SG_ 172 BLTN_CAM_File_DEL_CPY_Cmd 0;
BA_REL_ "GenSigTimeoutTime" BU_SG_REL_ BLTN_CAM SG_ 172 BLTN_CAM_File_DEL_CPY_Cmd 0;
BA_ "Version" SG_ 172 BLTN_CAM_File_DEL_CPY_Cmd "21.05.02";
BA_ "Description" SG_ 172 BLTN_CAM_LVDS_Mode_Cmd "This Signal is for LVDS output commend to BLTN_CAM";
BA_ "GenSigSendType" SG_ 172 BLTN_CAM_LVDS_Mode_Cmd 4;
BA_ "UserSigValidity" SG_ 172 BLTN_CAM_LVDS_Mode_Cmd 0;
BA_REL_ "GenSigTimeoutTime" BU_SG_REL_ BLTN_CAM SG_ 172 BLTN_CAM_LVDS_Mode_Cmd 0;
BA_ "Version" SG_ 172 BLTN_CAM_LVDS_Mode_Cmd "21.05.02";
BA_ "Description" SG_ 172 HU_BLTN_CAM_Disp_Touch_Pos_X "X position of touch of display when BLTN-in CAM Engineer mode in";
BA_ "GenSigSendType" SG_ 172 HU_BLTN_CAM_Disp_Touch_Pos_X 4;
BA_ "UserSigValidity" SG_ 172 HU_BLTN_CAM_Disp_Touch_Pos_X 0;
BA_REL_ "GenSigTimeoutTime" BU_SG_REL_ BLTN_CAM SG_ 172 HU_BLTN_CAM_Disp_Touch_Pos_X 0;
BA_ "Version" SG_ 172 HU_BLTN_CAM_Disp_Touch_Pos_X "21.05.02";
BA_ "Description" SG_ 172 HU_BLTN_CAM_Disp_Touch_Pos_Y "Y position of touch of display when BLTN-in CAM Engineer mode in";
BA_ "GenSigSendType" SG_ 172 HU_BLTN_CAM_Disp_Touch_Pos_Y 4;
BA_ "UserSigValidity" SG_ 172 HU_BLTN_CAM_Disp_Touch_Pos_Y 0;
BA_REL_ "GenSigTimeoutTime" BU_SG_REL_ BLTN_CAM SG_ 172 HU_BLTN_CAM_Disp_Touch_Pos_Y 0;
BA_ "Version" SG_ 172 HU_BLTN_CAM_Disp_Touch_Pos_Y "21.05.02";
BA_ "Description" SG_ 172 MEV_Rec_Req "HU ¡æ BLTN_CAM Manual Event Record request.";
BA_ "GenSigSendType" SG_ 172 MEV_Rec_Req 4;
BA_ "UserSigValidity" SG_ 172 MEV_Rec_Req 0;
BA_REL_ "GenSigTimeoutTime" BU_SG_REL_ BLTN_CAM SG_ 172 MEV_Rec_Req 0;
BA_ "Version" SG_ 172 MEV_Rec_Req "22.04.02";
BA_ "Description" SG_ 172 BLTN_CAM_RR_VerPos_NvalueSet "Rear Camera Vertical position setting value.";
BA_ "GenSigSendType" SG_ 172 BLTN_CAM_RR_VerPos_NvalueSet 4;
BA_ "GenSigStartValue" SG_ 172 BLTN_CAM_RR_VerPos_NvalueSet 31;
BA_ "UserSigValidity" SG_ 172 BLTN_CAM_RR_VerPos_NvalueSet 0;
BA_REL_ "GenSigTimeoutTime" BU_SG_REL_ BLTN_CAM SG_ 172 BLTN_CAM_RR_VerPos_NvalueSet 0;
BA_ "Version" SG_ 172 BLTN_CAM_RR_VerPos_NvalueSet "23.04.02";
BA_ "Description" SG_ 172 TML_Rec_Req "HU ¡æ BLTN_CAM Time lapse Start and End Request.";
BA_ "GenSigSendType" SG_ 172 TML_Rec_Req 4;
BA_ "UserSigValidity" SG_ 172 TML_Rec_Req 0;
BA_REL_ "GenSigTimeoutTime" BU_SG_REL_ BLTN_CAM SG_ 172 TML_Rec_Req 0;
BA_ "Version" SG_ 172 TML_Rec_Req "22.04.02";
BA_ "Description" SG_ 172 BLTN_CAM_SD_Card_UnMt_Mt_Req "Built-in Cam Unmount and Mount Request.";
BA_ "GenSigSendType" SG_ 172 BLTN_CAM_SD_Card_UnMt_Mt_Req 4;
BA_ "UserSigValidity" SG_ 172 BLTN_CAM_SD_Card_UnMt_Mt_Req 0;
BA_REL_ "GenSigTimeoutTime" BU_SG_REL_ BLTN_CAM SG_ 172 BLTN_CAM_SD_Card_UnMt_Mt_Req 0;
BA_ "Version" SG_ 172 BLTN_CAM_SD_Card_UnMt_Mt_Req "22.05.02";
BA_ "GenMsgSendType" BO_ 1239 0;
BA_ "Description" SG_ 1239 HU_ADMSettingState "The signal transfers ADM Setting Value(On/Off) from HU to other module.";
BA_ "GenSigSendType" SG_ 1239 HU_ADMSettingState 4;
BA_ "UserSigValidity" SG_ 1239 HU_ADMSettingState 0;
BA_ "NetworkRequest" SG_ 1239 HU_ADMSettingState 0;
BA_ "NetworkRequestHoldingTime" SG_ 1239 HU_ADMSettingState 5000;
BA_ "Version" SG_ 1239 HU_ADMSettingState "21.01.07";
BA_ "Description" SG_ 1239 HU_PwrState "Information for the H/U power status



* Do not use HU_VehiclePwr (@HU_Car_PE_01) in new ECU or Logic related with HU power state";
BA_ "GenSigSendType" SG_ 1239 HU_PwrState 4;
BA_ "UserSigValidity" SG_ 1239 HU_PwrState 0;
BA_REL_ "GenSigTimeoutTime" BU_SG_REL_ BLTN_CAM SG_ 1239 HU_PwrState 1500;
BA_ "Version" SG_ 1239 HU_PwrState "22.05.02";
BA_ "Description" SG_ 1239 HU_MKBD_ModeSwitch "This signal is used for the 'AVNT/Climate Switching Keyboard' to switch the display of buttons.";
BA_ "GenSigSendType" SG_ 1239 HU_MKBD_ModeSwitch 4;
BA_ "GenSigStartValue" SG_ 1239 HU_MKBD_ModeSwitch 3;
BA_ "UserSigValidity" SG_ 1239 HU_MKBD_ModeSwitch 1;
BA_ "Version" SG_ 1239 HU_MKBD_ModeSwitch "20.12.04";
BA_ "Description" SG_ 1239 HU_LCDState "Information for H/U LCD (Monitor) On/Off Status";
BA_ "GenSigSendType" SG_ 1239 HU_LCDState 4;
BA_ "UserSigValidity" SG_ 1239 HU_LCDState 0;
BA_ "Version" SG_ 1239 HU_LCDState "22.05.02";
BA_ "Description" SG_ 1239 HU_VehiclePwr "* Use HU_PwrState (@HU_Car_PE_01) in new ECU or Logic related with HU power state";
BA_ "GenSigSendType" SG_ 1239 HU_VehiclePwr 4;
BA_ "UserSigValidity" SG_ 1239 HU_VehiclePwr 0;
BA_REL_ "GenSigTimeoutTime" BU_SG_REL_ BLTN_CAM SG_ 1239 HU_VehiclePwr 1500;
BA_REL_ "GenSigTimeoutTime" BU_SG_REL_ SGU SG_ 1239 HU_VehiclePwr 1500;
BA_ "NetworkRequest" SG_ 1239 HU_VehiclePwr 0;
BA_ "NetworkRequestHoldingTime" SG_ 1239 HU_VehiclePwr 5000;
BA_ "Version" SG_ 1239 HU_VehiclePwr "22.05.02";
BA_ "Description" SG_ 1239 HU_BtnShowReq "This signal indicates requesting turn on/off button light for H/Unit related buttons.";
BA_ "GenSigSendType" SG_ 1239 HU_BtnShowReq 4;
BA_ "GenSigStartValue" SG_ 1239 HU_BtnShowReq 7;
BA_ "UserSigValidity" SG_ 1239 HU_BtnShowReq 0;
BA_REL_ "GenSigTimeoutTime" BU_SG_REL_ SWRC SG_ 1239 HU_BtnShowReq 1500;
BA_ "NetworkRequest" SG_ 1239 HU_BtnShowReq 0;
BA_ "NetworkRequestHoldingTime" SG_ 1239 HU_BtnShowReq 5000;
BA_ "Version" SG_ 1239 HU_BtnShowReq "19.11.01";
BA_ "GenMsgSendType" BO_ 1245 0;
BA_ "Description" SG_ 1245 HU_CampModeSta "Camp mode set siganl";
BA_ "GenSigSendType" SG_ 1245 HU_CampModeSta 4;
BA_ "UserSigValidity" SG_ 1245 HU_CampModeSta 7;
BA_REL_ "GenSigTimeoutTime" BU_SG_REL_ SWRC SG_ 1245 HU_CampModeSta 1500;
BA_ "Version" SG_ 1245 HU_CampModeSta "22.08.01";
BA_ "Description" SG_ 1245 HU_LatchHoldReq "Request Signal for Latchlod of control uni to get valid info during HU ADM condition";
BA_ "GenSigSendType" SG_ 1245 HU_LatchHoldReq 4;
BA_ "GenSigStartValue" SG_ 1245 HU_LatchHoldReq 3;
BA_ "TimeoutValue" SG_ 1245 HU_LatchHoldReq "0x3";
BA_ "UserSigValidity" SG_ 1245 HU_LatchHoldReq 0;
BA_ "Version" SG_ 1245 HU_LatchHoldReq "22.07.05";
BA_ "Description" SG_ 1245 HU_HighPowerChargingkW "High Power Charging Power value(kW) of charger";
BA_ "GenSigSendType" SG_ 1245 HU_HighPowerChargingkW 4;
BA_ "UserSigValidity" SG_ 1245 HU_HighPowerChargingkW 7;
BA_ "Version" SG_ 1245 HU_HighPowerChargingkW "23.01.03";
BA_ "Description" SG_ 1245 HU_FastChargingkW "Fast Power Charging Power value(kW) of charger";
BA_ "GenSigSendType" SG_ 1245 HU_FastChargingkW 4;
BA_ "UserSigValidity" SG_ 1245 HU_FastChargingkW 7;
BA_ "Version" SG_ 1245 HU_FastChargingkW "23.01.03";
BA_ "GenMsgSendType" BO_ 1240 0;
BA_ "GenSigSendType" SG_ 1240 HU_DistanceUnit 4;
BA_ "GenSigStartValue" SG_ 1240 HU_DistanceUnit 3;
BA_ "UserSigValidity" SG_ 1240 HU_DistanceUnit 1;
BA_ "NetworkRequest" SG_ 1240 HU_DistanceUnit 0;
BA_ "Version" SG_ 1240 HU_DistanceUnit "22.06.01";
BA_ "Description" SG_ 1240 HU_ThemeType "This signal indicates current H/Unit GUI theme value. 

 

Detail value -GUI Theme matching table, refer to attachement and ES SPEC";
BA_ "GenSigSendType" SG_ 1240 HU_ThemeType 4;
BA_ "GenSigStartValue" SG_ 1240 HU_ThemeType 15;
BA_ "UserSigValidity" SG_ 1240 HU_ThemeType 0;
BA_REL_ "GenSigTimeoutTime" BU_SG_REL_ ATS SG_ 1240 HU_ThemeType 1500;
BA_REL_ "GenSigTimeoutTime" BU_SG_REL_ BLTN_CAM SG_ 1240 HU_ThemeType 1500;
BA_ "Version" SG_ 1240 HU_ThemeType "22.06.01";
BA_ "GenSigSendType" SG_ 1240 HU_MicActivity 4;
BA_ "GenSigStartValue" SG_ 1240 HU_MicActivity 3;
BA_ "UserSigValidity" SG_ 1240 HU_MicActivity 0;
BA_ "Version" SG_ 1240 HU_MicActivity "22.06.01";
BA_ "Description" SG_ 1240 HU_Scheduled_Setting "Information of scheduled update charge setting

The signal means that scheduled update charaging information send to BMS for BMS SOC control";
BA_ "GenSigSendType" SG_ 1240 HU_Scheduled_Setting 4;
BA_ "UserSigValidity" SG_ 1240 HU_Scheduled_Setting 3;
BA_ "Version" SG_ 1240 HU_Scheduled_Setting "22.06.01";
BA_ "Description" SG_ 1240 AVN_RSPA_ModeSelect "Signal for User's RSPA¥± mode setting

RSPA¥± ¸ðµå ¼±ÅÃ ¸Þ´º CCP Focus ¹× CCP Confirm or Touch °á°ú";
BA_ "GenSigSendType" SG_ 1240 AVN_RSPA_ModeSelect 4;
BA_ "GenSigStartValue" SG_ 1240 AVN_RSPA_ModeSelect 15;
BA_ "UserSigValidity" SG_ 1240 AVN_RSPA_ModeSelect 0;
BA_ "Version" SG_ 1240 AVN_RSPA_ModeSelect "23.10.01";
BA_ "GenSigSendType" SG_ 1240 CF_HU_GPSFlt 4;
BA_ "GenSigStartValue" SG_ 1240 CF_HU_GPSFlt 2;
BA_ "TimeoutValue" SG_ 1240 CF_HU_GPSFlt "0x2";
BA_ "UserSigValidity" SG_ 1240 CF_HU_GPSFlt 0;
BA_ "Version" SG_ 1240 CF_HU_GPSFlt "22.06.01";
BA_ "GenSigSendType" SG_ 1240 AVN_RSPA_CancelInput 4;
BA_ "UserSigValidity" SG_ 1240 AVN_RSPA_CancelInput 0;
BA_ "Version" SG_ 1240 AVN_RSPA_CancelInput "22.06.01";
BA_ "GenSigSendType" SG_ 1240 AVN_RSPA_Disp_Rdy 4;
BA_ "GenSigStartValue" SG_ 1240 AVN_RSPA_Disp_Rdy 3;
BA_ "UserSigValidity" SG_ 1240 AVN_RSPA_Disp_Rdy 0;
BA_ "Version" SG_ 1240 AVN_RSPA_Disp_Rdy "22.06.01";
BA_ "Description" SG_ 1240 CF_AVN_ProfileIDRValue "Profile 3~Profile9 value is only used from Vehicle Architecture 2.0 (STD_DB_CAR_R2, SV 24.6~) vehicle models

Vehicle Architecture 1.0 (STD_DB_CAR) vehicle models can use Guest, Profile1, Profile 2 only.";
BA_ "GenSigSendType" SG_ 1240 CF_AVN_ProfileIDRValue 4;
BA_ "GenSigStartValue" SG_ 1240 CF_AVN_ProfileIDRValue 15;
BA_ "UserSigValidity" SG_ 1240 CF_AVN_ProfileIDRValue 0;
BA_REL_ "GenSigTimeoutTime" BU_SG_REL_ BLTN_CAM SG_ 1240 CF_AVN_ProfileIDRValue 1500;
BA_REL_ "GenSigTimeoutTime" BU_SG_REL_ GW_DLBCU SG_ 1240 CF_AVN_ProfileIDRValue 1500;
BA_REL_ "GenSigTimeoutTime" BU_SG_REL_ GW_DPSU SG_ 1240 CF_AVN_ProfileIDRValue 1500;
BA_REL_ "GenSigTimeoutTime" BU_SG_REL_ RCM SG_ 1240 CF_AVN_ProfileIDRValue 1500;
BA_REL_ "GenSigTimeoutTime" BU_SG_REL_ RWPC SG_ 1240 CF_AVN_ProfileIDRValue 1500;
BA_REL_ "GenSigTimeoutTime" BU_SG_REL_ SGU SG_ 1240 CF_AVN_ProfileIDRValue 1500;
BA_REL_ "GenSigTimeoutTime" BU_SG_REL_ WPC SG_ 1240 CF_AVN_ProfileIDRValue 1500;
BA_REL_ "GenSigTimeoutTime" BU_SG_REL_ WPC2 SG_ 1240 CF_AVN_ProfileIDRValue 1500;
BA_ "Version" SG_ 1240 CF_AVN_ProfileIDRValue "22.11.24";
BA_ "GenSigSendType" SG_ 1240 HazardFromHUSVM 4;
BA_ "GenSigStartValue" SG_ 1240 HazardFromHUSVM 3;
BA_ "UserSigValidity" SG_ 1240 HazardFromHUSVM 0;
BA_ "Version" SG_ 1240 HazardFromHUSVM "22.06.01";
BA_ "GenSigSendType" SG_ 1240 OMUOSMirCtrl 4;
BA_ "GenSigStartValue" SG_ 1240 OMUOSMirCtrl 3;
BA_ "UserSigValidity" SG_ 1240 OMUOSMirCtrl 0;
BA_ "Version" SG_ 1240 OMUOSMirCtrl "22.06.01";
BA_ "Description" SG_ 1240 OTAUIStatus "0x00 : Headunit is booting so, Headunit can't display any state

0x01 : Headunit is normal state, Headunit could display according to CCU command.";
BA_ "GenSigSendType" SG_ 1240 OTAUIStatus 4;
BA_ "UserSigValidity" SG_ 1240 OTAUIStatus 0;
BA_ "Version" SG_ 1240 OTAUIStatus "22.06.01";
BA_ "GenSigSendType" SG_ 1240 C_TeleActiveStatus 4;
BA_ "GenSigStartValue" SG_ 1240 C_TeleActiveStatus 3;
BA_ "UserSigValidity" SG_ 1240 C_TeleActiveStatus 0;
BA_ "Version" SG_ 1240 C_TeleActiveStatus "22.06.01";
BA_ "GenSigSendType" SG_ 1240 HU_AliveStatus 4;
BA_ "GenSigStartValue" SG_ 1240 HU_AliveStatus 3;
BA_ "UserSigValidity" SG_ 1240 HU_AliveStatus 0;
BA_ "NetworkRequest" SG_ 1240 HU_AliveStatus 0;
BA_ "Version" SG_ 1240 HU_AliveStatus "22.06.01";
BA_ "GenSigSendType" SG_ 1240 HU_RTCCheck 4;
BA_ "GenSigStartValue" SG_ 1240 HU_RTCCheck 3;
BA_ "TimeoutValue" SG_ 1240 HU_RTCCheck "0x3";
BA_ "UserSigValidity" SG_ 1240 HU_RTCCheck 3;
BA_REL_ "GenSigTimeoutTime" BU_SG_REL_ GW_APSU SG_ 1240 HU_RTCCheck 1500;
BA_ "Version" SG_ 1240 HU_RTCCheck "22.06.01";
BA_ "GenMsgSendType" BO_ 1247 0;
BA_ "GenSigSendType" SG_ 1247 Navi_ParkingLot 4;
BA_ "UserSigValidity" SG_ 1247 Navi_ParkingLot 3;
BA_ "Version" SG_ 1247 Navi_ParkingLot "22.07.05";
BA_ "GenSigSendType" SG_ 1247 Navi_AirConditionWarning 4;
BA_ "GenSigStartValue" SG_ 1247 Navi_AirConditionWarning 3;
BA_ "UserSigValidity" SG_ 1247 Navi_AirConditionWarning 3;
BA_REL_ "GenSigTimeoutTime" BU_SG_REL_ RCM SG_ 1247 Navi_AirConditionWarning 1500;
BA_ "Version" SG_ 1247 Navi_AirConditionWarning "22.07.05";
BA_ "Description" SG_ 1247 ADP_NActiveSound "This signal transmits information about whether the vehicle is on a circuit or not.

0x0:None - No information about vehicle location

0x1:On the circuit track - Vehicle is on the circuit track

0x2:In the circuit area - The vehicle is not on a circuit track and is located close to the circuit area

0x3:Out of circuit area - The vehicle is not even located near the circuit area";
BA_ "GenSigSendType" SG_ 1247 ADP_NActiveSound 4;
BA_ "UserSigValidity" SG_ 1247 ADP_NActiveSound 3;
BA_ "Version" SG_ 1247 ADP_NActiveSound "23.02.02";
BA_ "GenMsgCycleTime" BO_ 1218 0;
BA_ "Description" SG_ 1218 C_AVN_PTGHeightNValueSet "18.08.09_";
BA_ "GenSigSendType" SG_ 1218 C_AVN_PTGHeightNValueSet 4;
BA_ "UserSigValidity" SG_ 1218 C_AVN_PTGHeightNValueSet 3;
BA_ "Version" SG_ 1218 C_AVN_PTGHeightNValueSet "19.02.07";
BA_ "Description" SG_ 1218 CF_AVN_SCCMLReset "18.08.09_";
BA_ "GenSigSendType" SG_ 1218 CF_AVN_SCCMLReset 4;
BA_ "UserSigValidity" SG_ 1218 CF_AVN_SCCMLReset 3;
BA_ "Version" SG_ 1218 CF_AVN_SCCMLReset "18.09.04";
BA_ "Description" SG_ 1218 C_TgltAwayCloseNValue "USM Request for Tailgate Away Close";
BA_ "GenSigSendType" SG_ 1218 C_TgltAwayCloseNValue 4;
BA_ "UserSigValidity" SG_ 1218 C_TgltAwayCloseNValue 3;
BA_ "Version" SG_ 1218 C_TgltAwayCloseNValue "19.01.10";
BA_ "Description" SG_ 1218 C_HAnBNValueSet "18.08.09_";
BA_ "GenSigSendType" SG_ 1218 C_HAnBNValueSet 4;
BA_ "UserSigValidity" SG_ 1218 C_HAnBNValueSet 3;
BA_ "Version" SG_ 1218 C_HAnBNValueSet "18.09.04";
BA_ "Description" SG_ 1218 CF_AVN_RrSeatRemindNValueSet "18.08.09_";
BA_ "GenSigSendType" SG_ 1218 CF_AVN_RrSeatRemindNValueSet 4;
BA_ "UserSigValidity" SG_ 1218 CF_AVN_RrSeatRemindNValueSet 3;
BA_ "Version" SG_ 1218 CF_AVN_RrSeatRemindNValueSet "18.09.04";
BA_ "Description" SG_ 1218 CF_AVN_DSWNValueSet "18.08.09_";
BA_ "GenSigSendType" SG_ 1218 CF_AVN_DSWNValueSet 4;
BA_ "UserSigValidity" SG_ 1218 CF_AVN_DSWNValueSet 3;
BA_ "Version" SG_ 1218 CF_AVN_DSWNValueSet "18.09.04";
BA_ "Description" SG_ 1218 CF_AVN_RRPSU_RLNValueSet "18.08.09_";
BA_ "GenSigSendType" SG_ 1218 CF_AVN_RRPSU_RLNValueSet 4;
BA_ "UserSigValidity" SG_ 1218 CF_AVN_RRPSU_RLNValueSet 3;
BA_REL_ "GenSigTimeoutTime" BU_SG_REL_ GW_APSU SG_ 1218 CF_AVN_RRPSU_RLNValueSet 0;
BA_REL_ "GenSigTimeoutTime" BU_SG_REL_ GW_RLPSU SG_ 1218 CF_AVN_RRPSU_RLNValueSet 0;
BA_REL_ "GenSigTimeoutTime" BU_SG_REL_ GW_RRPSU SG_ 1218 CF_AVN_RRPSU_RLNValueSet 0;
BA_ "Version" SG_ 1218 CF_AVN_RRPSU_RLNValueSet "18.09.04";
BA_ "Description" SG_ 1218 CF_AVN_APSUNValueSet "18.08.09_";
BA_ "GenSigSendType" SG_ 1218 CF_AVN_APSUNValueSet 4;
BA_ "UserSigValidity" SG_ 1218 CF_AVN_APSUNValueSet 3;
BA_REL_ "GenSigTimeoutTime" BU_SG_REL_ GW_APSU SG_ 1218 CF_AVN_APSUNValueSet 0;
BA_ "Version" SG_ 1218 CF_AVN_APSUNValueSet "18.09.04";
BA_ "Description" SG_ 1218 CF_AVN_NCC_CameraNValueSet "18.08.09_";
BA_ "GenSigSendType" SG_ 1218 CF_AVN_NCC_CameraNValueSet 4;
BA_ "UserSigValidity" SG_ 1218 CF_AVN_NCC_CameraNValueSet 3;
BA_ "Version" SG_ 1218 CF_AVN_NCC_CameraNValueSet "18.09.04";
BA_ "Description" SG_ 1218 CF_AVN_RRPSU_RRNValueSet "18.08.09_";
BA_ "GenSigSendType" SG_ 1218 CF_AVN_RRPSU_RRNValueSet 4;
BA_ "UserSigValidity" SG_ 1218 CF_AVN_RRPSU_RRNValueSet 3;
BA_REL_ "GenSigTimeoutTime" BU_SG_REL_ GW_APSU SG_ 1218 CF_AVN_RRPSU_RRNValueSet 0;
BA_REL_ "GenSigTimeoutTime" BU_SG_REL_ GW_RLPSU SG_ 1218 CF_AVN_RRPSU_RRNValueSet 0;
BA_REL_ "GenSigTimeoutTime" BU_SG_REL_ GW_RRPSU SG_ 1218 CF_AVN_RRPSU_RRNValueSet 0;
BA_ "Version" SG_ 1218 CF_AVN_RRPSU_RRNValueSet "18.09.04";
BA_ "Description" SG_ 1218 CF_AVN_HtBlcAstNValueSet "18.08.09_";
BA_ "GenSigSendType" SG_ 1218 CF_AVN_HtBlcAstNValueSet 4;
BA_ "UserSigValidity" SG_ 1218 CF_AVN_HtBlcAstNValueSet 3;
BA_REL_ "GenSigTimeoutTime" BU_SG_REL_ GW_APSU SG_ 1218 CF_AVN_HtBlcAstNValueSet 0;
BA_REL_ "GenSigTimeoutTime" BU_SG_REL_ SHVU_FR SG_ 1218 CF_AVN_HtBlcAstNValueSet 0;
BA_ "Version" SG_ 1218 CF_AVN_HtBlcAstNValueSet "18.09.04";
BA_ "Description" SG_ 1218 CF_AVN_HtBlcDrvNValueSet "18.08.09_";
BA_ "GenSigSendType" SG_ 1218 CF_AVN_HtBlcDrvNValueSet 4;
BA_ "UserSigValidity" SG_ 1218 CF_AVN_HtBlcDrvNValueSet 3;
BA_REL_ "GenSigTimeoutTime" BU_SG_REL_ GW_APSU SG_ 1218 CF_AVN_HtBlcDrvNValueSet 0;
BA_REL_ "GenSigTimeoutTime" BU_SG_REL_ GW_DPSU SG_ 1218 CF_AVN_HtBlcDrvNValueSet 0;
BA_REL_ "GenSigTimeoutTime" BU_SG_REL_ SHVU_FR SG_ 1218 CF_AVN_HtBlcDrvNValueSet 0;
BA_ "Version" SG_ 1218 CF_AVN_HtBlcDrvNValueSet "18.09.04";
BA_ "Description" SG_ 1218 CF_AVN_SCCModeNValueSet "18.12.03_";
BA_ "GenSigSendType" SG_ 1218 CF_AVN_SCCModeNValueSet 4;
BA_ "GenSigStartValue" SG_ 1218 CF_AVN_SCCModeNValueSet 3;
BA_ "UserSigValidity" SG_ 1218 CF_AVN_SCCModeNValueSet 3;
BA_ "Version" SG_ 1218 CF_AVN_SCCModeNValueSet "18.12.03";
BA_ "GenSigSendType" SG_ 1218 CF_AVN_SCCMLChar1Set 4;
BA_ "UserSigValidity" SG_ 1218 CF_AVN_SCCMLChar1Set 3;
BA_ "Version" SG_ 1218 CF_AVN_SCCMLChar1Set "19.11.05";
BA_ "Description" SG_ 1218 CF_AVN_UIPNValueSet "18.10.01_";
BA_ "GenSigSendType" SG_ 1218 CF_AVN_UIPNValueSet 4;
BA_ "UserSigValidity" SG_ 1218 CF_AVN_UIPNValueSet 3;
BA_ "Version" SG_ 1218 CF_AVN_UIPNValueSet "18.10.06";
BA_ "GenSigSendType" SG_ 1218 CF_AVN_SCCMLChar2Set 4;
BA_ "UserSigValidity" SG_ 1218 CF_AVN_SCCMLChar2Set 3;
BA_ "Version" SG_ 1218 CF_AVN_SCCMLChar2Set "19.11.05";
BA_ "GenSigSendType" SG_ 1218 CF_AVN_SCCMLChar3Set 4;
BA_ "UserSigValidity" SG_ 1218 CF_AVN_SCCMLChar3Set 3;
BA_ "Version" SG_ 1218 CF_AVN_SCCMLChar3Set "19.11.05";
BA_ "Description" SG_ 1218 CF_AVN_HDALCFuncNValueSet "18.08.09_";
BA_ "GenSigSendType" SG_ 1218 CF_AVN_HDALCFuncNValueSet 4;
BA_ "UserSigValidity" SG_ 1218 CF_AVN_HDALCFuncNValueSet 3;
BA_ "Version" SG_ 1218 CF_AVN_HDALCFuncNValueSet "18.09.04";
BA_ "GenMsgCycleTime" BO_ 1251 0;
BA_ "Description" SG_ 1251 IAU_Crc13Val "The data area for CRC calculation is based on the data length (DLC) of the message DB.

The CRC shall be calculated over the entire data block (excluding the CRC bytes) including the user data, alive counter and Data ID 

 

- CRC Polynomial (0x1D) , Initial Value : 0x00, XOR value : 0xFF, Data ID Mode : Both, Data ID : Message ID + 0xF800 

- The initial value is for CRC calculation and the message should be sent with the calculated result value. 

The mathematical expression to 8 bit CRC polynomial is given here. G(x) = x8 + x4 + x3 + x2 + 1";
BA_ "GenSigSendType" SG_ 1251 IAU_Crc13Val 4;
BA_ "UserSigValidity" SG_ 1251 IAU_Crc13Val 0;
BA_ "Version" SG_ 1251 IAU_Crc13Val "21.09.03";
BA_ "Description" SG_ 1251 IAU_AlvCnt13Val "For the first transmission request for a data element the counter shall be initialized with 0 and shall be incremented by 1

for every subsequent send request. When the counter reaches the maximum value(0xE), then it shall restart with 0 for the next send request";
BA_ "GenSigSendType" SG_ 1251 IAU_AlvCnt13Val 4;
BA_ "UserSigValidity" SG_ 1251 IAU_AlvCnt13Val 0;
BA_ "Version" SG_ 1251 IAU_AlvCnt13Val "21.09.03";
BA_ "Description" SG_ 1251 IAU_EsyAcsProfileID "This signal indicate the current detected profile ID by NFC.

(The drv seat move to the easy access position of the detected profile ID when receive the signal)";
BA_ "GenSigSendType" SG_ 1251 IAU_EsyAcsProfileID 4;
BA_ "UserSigValidity" SG_ 1251 IAU_EsyAcsProfileID 0;
BA_REL_ "GenSigTimeoutTime" BU_SG_REL_ GW_DPSU SG_ 1251 IAU_EsyAcsProfileID 0;
BA_ "NetworkRequest" SG_ 1251 IAU_EsyAcsProfileID 0;
BA_ "NetworkRequestHoldingTime" SG_ 1251 IAU_EsyAcsProfileID 5;
BA_ "Version" SG_ 1251 IAU_EsyAcsProfileID "18.08.12";
BA_ "Description" SG_ 1251 IAU_SmrtPhnID "SmartPhone ID with BLE Connection";
BA_ "GenSigSendType" SG_ 1251 IAU_SmrtPhnID 4;
BA_ "UserSigValidity" SG_ 1251 IAU_SmrtPhnID 0;
BA_ "NetworkRequest" SG_ 1251 IAU_SmrtPhnID 0;
BA_ "NetworkRequestHoldingTime" SG_ 1251 IAU_SmrtPhnID 5;
BA_ "Version" SG_ 1251 IAU_SmrtPhnID "20.04.06";
BA_ "Description" SG_ 1251 IAU_SmrtPhnCmd "SmartPhone RKE Command Indi";
BA_ "GenSigSendType" SG_ 1251 IAU_SmrtPhnCmd 4;
BA_ "UserSigValidity" SG_ 1251 IAU_SmrtPhnCmd 0;
BA_ "NetworkRequest" SG_ 1251 IAU_SmrtPhnCmd 0;
BA_ "NetworkRequestHoldingTime" SG_ 1251 IAU_SmrtPhnCmd 5000;
BA_ "Version" SG_ 1251 IAU_SmrtPhnCmd "23.02.02";
BA_ "Description" SG_ 1251 IAUwFRU_ISK_LearningReq "This signal is to request ISK learning to FRU";
BA_ "GenSigSendType" SG_ 1251 IAUwFRU_ISK_LearningReq 4;
BA_ "UserSigValidity" SG_ 1251 IAUwFRU_ISK_LearningReq 0;
BA_ "NetworkRequest" SG_ 1251 IAUwFRU_ISK_LearningReq 0;
BA_ "NetworkRequestHoldingTime" SG_ 1251 IAUwFRU_ISK_LearningReq 5;
BA_ "Version" SG_ 1251 IAUwFRU_ISK_LearningReq "20.05.02";
BA_ "Description" SG_ 1251 IAUwFPM_ISK_LearningReq "This signal is to request ISK learning to FPM";
BA_ "GenSigSendType" SG_ 1251 IAUwFPM_ISK_LearningReq 4;
BA_ "UserSigValidity" SG_ 1251 IAUwFPM_ISK_LearningReq 0;
BA_ "NetworkRequest" SG_ 1251 IAUwFPM_ISK_LearningReq 0;
BA_ "NetworkRequestHoldingTime" SG_ 1251 IAUwFPM_ISK_LearningReq 5;
BA_ "Version" SG_ 1251 IAUwFPM_ISK_LearningReq "20.05.02";
BA_ "Description" SG_ 1251 IAU2FRU_ISKLearnFdbck "This isgnla is learning feedback";
BA_ "GenSigSendType" SG_ 1251 IAU2FRU_ISKLearnFdbck 4;
BA_ "UserSigValidity" SG_ 1251 IAU2FRU_ISKLearnFdbck 0;
BA_ "NetworkRequest" SG_ 1251 IAU2FRU_ISKLearnFdbck 0;
BA_ "NetworkRequestHoldingTime" SG_ 1251 IAU2FRU_ISKLearnFdbck 5;
BA_ "Version" SG_ 1251 IAU2FRU_ISKLearnFdbck "20.04.05";
BA_ "Description" SG_ 1251 IAU2FPM_ISKLearnFdbck "This signal is learning feedback";
BA_ "GenSigSendType" SG_ 1251 IAU2FPM_ISKLearnFdbck 4;
BA_ "UserSigValidity" SG_ 1251 IAU2FPM_ISKLearnFdbck 0;
BA_ "NetworkRequest" SG_ 1251 IAU2FPM_ISKLearnFdbck 0;
BA_ "NetworkRequestHoldingTime" SG_ 1251 IAU2FPM_ISKLearnFdbck 5;
BA_ "Version" SG_ 1251 IAU2FPM_ISKLearnFdbck "20.04.05";
BA_ "Description" SG_ 1251 RSPA_FuncInfo "RSPA Function selection";
BA_ "GenSigSendType" SG_ 1251 RSPA_FuncInfo 4;
BA_ "UserSigValidity" SG_ 1251 RSPA_FuncInfo 0;
BA_ "NetworkRequest" SG_ 1251 RSPA_FuncInfo 0;
BA_ "NetworkRequestHoldingTime" SG_ 1251 RSPA_FuncInfo 5000;
BA_ "Version" SG_ 1251 RSPA_FuncInfo "23.02.02";
BA_ "GenMsgCycleTime" BO_ 1227 0;
BA_ "Description" SG_ 1227 DrvIMS_MemoryP1Req "-(Old)C_MEMP1CMD";
BA_ "GenSigSendType" SG_ 1227 DrvIMS_MemoryP1Req 4;
BA_ "UserSigValidity" SG_ 1227 DrvIMS_MemoryP1Req 0;
BA_REL_ "GenSigTimeoutTime" BU_SG_REL_ CGW_CCU SG_ 1227 DrvIMS_MemoryP1Req 0;
BA_ "NetworkRequest" SG_ 1227 DrvIMS_MemoryP1Req 0;
BA_ "NetworkRequestHoldingTime" SG_ 1227 DrvIMS_MemoryP1Req 5000;
BA_ "Version" SG_ 1227 DrvIMS_MemoryP1Req "17.11.00";
BA_ "GenSigSendType" SG_ 1227 DrvIMS_PlyBckP2Req 4;
BA_ "UserSigValidity" SG_ 1227 DrvIMS_PlyBckP2Req 0;
BA_REL_ "GenSigTimeoutTime" BU_SG_REL_ CGW_CCU SG_ 1227 DrvIMS_PlyBckP2Req 0;
BA_ "NetworkRequest" SG_ 1227 DrvIMS_PlyBckP2Req 0;
BA_ "NetworkRequestHoldingTime" SG_ 1227 DrvIMS_PlyBckP2Req 5000;
BA_ "Version" SG_ 1227 DrvIMS_PlyBckP2Req "17.11.00";
BA_ "Description" SG_ 1227 DrvIMS_PlyBckP3Req "PLAY IMS3";
BA_ "GenSigSendType" SG_ 1227 DrvIMS_PlyBckP3Req 4;
BA_ "UserSigValidity" SG_ 1227 DrvIMS_PlyBckP3Req 0;
BA_REL_ "GenSigTimeoutTime" BU_SG_REL_ CGW_CCU SG_ 1227 DrvIMS_PlyBckP3Req 0;
BA_ "NetworkRequest" SG_ 1227 DrvIMS_PlyBckP3Req 0;
BA_ "NetworkRequestHoldingTime" SG_ 1227 DrvIMS_PlyBckP3Req 5000;
BA_ "Version" SG_ 1227 DrvIMS_PlyBckP3Req "17.11.00";
BA_ "Description" SG_ 1227 DrvIMS_PlyBckStpReq "This signal is used to stop during playback";
BA_ "GenSigSendType" SG_ 1227 DrvIMS_PlyBckStpReq 4;
BA_ "UserSigValidity" SG_ 1227 DrvIMS_PlyBckStpReq 0;
BA_REL_ "GenSigTimeoutTime" BU_SG_REL_ CGW_CCU SG_ 1227 DrvIMS_PlyBckStpReq 0;
BA_ "NetworkRequest" SG_ 1227 DrvIMS_PlyBckStpReq 0;
BA_ "NetworkRequestHoldingTime" SG_ 1227 DrvIMS_PlyBckStpReq 5000;
BA_ "Version" SG_ 1227 DrvIMS_PlyBckStpReq "17.11.00";
BA_ "Description" SG_ 1227 SmrtIMS_PlyBckReq "Signal for Health Care IMS Playback DB Number";
BA_ "GenSigSendType" SG_ 1227 SmrtIMS_PlyBckReq 4;
BA_ "UserSigValidity" SG_ 1227 SmrtIMS_PlyBckReq 0;
BA_REL_ "GenSigTimeoutTime" BU_SG_REL_ CGW_CCU SG_ 1227 SmrtIMS_PlyBckReq 0;
BA_ "NetworkRequest" SG_ 1227 SmrtIMS_PlyBckReq 0;
BA_ "NetworkRequestHoldingTime" SG_ 1227 SmrtIMS_PlyBckReq 5000;
BA_ "Version" SG_ 1227 SmrtIMS_PlyBckReq "21.07.05";
BA_ "Description" SG_ 1227 DrvIMS_MemoryP2Req "-(Old)C_MEMP2CMD";
BA_ "GenSigSendType" SG_ 1227 DrvIMS_MemoryP2Req 4;
BA_ "UserSigValidity" SG_ 1227 DrvIMS_MemoryP2Req 0;
BA_REL_ "GenSigTimeoutTime" BU_SG_REL_ CGW_CCU SG_ 1227 DrvIMS_MemoryP2Req 0;
BA_ "NetworkRequest" SG_ 1227 DrvIMS_MemoryP2Req 0;
BA_ "NetworkRequestHoldingTime" SG_ 1227 DrvIMS_MemoryP2Req 5000;
BA_ "Version" SG_ 1227 DrvIMS_MemoryP2Req "17.11.00";
BA_ "Description" SG_ 1227 PSM_IMSReq "IMS request";
BA_ "GenSigSendType" SG_ 1227 PSM_IMSReq 4;
BA_ "UserSigValidity" SG_ 1227 PSM_IMSReq 0;
BA_REL_ "GenSigTimeoutTime" BU_SG_REL_ CGW_CCU SG_ 1227 PSM_IMSReq 0;
BA_ "NetworkRequest" SG_ 1227 PSM_IMSReq 0;
BA_ "NetworkRequestHoldingTime" SG_ 1227 PSM_IMSReq 5000;
BA_ "Version" SG_ 1227 PSM_IMSReq "21.02.02";
BA_ "Description" SG_ 1227 SmrtIMS_ImgDBVal "-(Old)C_SmartIMSImageDB";
BA_ "GenSigSendType" SG_ 1227 SmrtIMS_ImgDBVal 4;
BA_ "UserSigValidity" SG_ 1227 SmrtIMS_ImgDBVal 0;
BA_REL_ "GenSigTimeoutTime" BU_SG_REL_ CGW_CCU SG_ 1227 SmrtIMS_ImgDBVal 0;
BA_ "NetworkRequest" SG_ 1227 SmrtIMS_ImgDBVal 0;
BA_ "NetworkRequestHoldingTime" SG_ 1227 SmrtIMS_ImgDBVal 5000;
BA_ "Version" SG_ 1227 SmrtIMS_ImgDBVal "17.11.00";
BA_ "Description" SG_ 1227 SmrtIMS_PlyBckStpReq "Health Care IMS On/Off Flag";
BA_ "GenSigSendType" SG_ 1227 SmrtIMS_PlyBckStpReq 4;
BA_ "UserSigValidity" SG_ 1227 SmrtIMS_PlyBckStpReq 0;
BA_REL_ "GenSigTimeoutTime" BU_SG_REL_ CGW_CCU SG_ 1227 SmrtIMS_PlyBckStpReq 0;
BA_ "NetworkRequest" SG_ 1227 SmrtIMS_PlyBckStpReq 0;
BA_ "NetworkRequestHoldingTime" SG_ 1227 SmrtIMS_PlyBckStpReq 5000;
BA_ "Version" SG_ 1227 SmrtIMS_PlyBckStpReq "17.11.00";
BA_ "Description" SG_ 1227 DrvIMS_MemoryP3Req "Memory IMS3";
BA_ "GenSigSendType" SG_ 1227 DrvIMS_MemoryP3Req 4;
BA_ "UserSigValidity" SG_ 1227 DrvIMS_MemoryP3Req 0;
BA_REL_ "GenSigTimeoutTime" BU_SG_REL_ CGW_CCU SG_ 1227 DrvIMS_MemoryP3Req 0;
BA_ "NetworkRequest" SG_ 1227 DrvIMS_MemoryP3Req 0;
BA_ "NetworkRequestHoldingTime" SG_ 1227 DrvIMS_MemoryP3Req 5000;
BA_ "Version" SG_ 1227 DrvIMS_MemoryP3Req "17.11.00";
BA_ "Description" SG_ 1227 SmrtIMS_EnterSwSta "-(Old)C_SmartIMSOn";
BA_ "GenSigSendType" SG_ 1227 SmrtIMS_EnterSwSta 4;
BA_ "UserSigValidity" SG_ 1227 SmrtIMS_EnterSwSta 0;
BA_REL_ "GenSigTimeoutTime" BU_SG_REL_ CGW_CCU SG_ 1227 SmrtIMS_EnterSwSta 0;
BA_ "NetworkRequest" SG_ 1227 SmrtIMS_EnterSwSta 0;
BA_ "NetworkRequestHoldingTime" SG_ 1227 SmrtIMS_EnterSwSta 5000;
BA_ "Version" SG_ 1227 SmrtIMS_EnterSwSta "17.11.00";
BA_ "Description" SG_ 1227 DrvIMS_BzrReq "IMS ºÎÁ®À½À» Å¬·¯½ºÅÍ ½ºÇÇÄ¿¿¡¼­ Ãâ·ÂÇÏ±â À§ÇÑ ½Ã±×³Î";
BA_ "GenSigSendType" SG_ 1227 DrvIMS_BzrReq 4;
BA_ "UserSigValidity" SG_ 1227 DrvIMS_BzrReq 0;
BA_REL_ "GenSigTimeoutTime" BU_SG_REL_ CGW_CCU SG_ 1227 DrvIMS_BzrReq 0;
BA_ "NetworkRequest" SG_ 1227 DrvIMS_BzrReq 0;
BA_ "NetworkRequestHoldingTime" SG_ 1227 DrvIMS_BzrReq 5000;
BA_ "Version" SG_ 1227 DrvIMS_BzrReq "17.11.00";
BA_ "Description" SG_ 1227 DrvIMS_ErrConWmgDis "IMS ±â¾ï/Àç»ý Á¶°Ç ¿¡·¯ Ãâ·Â ½Ã±×³Î";
BA_ "GenSigSendType" SG_ 1227 DrvIMS_ErrConWmgDis 4;
BA_ "UserSigValidity" SG_ 1227 DrvIMS_ErrConWmgDis 0;
BA_REL_ "GenSigTimeoutTime" BU_SG_REL_ CGW_CCU SG_ 1227 DrvIMS_ErrConWmgDis 0;
BA_ "NetworkRequest" SG_ 1227 DrvIMS_ErrConWmgDis 0;
BA_ "NetworkRequestHoldingTime" SG_ 1227 DrvIMS_ErrConWmgDis 5000;
BA_ "Version" SG_ 1227 DrvIMS_ErrConWmgDis "18.07.01";
BA_ "Description" SG_ 1227 PSM_DrvRlxReturn_Req "one touch relax play and return";
BA_ "GenSigSendType" SG_ 1227 PSM_DrvRlxReturn_Req 4;
BA_ "UserSigValidity" SG_ 1227 PSM_DrvRlxReturn_Req 0;
BA_REL_ "GenSigTimeoutTime" BU_SG_REL_ CGW_CCU SG_ 1227 PSM_DrvRlxReturn_Req 0;
BA_ "NetworkRequest" SG_ 1227 PSM_DrvRlxReturn_Req 0;
BA_ "NetworkRequestHoldingTime" SG_ 1227 PSM_DrvRlxReturn_Req 5000;
BA_ "Version" SG_ 1227 PSM_DrvRlxReturn_Req "20.07.02";
BA_ "GenSigSendType" SG_ 1227 Drv_AutoRlxWrngDis 4;
BA_ "UserSigValidity" SG_ 1227 Drv_AutoRlxWrngDis 1;
BA_REL_ "GenSigTimeoutTime" BU_SG_REL_ CGW_CCU SG_ 1227 Drv_AutoRlxWrngDis 0;
BA_ "NetworkRequest" SG_ 1227 Drv_AutoRlxWrngDis 0;
BA_ "NetworkRequestHoldingTime" SG_ 1227 Drv_AutoRlxWrngDis 5000;
BA_ "Version" SG_ 1227 Drv_AutoRlxWrngDis "21.06.10";
BA_ "Description" SG_ 1227 DrvIMS_AMPBzrReq "SEAT IMS Buzzer Request for AMP";
BA_ "GenSigSendType" SG_ 1227 DrvIMS_AMPBzrReq 4;
BA_ "UserSigValidity" SG_ 1227 DrvIMS_AMPBzrReq 0;
BA_REL_ "GenSigTimeoutTime" BU_SG_REL_ CGW_CCU SG_ 1227 DrvIMS_AMPBzrReq 0;
BA_ "NetworkRequest" SG_ 1227 DrvIMS_AMPBzrReq 0;
BA_ "NetworkRequestHoldingTime" SG_ 1227 DrvIMS_AMPBzrReq 5000;
BA_ "Version" SG_ 1227 DrvIMS_AMPBzrReq "22.12.04";
BA_ "GenSigSendType" SG_ 1227 Drv_AutoRlxWrngDis_2 4;
BA_ "UserSigValidity" SG_ 1227 Drv_AutoRlxWrngDis_2 1;
BA_REL_ "GenSigTimeoutTime" BU_SG_REL_ CGW_CCU SG_ 1227 Drv_AutoRlxWrngDis_2 0;
BA_ "NetworkRequest" SG_ 1227 Drv_AutoRlxWrngDis_2 0;
BA_ "NetworkRequestHoldingTime" SG_ 1227 Drv_AutoRlxWrngDis_2 5000;
BA_ "Version" SG_ 1227 Drv_AutoRlxWrngDis_2 "22.11.03";
BA_ "Description" SG_ 1227 Drv_2ndStStdPosMovReq "2nd Seat Position Move Request Signal for 1st Drv Auto Relax Function";
BA_ "GenSigSendType" SG_ 1227 Drv_2ndStStdPosMovReq 4;
BA_ "UserSigValidity" SG_ 1227 Drv_2ndStStdPosMovReq 0;
BA_REL_ "GenSigTimeoutTime" BU_SG_REL_ GW_RLPSU SG_ 1227 Drv_2ndStStdPosMovReq 0;
BA_REL_ "GenSigTimeoutTime" BU_SG_REL_ GW_RRPSU SG_ 1227 Drv_2ndStStdPosMovReq 0;
BA_ "NetworkRequest" SG_ 1227 Drv_2ndStStdPosMovReq 0;
BA_ "NetworkRequestHoldingTime" SG_ 1227 Drv_2ndStStdPosMovReq 5000;
BA_ "Version" SG_ 1227 Drv_2ndStStdPosMovReq "22.11.13";
BA_ "Description" SG_ 1227 DrvIMS_MemorySetEnaSta "-(Old)C_MEMENB";
BA_ "GenSigSendType" SG_ 1227 DrvIMS_MemorySetEnaSta 4;
BA_ "UserSigValidity" SG_ 1227 DrvIMS_MemorySetEnaSta 0;
BA_REL_ "GenSigTimeoutTime" BU_SG_REL_ CGW_CCU SG_ 1227 DrvIMS_MemorySetEnaSta 0;
BA_ "NetworkRequest" SG_ 1227 DrvIMS_MemorySetEnaSta 0;
BA_ "NetworkRequestHoldingTime" SG_ 1227 DrvIMS_MemorySetEnaSta 5000;
BA_ "Version" SG_ 1227 DrvIMS_MemorySetEnaSta "17.11.00";
BA_ "GenSigSendType" SG_ 1227 DrvIMS_PlyBckP1Req 4;
BA_ "UserSigValidity" SG_ 1227 DrvIMS_PlyBckP1Req 0;
BA_REL_ "GenSigTimeoutTime" BU_SG_REL_ CGW_CCU SG_ 1227 DrvIMS_PlyBckP1Req 0;
BA_ "NetworkRequest" SG_ 1227 DrvIMS_PlyBckP1Req 0;
BA_ "NetworkRequestHoldingTime" SG_ 1227 DrvIMS_PlyBckP1Req 5000;
BA_ "Version" SG_ 1227 DrvIMS_PlyBckP1Req "17.11.00";
BA_ "GenMsgCycleTime" BO_ 1252 0;
BA_ "Description" SG_ 1252 RKE_Crc1Val "The data area for CRC calculation is based on the data length (DLC) of the message DB.

The CRC shall be calculated over the entire data block (excluding the CRC bytes) including the user data, alive counter and Data ID 

 

- CRC Polynomial (0x1D) , Initial Value : 0x00, XOR value : 0xFF, Data ID Mode : Both, Data ID : Message ID + 0xF800 

- The initial value is for CRC calculation and the message should be sent with the calculated result value. 

The mathematical expression to 8 bit CRC polynomial is given here. G(x) = x8 + x4 + x3 + x2 + 1";
BA_ "GenSigSendType" SG_ 1252 RKE_Crc1Val 4;
BA_ "UserSigValidity" SG_ 1252 RKE_Crc1Val 0;
BA_ "Version" SG_ 1252 RKE_Crc1Val "21.09.03";
BA_ "Description" SG_ 1252 RKE_AlvCnt1Val "For the first transmission request for a data element the counter shall be initialized with 0 and shall be incremented by 1

for every subsequent send request. When the counter reaches the maximum value(0xE), then it shall restart with 0 for the next send request";
BA_ "GenSigSendType" SG_ 1252 RKE_AlvCnt1Val 4;
BA_ "UserSigValidity" SG_ 1252 RKE_AlvCnt1Val 0;
BA_ "Version" SG_ 1252 RKE_AlvCnt1Val "21.09.03";
BA_ "Description" SG_ 1252 RKE_BtnReq "Remote Key Button Request from Folding Key or Smart Key";
BA_ "GenSigSendType" SG_ 1252 RKE_BtnReq 4;
BA_ "UserSigValidity" SG_ 1252 RKE_BtnReq 0;
BA_REL_ "GenSigTimeoutTime" BU_SG_REL_ ATS SG_ 1252 RKE_BtnReq 0;
BA_ "NetworkRequest" SG_ 1252 RKE_BtnReq 0;
BA_ "NetworkRequestHoldingTime" SG_ 1252 RKE_BtnReq 5000;
BA_ "Version" SG_ 1252 RKE_BtnReq "20.12.00";
BA_ "Description" SG_ 1252 RKE_PsdBtnReq "Remote Key Power Sliding Door Button Request from Folding Key or Smart Key";
BA_ "GenSigSendType" SG_ 1252 RKE_PsdBtnReq 4;
BA_ "UserSigValidity" SG_ 1252 RKE_PsdBtnReq 0;
BA_ "NetworkRequest" SG_ 1252 RKE_PsdBtnReq 0;
BA_ "NetworkRequestHoldingTime" SG_ 1252 RKE_PsdBtnReq 5000;
BA_ "Version" SG_ 1252 RKE_PsdBtnReq "17.12.00";
BA_ "Description" SG_ 1252 RKE_WdwUpDnReq "Remote Key Window Up and Down Request from Folding Key or Smart Key";
BA_ "GenSigSendType" SG_ 1252 RKE_WdwUpDnReq 4;
BA_ "UserSigValidity" SG_ 1252 RKE_WdwUpDnReq 0;
BA_REL_ "GenSigTimeoutTime" BU_SG_REL_ RCM SG_ 1252 RKE_WdwUpDnReq 0;
BA_ "NetworkRequest" SG_ 1252 RKE_WdwUpDnReq 0;
BA_ "NetworkRequestHoldingTime" SG_ 1252 RKE_WdwUpDnReq 5000;
BA_ "Version" SG_ 1252 RKE_WdwUpDnReq "17.12.00";
BA_ "Description" SG_ 1252 RKE_TrnkTlgtBtnReq "This signal for Tailgate or Trunk open CMD

While RKE Tailgate(Trunk) Button push, This Signal Tx On

While Tailgate(Trunk) Button released, This Signal Tx Off";
BA_ "GenSigSendType" SG_ 1252 RKE_TrnkTlgtBtnReq 4;
BA_ "UserSigValidity" SG_ 1252 RKE_TrnkTlgtBtnReq 0;
BA_ "NetworkRequest" SG_ 1252 RKE_TrnkTlgtBtnReq 0;
BA_ "NetworkRequestHoldingTime" SG_ 1252 RKE_TrnkTlgtBtnReq 5000;
BA_ "Version" SG_ 1252 RKE_TrnkTlgtBtnReq "18.07.01";
BA_ "Description" SG_ 1252 RKE_ID "Remote Key Window Up and Down Request from Folding Key or Smart Key



Folding key or smart key ID for recently received RF frame";
BA_ "GenSigSendType" SG_ 1252 RKE_ID 4;
BA_ "UserSigValidity" SG_ 1252 RKE_ID 0;
BA_ "Version" SG_ 1252 RKE_ID "17.12.00";
BA_ "Description" SG_ 1252 RKE_PwrDrAllOpnClsReq "Remote Key Button Signal for PSD and PTG opening or closing together";
BA_ "GenSigSendType" SG_ 1252 RKE_PwrDrAllOpnClsReq 4;
BA_ "UserSigValidity" SG_ 1252 RKE_PwrDrAllOpnClsReq 0;
BA_ "NetworkRequest" SG_ 1252 RKE_PwrDrAllOpnClsReq 0;
BA_ "NetworkRequestHoldingTime" SG_ 1252 RKE_PwrDrAllOpnClsReq 5000;
BA_ "Version" SG_ 1252 RKE_PwrDrAllOpnClsReq "19.04.04";
BA_ "Description" SG_ 1252 RKE_FrnkBtnReq "Frunk Button RKE Signal for Smart Key or Foding Key";
BA_ "GenSigSendType" SG_ 1252 RKE_FrnkBtnReq 4;
BA_ "UserSigValidity" SG_ 1252 RKE_FrnkBtnReq 0;
BA_ "NetworkRequest" SG_ 1252 RKE_FrnkBtnReq 0;
BA_ "NetworkRequestHoldingTime" SG_ 1252 RKE_FrnkBtnReq 5000;
BA_ "Version" SG_ 1252 RKE_FrnkBtnReq "24.01.03";
BA_ "GenMsgCycleTime" BO_ 1253 0;
BA_ "Description" SG_ 1253 SMK_Crc1Val "The data area for CRC calculation is based on the data length (DLC) of the message DB.

The CRC shall be calculated over the entire data block (excluding the CRC bytes) including the user data, alive counter and Data ID 

 

- CRC Polynomial (0x1D) , Initial Value : 0x00, XOR value : 0xFF, Data ID Mode : Both, Data ID : Message ID + 0xF800 

- The initial value is for CRC calculation and the message should be sent with the calculated result value. 

The mathematical expression to 8 bit CRC polynomial is given here. G(x) = x8 + x4 + x3 + x2 + 1";
BA_ "GenSigSendType" SG_ 1253 SMK_Crc1Val 4;
BA_ "UserSigValidity" SG_ 1253 SMK_Crc1Val 0;
BA_ "Version" SG_ 1253 SMK_Crc1Val "21.09.03";
BA_ "Description" SG_ 1253 SMK_AlvCnt1Val "For the first transmission request for a data element the counter shall be initialized with 0 and shall be incremented by 1

for every subsequent send request. When the counter reaches the maximum value(0xE), then it shall restart with 0 for the next send request";
BA_ "GenSigSendType" SG_ 1253 SMK_AlvCnt1Val 4;
BA_ "UserSigValidity" SG_ 1253 SMK_AlvCnt1Val 0;
BA_ "Version" SG_ 1253 SMK_AlvCnt1Val "21.09.03";
BA_ "GenSigSendType" SG_ 1253 DoorLock_PsvDrLkReq 4;
BA_ "UserSigValidity" SG_ 1253 DoorLock_PsvDrLkReq 0;
BA_ "Version" SG_ 1253 DoorLock_PsvDrLkReq "17.12.00";
BA_ "GenSigSendType" SG_ 1253 DoorLock_PsvDrUnLkReq 4;
BA_ "UserSigValidity" SG_ 1253 DoorLock_PsvDrUnLkReq 0;
BA_ "Version" SG_ 1253 DoorLock_PsvDrUnLkReq "17.12.00";
BA_ "Description" SG_ 1253 DoorLock_DrvDrPsvAcsReq "-(Old)C_P_FL";
BA_ "GenSigSendType" SG_ 1253 DoorLock_DrvDrPsvAcsReq 4;
BA_ "UserSigValidity" SG_ 1253 DoorLock_DrvDrPsvAcsReq 0;
BA_ "Version" SG_ 1253 DoorLock_DrvDrPsvAcsReq "17.12.00";
BA_ "Description" SG_ 1253 DoorLock_AsstDrPsvAcsReq "-(Old)C_P_FR";
BA_ "GenSigSendType" SG_ 1253 DoorLock_AsstDrPsvAcsReq 4;
BA_ "UserSigValidity" SG_ 1253 DoorLock_AsstDrPsvAcsReq 0;
BA_ "Version" SG_ 1253 DoorLock_AsstDrPsvAcsReq "17.12.00";
BA_ "Description" SG_ 1253 DoorLock_TrnkTlgtPsvAcsReq "-(Old)C_PassiveTrunk_TG";
BA_ "GenSigSendType" SG_ 1253 DoorLock_TrnkTlgtPsvAcsReq 4;
BA_ "UserSigValidity" SG_ 1253 DoorLock_TrnkTlgtPsvAcsReq 0;
BA_ "Version" SG_ 1253 DoorLock_TrnkTlgtPsvAcsReq "17.12.00";
BA_ "Description" SG_ 1253 DoorLock_RrLftDrPsvAcsReq "-(Old)C_P_RL";
BA_ "GenSigSendType" SG_ 1253 DoorLock_RrLftDrPsvAcsReq 4;
BA_ "UserSigValidity" SG_ 1253 DoorLock_RrLftDrPsvAcsReq 0;
BA_ "Version" SG_ 1253 DoorLock_RrLftDrPsvAcsReq "17.12.00";
BA_ "Description" SG_ 1253 DoorLock_RrRtDrPsvAcsReq "-(Old)C_P_RR";
BA_ "GenSigSendType" SG_ 1253 DoorLock_RrRtDrPsvAcsReq 4;
BA_ "UserSigValidity" SG_ 1253 DoorLock_RrRtDrPsvAcsReq 0;
BA_ "Version" SG_ 1253 DoorLock_RrRtDrPsvAcsReq "17.12.00";
BA_ "Description" SG_ 1253 DoorLock_PsdPsvAcsReq "-Fob Asnswer for each LH/RH PSD LF searching";
BA_ "GenSigSendType" SG_ 1253 DoorLock_PsdPsvAcsReq 4;
BA_ "UserSigValidity" SG_ 1253 DoorLock_PsdPsvAcsReq 0;
BA_ "Version" SG_ 1253 DoorLock_PsdPsvAcsReq "17.12.00";
BA_ "Description" SG_ 1253 Auth_Req "Request IAU(NFC / Fingerprint) authentication

##2G##SMK-SMKmsg03-C_SMK_AuthReq";
BA_ "GenSigSendType" SG_ 1253 Auth_Req 4;
BA_ "UserSigValidity" SG_ 1253 Auth_Req 0;
BA_ "NetworkRequest" SG_ 1253 Auth_Req 0;
BA_ "NetworkRequestHoldingTime" SG_ 1253 Auth_Req 5000;
BA_ "Version" SG_ 1253 Auth_Req "20.11.00";
BA_ "Description" SG_ 1253 RSPA_DigitalKeyAuth "Authenticaion by Digital key in RSPA mode";
BA_ "GenSigSendType" SG_ 1253 RSPA_DigitalKeyAuth 4;
BA_ "UserSigValidity" SG_ 1253 RSPA_DigitalKeyAuth 0;
BA_ "Version" SG_ 1253 RSPA_DigitalKeyAuth "19.07.02";
BA_ "Description" SG_ 1253 Auth_Method "This signal is for a send Authentication result and authentication method.

- Fob, TP, Fingerprint, NFC(Digital Key, Card Key), BLE, Face Recognition, Digital key Passive";
BA_ "GenSigSendType" SG_ 1253 Auth_Method 4;
BA_ "UserSigValidity" SG_ 1253 Auth_Method 0;
BA_REL_ "GenSigTimeoutTime" BU_SG_REL_ GW_DPSU SG_ 1253 Auth_Method 0;
BA_ "NetworkRequest" SG_ 1253 Auth_Method 0;
BA_ "NetworkRequestHoldingTime" SG_ 1253 Auth_Method 5000;
BA_ "Version" SG_ 1253 Auth_Method "20.03.07";
BA_ "GenSigSendType" SG_ 1253 DoorLock_StrgbxPsvAcsReq 4;
BA_ "UserSigValidity" SG_ 1253 DoorLock_StrgbxPsvAcsReq 0;
BA_ "Version" SG_ 1253 DoorLock_StrgbxPsvAcsReq "20.07.05";
BA_ "Description" SG_ 1253 Auth_ISKLearnFdbck "This signal is Learning Feedback";
BA_ "GenSigSendType" SG_ 1253 Auth_ISKLearnFdbck 4;
BA_ "UserSigValidity" SG_ 1253 Auth_ISKLearnFdbck 0;
BA_ "NetworkRequest" SG_ 1253 Auth_ISKLearnFdbck 0;
BA_ "NetworkRequestHoldingTime" SG_ 1253 Auth_ISKLearnFdbck 5000;
BA_ "Version" SG_ 1253 Auth_ISKLearnFdbck "19.01.02";
BA_ "Description" SG_ 1253 DoorLock_FrnkWrngOpnReq "This signal is SMK Frunk Warning Open request";
BA_ "GenSigSendType" SG_ 1253 DoorLock_FrnkWrngOpnReq 4;
BA_ "UserSigValidity" SG_ 1253 DoorLock_FrnkWrngOpnReq 0;
BA_ "Version" SG_ 1253 DoorLock_FrnkWrngOpnReq "21.09.07";
BA_ "Description" SG_ 1253 DoorLock_SmrtPsdPsvAcsReq "Smart Sliding Door Open Command";
BA_ "GenSigSendType" SG_ 1253 DoorLock_SmrtPsdPsvAcsReq 4;
BA_ "UserSigValidity" SG_ 1253 DoorLock_SmrtPsdPsvAcsReq 0;
BA_ "Version" SG_ 1253 DoorLock_SmrtPsdPsvAcsReq "19.01.10";
BA_ "Description" SG_ 1253 Auth_Event "This signal is for a send Authentication event";
BA_ "GenSigSendType" SG_ 1253 Auth_Event 4;
BA_ "UserSigValidity" SG_ 1253 Auth_Event 0;
BA_REL_ "GenSigTimeoutTime" BU_SG_REL_ GW_DPSU SG_ 1253 Auth_Event 0;
BA_ "NetworkRequest" SG_ 1253 Auth_Event 0;
BA_ "NetworkRequestHoldingTime" SG_ 1253 Auth_Event 5000;
BA_ "Version" SG_ 1253 Auth_Event "20.03.07";
BA_ "GenMsgCycleTime" BO_ 1237 0;
BA_ "Description" SG_ 1237 SWRC_Crc2Val "The data area for CRC calculation is based on the data length (DLC) of the message DB.

The CRC shall be calculated over the entire data block (excluding the CRC bytes) including the user data, alive counter and Data ID 

 

- CRC Polynomial (0x1D) , Initial Value : 0x00, XOR value : 0xFF, Data ID Mode : Both, Data ID : Message ID + 0xF800 

- The initial value is for CRC calculation and the message should be sent with the calculated result value. 

The mathematical expression to 8 bit CRC polynomial is given here. G(x) = x8 + x4 + x3 + x2 + 1";
BA_ "GenSigSendType" SG_ 1237 SWRC_Crc2Val 4;
BA_ "UserSigValidity" SG_ 1237 SWRC_Crc2Val 0;
BA_ "Version" SG_ 1237 SWRC_Crc2Val "21.09.03";
BA_ "Description" SG_ 1237 SWRC_AlvCnt2Val "For the first transmission request for a data element the counter shall be initialized with 0 and shall be incremented by 1

for every subsequent send request. When the counter reaches the maximum value(0xE), then it shall restart with 0 for the next send request";
BA_ "GenSigSendType" SG_ 1237 SWRC_AlvCnt2Val 4;
BA_ "UserSigValidity" SG_ 1237 SWRC_AlvCnt2Val 0;
BA_ "Version" SG_ 1237 SWRC_AlvCnt2Val "21.09.03";
BA_ "Description" SG_ 1237 Audio_VolEncoderSta "Audio Volume switch

MM-CAN Gateway needed";
BA_ "GenSigSendType" SG_ 1237 Audio_VolEncoderSta 4;
BA_ "UserSigValidity" SG_ 1237 Audio_VolEncoderSta 0;
BA_REL_ "GenSigTimeoutTime" BU_SG_REL_ CGW_CCU SG_ 1237 Audio_VolEncoderSta 0;
BA_ "NetworkRequest" SG_ 1237 Audio_VolEncoderSta 0;
BA_ "NetworkRequestHoldingTime" SG_ 1237 Audio_VolEncoderSta 5000;
BA_ "Version" SG_ 1237 Audio_VolEncoderSta "19.11.02";
BA_ "Description" SG_ 1237 Cluster_ScrlEncoderSta "Cluster Trip Switch";
BA_ "GenSigSendType" SG_ 1237 Cluster_ScrlEncoderSta 4;
BA_ "UserSigValidity" SG_ 1237 Cluster_ScrlEncoderSta 0;
BA_REL_ "GenSigTimeoutTime" BU_SG_REL_ CGW_CCU SG_ 1237 Cluster_ScrlEncoderSta 0;
BA_ "NetworkRequest" SG_ 1237 Cluster_ScrlEncoderSta 0;
BA_ "NetworkRequestHoldingTime" SG_ 1237 Cluster_ScrlEncoderSta 5000;
BA_ "Version" SG_ 1237 Cluster_ScrlEncoderSta "19.11.02";
BA_ "GenMsgSendType" BO_ 139 0;
BA_ "Description" SG_ 139 SWRC_Crc5Val "The data area for CRC calculation is based on the data length (DLC) of the message DB.

The CRC shall be calculated over the entire data block (excluding the CRC bytes) including the user data, alive counter and Data ID 

 

- CRC Polynomial (0x1D) , Initial Value : 0x00, XOR value : 0xFF, Data ID Mode : Both, Data ID : Message ID + 0xF800 

- The initial value is for CRC calculation and the message should be sent with the calculated result value. 

The mathematical expression to 8 bit CRC polynomial is given here. G(x) = x8 + x4 + x3 + x2 + 1";
BA_ "GenSigSendType" SG_ 139 SWRC_Crc5Val 4;
BA_ "UserSigValidity" SG_ 139 SWRC_Crc5Val 0;
BA_REL_ "GenSigTimeoutTime" BU_SG_REL_ CGW_CCU SG_ 139 SWRC_Crc5Val 1500;
BA_ "Version" SG_ 139 SWRC_Crc5Val "22.05.03";
BA_ "Description" SG_ 139 SWRC_AlvCnt5Val "For the first transmission request for a data element the counter shall be initialized with 0 and shall be incremented by 1

for every subsequent send request. When the counter reaches the maximum value(0xE), then it shall restart with 0 for the next send request";
BA_ "GenSigSendType" SG_ 139 SWRC_AlvCnt5Val 4;
BA_ "UserSigValidity" SG_ 139 SWRC_AlvCnt5Val 0;
BA_REL_ "GenSigTimeoutTime" BU_SG_REL_ CGW_CCU SG_ 139 SWRC_AlvCnt5Val 1500;
BA_ "Version" SG_ 139 SWRC_AlvCnt5Val "22.05.03";
BA_ "Description" SG_ 139 SWRC_DriveModCWSwSta "Drive Mode Switch Status Clockwise(right)";
BA_ "GenSigSendType" SG_ 139 SWRC_DriveModCWSwSta 4;
BA_ "UserSigValidity" SG_ 139 SWRC_DriveModCWSwSta 0;
BA_REL_ "GenSigTimeoutTime" BU_SG_REL_ CGW_CCU SG_ 139 SWRC_DriveModCWSwSta 1500;
BA_ "NetworkRequest" SG_ 139 SWRC_DriveModCWSwSta 0;
BA_ "NetworkRequestHoldingTime" SG_ 139 SWRC_DriveModCWSwSta 5000;
BA_ "Version" SG_ 139 SWRC_DriveModCWSwSta "20.01.01";
BA_ "Description" SG_ 139 SWRC_DriveModCCWSwSta "Drive Mode Switch Status CounterClockWise (Left)";
BA_ "GenSigSendType" SG_ 139 SWRC_DriveModCCWSwSta 4;
BA_ "UserSigValidity" SG_ 139 SWRC_DriveModCCWSwSta 0;
BA_REL_ "GenSigTimeoutTime" BU_SG_REL_ CGW_CCU SG_ 139 SWRC_DriveModCCWSwSta 1500;
BA_ "NetworkRequest" SG_ 139 SWRC_DriveModCCWSwSta 0;
BA_ "NetworkRequestHoldingTime" SG_ 139 SWRC_DriveModCCWSwSta 5000;
BA_ "Version" SG_ 139 SWRC_DriveModCCWSwSta "20.01.01";
BA_ "Description" SG_ 139 SWRC_BoostSwSta "Boost Switch Status";
BA_ "GenSigSendType" SG_ 139 SWRC_BoostSwSta 4;
BA_ "UserSigValidity" SG_ 139 SWRC_BoostSwSta 0;
BA_REL_ "GenSigTimeoutTime" BU_SG_REL_ CGW_CCU SG_ 139 SWRC_BoostSwSta 1500;
BA_ "NetworkRequest" SG_ 139 SWRC_BoostSwSta 0;
BA_ "NetworkRequestHoldingTime" SG_ 139 SWRC_BoostSwSta 5000;
BA_ "Version" SG_ 139 SWRC_BoostSwSta "19.12.08";
BA_ "Description" SG_ 139 SWRC_DriveModeSwSta "Drive Mode Switch Status (Push Type)";
BA_ "GenSigSendType" SG_ 139 SWRC_DriveModeSwSta 4;
BA_ "UserSigValidity" SG_ 139 SWRC_DriveModeSwSta 0;
BA_REL_ "GenSigTimeoutTime" BU_SG_REL_ CGW_CCU SG_ 139 SWRC_DriveModeSwSta 1500;
BA_ "Version" SG_ 139 SWRC_DriveModeSwSta "20.03.05";
BA_ "Description" SG_ 139 SWRC_TerrainModeSwSta "Terrain Mode Switch Status (Push Type)";
BA_ "GenSigSendType" SG_ 139 SWRC_TerrainModeSwSta 4;
BA_ "UserSigValidity" SG_ 139 SWRC_TerrainModeSwSta 0;
BA_REL_ "GenSigTimeoutTime" BU_SG_REL_ CGW_CCU SG_ 139 SWRC_TerrainModeSwSta 1500;
BA_ "Version" SG_ 139 SWRC_TerrainModeSwSta "21.09.02";
BA_ "Description" SG_ 139 SWRC_N1SwSta "N Vehicle SWRC N1 Switch signal";
BA_ "GenSigSendType" SG_ 139 SWRC_N1SwSta 4;
BA_ "UserSigValidity" SG_ 139 SWRC_N1SwSta 0;
BA_REL_ "GenSigTimeoutTime" BU_SG_REL_ CGW_CCU SG_ 139 SWRC_N1SwSta 1500;
BA_ "NetworkRequest" SG_ 139 SWRC_N1SwSta 0;
BA_ "NetworkRequestHoldingTime" SG_ 139 SWRC_N1SwSta 5000;
BA_ "Version" SG_ 139 SWRC_N1SwSta "21.11.06";
BA_ "Description" SG_ 139 SWRC_N2SwSta "N Vehicle SWRC N2 Switch signal";
BA_ "GenSigSendType" SG_ 139 SWRC_N2SwSta 4;
BA_ "UserSigValidity" SG_ 139 SWRC_N2SwSta 0;
BA_REL_ "GenSigTimeoutTime" BU_SG_REL_ CGW_CCU SG_ 139 SWRC_N2SwSta 1500;
BA_ "NetworkRequest" SG_ 139 SWRC_N2SwSta 0;
BA_ "NetworkRequestHoldingTime" SG_ 139 SWRC_N2SwSta 5000;
BA_ "Version" SG_ 139 SWRC_N2SwSta "21.11.06";
BA_ "Description" SG_ 139 SWRC_4wdLocking "4wd locking on/off signal";
BA_ "GenSigSendType" SG_ 139 SWRC_4wdLocking 4;
BA_ "UserSigValidity" SG_ 139 SWRC_4wdLocking 0;
BA_REL_ "GenSigTimeoutTime" BU_SG_REL_ CGW_CCU SG_ 139 SWRC_4wdLocking 1500;
BA_ "Version" SG_ 139 SWRC_4wdLocking "22.07.06";
BA_ "Description" SG_ 139 SWRC_GTSWSta "GT Switch Status (Push Type)";
BA_ "GenSigSendType" SG_ 139 SWRC_GTSWSta 4;
BA_ "UserSigValidity" SG_ 139 SWRC_GTSWSta 0;
BA_REL_ "GenSigTimeoutTime" BU_SG_REL_ CGW_CCU SG_ 139 SWRC_GTSWSta 1500;
BA_ "Version" SG_ 139 SWRC_GTSWSta "23.08.00";
VAL_ 140 ATS_DATC_FrPsModeSet 0 "Reserved" 1 "Vent" 2 "BL" 3 "Floor" 4 "Reserved" 5 "Reserved" 6 "Reserved" 7 "Reserved" 8 "Reserved" 9 "Reserved" 10 "Reserved" 11 "Reserved" 12 "Reserved" 13 "Reserved" 14 "Reserved" 15 "Invalid" ;
VAL_ 140 ATS_DATC_FrPsAutoSet 0 "reserved" 1 "AUTO ON" 2 "reserved" 3 "Invalid" ;
VAL_ 140 ATS_DATC_FrPsBlowerSet 0 "DATC Off" 1 "0 level (Do not use)" 2 "1 level" 3 "2 level" 4 "3 level" 5 "4 level" 6 "5 level" 7 "6 level" 8 "7 level" 9 "8 level" 15 "Invalid" ;
VAL_ 140 ATS_DATC_FrPsBlowerUpDn 0 "Reserved" 1 "Up" 2 "Down" 3 "Invalid" ;
VAL_ 140 ATS_DATC_FrDrMultiAutoBlower 0 "Reserved" 1 "Low" 2 "Medium" 3 "High" 4 "Reserved" 5 "Reserved" 6 "Reserved" 7 "Invalid" ;
VAL_ 140 ATS_DATC_FrPsMultiAutoBlower 0 "Reserved" 1 "Low" 2 "Medium" 3 "High" 4 "Reserved" 5 "Reserved" 6 "Reserved" 7 "Invalid" ;
VAL_ 140 ATS_DATC_RrDrMultiAutoBlower 0 "Reserved" 1 "Low" 2 "Medium" 3 "High" 4 "Reserved" 5 "Reserved" 6 "Reserved" 7 "Invalid" ;
VAL_ 140 ATS_DATC_FragranceStrhSet 0 "Default" 1 "Off" 2 "Low" 3 "Medium" 4 "High" 5 "Reserved" 6 "Reserved" 7 "Invalid" ;
VAL_ 140 ATS_DATC_FragranceKindSet 0 "Default" 1 "First" 2 "Second" 3 "Reserved" 4 "Reserved" 5 "Reserved" 6 "Reserved" 7 "Invalid" ;
VAL_ 140 ATS_DATC_FragranceBttnMnlSet 0 "Default" 1 "Off" 2 "On" 3 "Invalid" ;
VAL_ 140 ATS_DATC_TempUnitSet 0 "Off" 1 "¢ªC (Centigrade)" 2 "¢ªF (Fahrenheit)" 3 "Invalid" ;
VAL_ 158 ATS_DATC_FrDrBlowerSet 0 "DATC Off" 1 "0 level (Do not use)" 2 "1 level" 3 "2 level" 4 "3level" 5 "4 level" 6 "5 level" 7 "6 level" 8 "7 level" 9 "8 level" 15 "Invalid" ;
VAL_ 158 ATS_DATC_RrDrTempUpDn 0 "Reserved" 1 "Temp Up" 2 "Temp Down" 3 "Invalid" ;
VAL_ 158 ATS_DATC_RrDrBlowerSet 0 "Off" 1 "0 level" 2 "1 level" 3 "2 level" 4 "3 level" 5 "4 level" 6 "5 level" 7 "6 level" 8 "7 level" 9 "8 level" 14 "reserved" 15 "Invalid" ;
VAL_ 158 ATS_DATC_RrDrModeSet 0 "Off" 1 "VENT" 2 "BL" 3 "FLOOR" 12 "reserved" 13 "reserved" 14 "reserved" 15 "Invalid" ;
VAL_ 158 ATS_DATC_FrDrModeSet 0 "Reserved" 1 "VENT" 2 "BL" 3 "FLOOR" 4 "MIX" 5 "reserved" 6 "reserved" 7 "7 Mode DEF VENT" 8 "reserved" 9 "MODE DEF VENT FLOOR" 10 "7 Mode DEF" 11 "Reserved" 12 "Reserved" 13 "Reserved" 14 "Reserved" 15 "Invalid" ;
VAL_ 158 ATS_DATC_RrOnOffSet 0 "Function Off" 1 "Function On" 2 "reserved" 3 "Invalid" ;
VAL_ 158 ATS_DATC_IntakeSet 0 "REC Off (Fresh On)" 1 "REC ON (Fresh Off)" 2 "reserved" 3 "Invalid" ;
VAL_ 158 ATS_DATC_OffReq 0 "Reserved" 1 "Request" 2 "reserved" 3 "Invalid" ;
VAL_ 158 ATS_DATC_FrDrAutoSet 0 "reserved" 1 "AUTO ON" 2 "reserved" 3 "Invalid" ;
VAL_ 158 ATS_DATC_FrPsTempUpDn 0 "Reserved" 1 "Temp Up" 2 "Temp Down" 3 "Invalid" ;
VAL_ 158 ATS_DATC_FrDefog 0 "Defog Off" 1 "Defog On" 2 "reserved" 3 "Invalid" ;
VAL_ 158 ATS_DATC_RrSyncSet 0 "Reserved" 1 "NOT SYNC" 2 "Rear SYNC" 3 "Invalid" ;
VAL_ 158 ATS_DATC_AcSet 0 "AC Off" 1 "AC ON" 2 "reserved" 3 "Invalid" ;
VAL_ 158 ATS_DATC_AirCleaningSet 0 "Air Cleaning System Off" 1 "Air Cleaning System On" 2 "Air Cleaning System Not Support" 3 "Invalid" ;
VAL_ 158 ATS_DATC_FrDrBlowerUpDn 0 "Reserved" 1 "Up" 2 "Down" 3 "Invalid" ;
VAL_ 158 ATS_DATC_FrDrTempUpDn 0 "Reserved" 1 "Temp Up" 2 "Temp Down" 3 "Invalid" ;
VAL_ 158 ATS_DATC_RrDrAutoSet 0 "Auto Off" 1 "Auto On" 2 "Not Used" 3 "Invalid" ;
VAL_ 157 ATS_DATC_FrDrTempSetC 0 "Blank" 1 "LO" 2 "PHY=HEX*0.5 + 14" 3 "PHY=HEX*0.5 + 14" 4 "PHY=HEX*0.5 + 14" 5 "PHY=HEX*0.5 + 14" 6 "PHY=HEX*0.5 + 14" 7 "PHY=HEX*0.5 + 14" 8 "PHY=HEX*0.5 + 14" 9 "PHY=HEX*0.5 + 14" 10 "PHY=HEX*0.5 + 14" 11 "PHY=HEX*0.5 + 14" 12 "PHY=HEX*0.5 + 14" 13 "PHY=HEX*0.5 + 14" 14 "PHY=HEX*0.5 + 14" 15 "PHY=HEX*0.5 + 14" 16 "PHY=HEX*0.5 + 14" 17 "PHY=HEX*0.5 + 14" 18 "PHY=HEX*0.5 + 14" 19 "PHY=HEX*0.5 + 14" 20 "PHY=HEX*0.5 + 14" 21 "PHY=HEX*0.5 + 14" 22 "PHY=HEX*0.5 + 14" 23 "PHY=HEX*0.5 + 14" 24 "PHY=HEX*0.5 + 14" 25 "PHY=HEX*0.5 + 14" 26 "PHY=HEX*0.5 + 14" 27 "PHY=HEX*0.5 + 14" 28 "PHY=HEX*0.5 + 14" 29 "PHY=HEX*0.5 + 14" 30 "PHY=HEX*0.5 + 14" 31 "PHY=HEX*0.5 + 14" 32 "PHY=HEX*0.5 + 14" 33 "PHY=HEX*0.5 + 14" 34 "PHY=HEX*0.5 + 14" 35 "PHY=HEX*0.5 + 14" 36 "PHY=HEX*0.5 + 14" 37 "0x25~0xFD:Reserved" 253 "0x25~0xFD:Reserved" 254 "HI" 255 "Invalid" ;
VAL_ 157 ATS_DATC_RrDrBlowerUpDn 0 "Reserved" 1 "Blower Up" 2 "Blower Down" 3 "Invalid" ;
VAL_ 157 ATS_DATC_FrSyncSet 0 "Reserved" 1 "NOT SYNC" 2 "SYNC" 3 "Invalid" ;
VAL_ 157 ATS_DATC_RrDrTempSetC 0 "Blank" 1 "LO" 2 "PHY=HEX*0.5 + 14" 3 "PHY=HEX*0.5 + 14" 4 "PHY=HEX*0.5 + 14" 5 "PHY=HEX*0.5 + 14" 6 "PHY=HEX*0.5 + 14" 7 "PHY=HEX*0.5 + 14" 8 "PHY=HEX*0.5 + 14" 9 "PHY=HEX*0.5 + 14" 10 "PHY=HEX*0.5 + 14" 11 "PHY=HEX*0.5 + 14" 12 "PHY=HEX*0.5 + 14" 13 "PHY=HEX*0.5 + 14" 14 "PHY=HEX*0.5 + 14" 15 "PHY=HEX*0.5 + 14" 16 "PHY=HEX*0.5 + 14" 17 "PHY=HEX*0.5 + 14" 18 "PHY=HEX*0.5 + 14" 19 "PHY=HEX*0.5 + 14" 20 "PHY=HEX*0.5 + 14" 21 "PHY=HEX*0.5 + 14" 22 "PHY=HEX*0.5 + 14" 23 "PHY=HEX*0.5 + 14" 24 "PHY=HEX*0.5 + 14" 25 "PHY=HEX*0.5 + 14" 26 "PHY=HEX*0.5 + 14" 27 "PHY=HEX*0.5 + 14" 28 "PHY=HEX*0.5 + 14" 29 "PHY=HEX*0.5 + 14" 30 "PHY=HEX*0.5 + 14" 31 "PHY=HEX*0.5 + 14" 32 "PHY=HEX*0.5 + 14" 33 "PHY=HEX*0.5 + 14" 34 "PHY=HEX*0.5 + 14" 35 "PHY=HEX*0.5 + 14" 36 "PHY=HEX*0.5 + 14" 37 "0x25~0xFC:Reserved" 252 "0x25~0xFC:Reserved" 254 "HI" 255 "Invalid" ;
VAL_ 157 ATS_DATC_RrDrTempSetF 0 "Blank" 1 "LO" 2 "PHY=HEX*1+56" 3 "PHY=HEX*1+56" 4 "PHY=HEX*1+56" 5 "PHY=HEX*1+56" 6 "PHY=HEX*1+56" 7 "PHY=HEX*1+56" 8 "PHY=HEX*1+56" 9 "PHY=HEX*1+56" 10 "PHY=HEX*1+56" 11 "PHY=HEX*1+56" 12 "PHY=HEX*1+56" 13 "PHY=HEX*1+56" 14 "PHY=HEX*1+56" 15 "PHY=HEX*1+56" 16 "PHY=HEX*1+56" 17 "PHY=HEX*1+56" 18 "PHY=HEX*1+56" 19 "PHY=HEX*1+56" 20 "PHY=HEX*1+56" 21 "PHY=HEX*1+56" 22 "PHY=HEX*1+56" 23 "PHY=HEX*1+56" 24 "PHY=HEX*1+56" 25 "PHY=HEX*1+56" 26 "PHY=HEX*1+56" 27 "PHY=HEX*1+56" 28 "PHY=HEX*1+56" 29 "PHY=HEX*1+56" 30 "PHY=HEX*1+56" 31 "PHY=HEX*1+56" 32 "PHY=HEX*1+56" 33 "PHY=HEX*1+56" 34 "PHY=HEX*1+56" 35 "PHY=HEX*1+56" 36 "PHY=HEX*1+56" 37 "0x25~0xFC:Reserved" 252 "0x25~0xFC:Reserved" 254 "HI" 255 "Invalid" ;
VAL_ 157 ATS_DATC_FrPsTempSetC 0 "Blank" 1 "LO" 2 "PHY=HEX*0.5 + 14" 3 "PHY=HEX*0.5 + 14" 4 "PHY=HEX*0.5 + 14" 5 "PHY=HEX*0.5 + 14" 6 "PHY=HEX*0.5 + 14" 7 "PHY=HEX*0.5 + 14" 8 "PHY=HEX*0.5 + 14" 9 "PHY=HEX*0.5 + 14" 10 "PHY=HEX*0.5 + 14" 11 "PHY=HEX*0.5 + 14" 12 "PHY=HEX*0.5 + 14" 13 "PHY=HEX*0.5 + 14" 14 "PHY=HEX*0.5 + 14" 15 "PHY=HEX*0.5 + 14" 16 "PHY=HEX*0.5 + 14" 17 "PHY=HEX*0.5 + 14" 18 "PHY=HEX*0.5 + 14" 19 "PHY=HEX*0.5 + 14" 20 "PHY=HEX*0.5 + 14" 21 "PHY=HEX*0.5 + 14" 22 "PHY=HEX*0.5 + 14" 23 "PHY=HEX*0.5 + 14" 24 "PHY=HEX*0.5 + 14" 25 "PHY=HEX*0.5 + 14" 26 "PHY=HEX*0.5 + 14" 27 "PHY=HEX*0.5 + 14" 28 "PHY=HEX*0.5 + 14" 29 "PHY=HEX*0.5 + 14" 30 "PHY=HEX*0.5 + 14" 31 "PHY=HEX*0.5 + 14" 32 "PHY=HEX*0.5 + 14" 33 "PHY=HEX*0.5 + 14" 34 "PHY=HEX*0.5 + 14" 35 "PHY=HEX*0.5 + 14" 36 "PHY=HEX*0.5 + 14" 37 "0x25~0xFD:Reserved" 253 "0x25~0xFD:Reserved" 254 "HI" 255 "Invalid" ;
VAL_ 157 ATS_DATC_FrPsTempSetF 0 "Blank" 1 "LO" 2 "PHY=HEX*1+56" 3 "PHY=HEX*1+56" 4 "PHY=HEX*1+56" 5 "PHY=HEX*1+56" 6 "PHY=HEX*1+56" 7 "PHY=HEX*1+56" 8 "PHY=HEX*1+56" 9 "PHY=HEX*1+56" 10 "PHY=HEX*1+56" 11 "PHY=HEX*1+56" 12 "PHY=HEX*1+56" 13 "PHY=HEX*1+56" 14 "PHY=HEX*1+56" 15 "PHY=HEX*1+56" 16 "PHY=HEX*1+56" 17 "PHY=HEX*1+56" 18 "PHY=HEX*1+56" 19 "PHY=HEX*1+56" 20 "PHY=HEX*1+56" 21 "PHY=HEX*1+56" 22 "PHY=HEX*1+56" 23 "PHY=HEX*1+56" 24 "PHY=HEX*1+56" 25 "PHY=HEX*1+56" 26 "PHY=HEX*1+56" 27 "PHY=HEX*1+56" 28 "PHY=HEX*1+56" 29 "PHY=HEX*1+56" 30 "PHY=HEX*1+56" 31 "PHY=HEX*1+56" 32 "PHY=HEX*1+56" 33 "PHY=HEX*1+56" 34 "PHY=HEX*1+56" 35 "PHY=HEX*1+56" 36 "PHY=HEX*1+56" 37 "0x25~0xFC:Reserved" 252 "0x25~0xFC:Reserved" 254 "HI" 255 "Invalid" ;
VAL_ 157 ATS_DATC_FrDrTempSetF 0 "Blank" 1 "LO" 2 "PHY=HEX*1 + 56" 3 "PHY=HEX*1 + 56" 4 "PHY=HEX*1 + 56" 5 "PHY=HEX*1 + 56" 6 "PHY=HEX*1 + 56" 7 "PHY=HEX*1 + 56" 8 "PHY=HEX*1 + 56" 9 "PHY=HEX*1 + 56" 10 "PHY=HEX*1 + 56" 11 "PHY=HEX*1 + 56" 12 "PHY=HEX*1 + 56" 13 "PHY=HEX*1 + 56" 14 "PHY=HEX*1 + 56" 15 "PHY=HEX*1 + 56" 16 "PHY=HEX*1 + 56" 17 "PHY=HEX*1 + 56" 18 "PHY=HEX*1 + 56" 19 "PHY=HEX*1 + 56" 20 "PHY=HEX*1 + 56" 21 "PHY=HEX*1 + 56" 22 "PHY=HEX*1 + 56" 23 "PHY=HEX*1 + 56" 24 "PHY=HEX*1 + 56" 25 "PHY=HEX*1 + 56" 26 "PHY=HEX*1 + 56" 27 "PHY=HEX*1 + 56" 28 "PHY=HEX*1 + 56" 29 "PHY=HEX*1 + 56" 30 "PHY=HEX*1 + 56" 31 "PHY=HEX*1 + 56" 32 "PHY=HEX*1 + 56" 33 "PHY=HEX*1 + 56" 34 "PHY=HEX*1 + 56" 35 "PHY=HEX*1 + 56" 36 "PHY=HEX*1 + 56" 37 "0x25~0xFD:Reserved" 253 "0x25~0xFD:Reserved" 254 "HI" 255 "Invalid" ;
VAL_ 1216 BCM_Crc1Val 0 "0x0x0~0xFF:CRCValue" 255 "0x0x0~0xFF:CRCValue" ;
VAL_ 1216 BCM_AlvCnt1Val 0 "AlvCntValue" 1 "AlvCntValue" 2 "AlvCntValue" 3 "AlvCntValue" 4 "AlvCntValue" 5 "AlvCntValue" 6 "AlvCntValue" 7 "AlvCntValue" 8 "AlvCntValue" 9 "AlvCntValue" 10 "AlvCntValue" 11 "AlvCntValue" 12 "AlvCntValue" 13 "AlvCntValue" 14 "AlvCntValue" 15 "AlvCntValue" ;
VAL_ 1216 PHEV_FuelDrReleaseSwSta 0 "Off" 1 "On" 2 "Not Used" 3 "Error Indicator" ;
VAL_ 1216 StrWhlWrmr_MKBDBpReq 0 "Beep Off" 1 "Beep On" 2 "Not Used" 3 "Error Indicator" ;
VAL_ 1216 BckGls_RrGlsHtdMKBDBpReq 0 "Beep Off" 1 "Beep On" 2 "Not Used" 3 "Error Indicator" ;
VAL_ 1216 Wndshld_FrtGlsHtdMKBDBpReq 0 "Beep Off" 1 "Beep On" 2 "Not Used" 3 "Error Indicator" ;
VAL_ 1216 BAlarm_AutoLockrReq 0 "Off" 1 "Lock" 2 "Not Used" 3 "Error Indicator" ;
VAL_ 1216 TiltTele_SmrtIMSDBNum 0 "None" 1 "0x1~0x97E:SmartIMS DB Number (1~2430)" 2430 "0x1~0x97E:SmartIMS DB Number (1~2430)" 2431 "0x97F~0xFFE:Reserved" 4094 "0x97F~0xFFE:Reserved" 4095 "Error indicator" ;
VAL_ 1216 Tilt_IMSMemoryCmd 0 "None" 1 "Memory 1" 2 "Memory 2" 3 "Memory 3" ;
VAL_ 1216 Tele_IMSMemoryCmd 0 "None" 1 "Memory 1" 2 "Memory 2" 3 "Memory 3" ;
VAL_ 171 BLTN_CAM_UI_Mode_Tmt_Req 0 "Default" 1 "BLTN_CAM UI Terminate Request" 2 "Reserved" 3 "invalid" ;
VAL_ 171 BLTN_CAM_Dis_Touch_BeepSound 0 "Off" 1 "ON" 2 "Keyboard On" 3 "invalid" ;
VAL_ 171 BLTN_CAM_PopUp_Req 0 "Default" 1 "Event Video Record On by manual switch" 2 "Time Lapse Record Started" 3 "Time Lapse Record Ended" 4 "micro SD card inserted" 5 "micro SD card removed" 6 "SD Card has problem(format required or need to be replaced)" 7 "Start Parking recording" 8 "Can not Start Parking recording (SD card is removed, not recognizable, or has problem)" 9 "Can not Record Event Video (SD card is removed, not recognizable, or has problem)" 10 "SD Card Unmounted" 11 "Time Lapse Record Ended without recorded file(Record frames are not enough to save.)" 12 "RESERVED" 13 "RESERVED" 14 "RESERVED" 15 "Invalid" ;
VAL_ 171 BLTN_CAM_File_List_Renew 0 "Defalut" 1 "the file list and storage space are renewed." 2 "reserved" 3 "Invalid" ;
VAL_ 171 BLTN_CAM_Wifi_Pwd_Chg_State 0 "Default" 1 "the password is changed" 2 "Failed, wrong password, can't change password" 3 "Invalid" ;
VAL_ 2323816449 C_CtrlDrLockRlyCCS_Copy_2 0 "Off (default)" 1 "On (remote Lock Command)" 2 "Reserved" 3 "Invalid" ;
VAL_ 2323816449 C_TeleHeatingCmdIBOX_Copy_2 0 "Off (default)" 1 "On(Remote Heating On)" 2 "Reserved" 3 "Invalid" ;
VAL_ 2323816449 C_TeleStrgWhlHeatingCmdIBOX_Copy_2 0 "Off (default)" 1 "On(Remote Heating On)" 2 "Reserved" 3 "Invalid" ;
VAL_ 2323816449 C_TeleDefoggerHeatingCmdIBOX_Copy_2 0 "Off (default)" 1 "On(Remote Heating On)" 2 "Reserved" 3 "Invalid" ;
VAL_ 2323816449 C_TeleDrvSeatOpCmdIBOX_Copy_2 0 "Init" 1 "Unused" 2 "Seat Heat&Vent OFF" 3 "Seat_Vent_Low" 4 "Seat_Vent_Mid" 5 "Seat_Vent_High" 6 "Seat_Heat_Low" 7 "Seat_Heat_Mid" 8 "Seat_Heat_High" 9 "Unused" 10 "Unused" 11 "Unused" 12 "Unused" 13 "Unused" 14 "Unused" 15 "Invalid" ;
VAL_ 2323816449 C_CtrlDrUnlockRlyCCS_Copy_2 0 "0ff" 1 "On (Remote Unlock Command)" 2 "Reserved" 3 "Invalid" ;
VAL_ 2323816449 C_TeleAstSeatOpCmdIBOX_Copy_2 0 "Init" 1 "Unused" 2 "Seat Heat&Vent OFF" 3 "Seat_Vent_Low" 4 "Seat_Vent_Mid" 5 "Seat_Vent_High" 6 "Seat_Heat_Low" 7 "Seat_Heat_Mid" 8 "Seat_Heat_High" 9 "Unused" 10 "Unused" 11 "Unused" 12 "Unused" 13 "Unused" 14 "Unused" 15 "Invalid" ;
VAL_ 2323816449 C_TeleRRSeatOpCmdIBOX_Copy_2 0 "Init" 1 "Unused" 2 "Seat Heat&Vent OFF" 3 "Seat_Vent_Low" 4 "Seat_Vent_Mid" 5 "Seat_Vent_High" 6 "Seat_Heat_Low" 7 "Seat_Heat_Mid" 8 "Seat_Heat_High" 9 "Unused" 10 "Unused" 11 "Unused" 12 "Unused" 13 "Unused" 14 "Unused" 15 "Invalid" ;
VAL_ 2323816449 C_TeleRLSeatOpCmdIBOX_Copy_1 0 "Init" 1 "Unused" 2 "Seat Heat&Vent OFF" 3 "Seat_Vent_Low" 4 "Seat_Vent_Mid" 5 "Seat_Vent_High" 6 "Seat_Heat_Low" 7 "Seat_Heat_Mid" 8 "Seat_Heat_High" 9 "Unused" 10 "Unused" 11 "Unused" 12 "Unused" 13 "Unused" 14 "Unused" 15 "Invalid" ;
VAL_ 2323816449 C_DrvWindowCmdAVN_Copy_2 0 "No action" 1 "Manual Down" 2 "Manual Up" 3 "25% Open" 4 "50% Open" 5 "Auto Down" 6 "Auto Up" 7 "15% Open" 8 "Unused" 9 "Unused" 10 "Unused" 11 "Unused" 12 "Unused" 13 "Unused" 14 "Unused" 15 "Invalid" ;
VAL_ 2323816449 C_HazardFromCCS_Copy_2 0 "Off" 1 "On (Remote Hazard On)" 2 "Reserved" 3 "Invalid" ;
VAL_ 2323816449 C_AstWindowCmdAVN_Copy_2 0 "No action" 1 "Manual Down" 2 "Manual Up" 3 "25% Open" 4 "50%Open" 5 "Auto Down" 6 "Auto Up" 7 "15% Open" 8 "Unused" 9 "Unused" 10 "Unused" 11 "Unused" 12 "Unused" 13 "Unused" 14 "Unused" 15 "Invalid" ;
VAL_ 2323816449 C_RRWindowCmdAVN_Copy_2 0 "No action" 1 "Manual Down" 2 "Manual Up" 3 "25% Open" 4 "50% Open" 5 "Auto Down" 6 "Auto Up" 7 "15% Open" 8 "Unused" 9 "Unused" 10 "Unused" 11 "Unused" 12 "Unused" 13 "Unused" 14 "Unused" 15 "Invalid" ;
VAL_ 2323816449 C_RLWindowCmdAVN_Copy_2 0 "No action" 1 "Manual Down" 2 "Manual Up" 3 "25% Open" 4 "50% Open" 5 "Auto Down" 6 "Auto UP" 7 "15% Open" 8 "Unused" 9 "Unused" 10 "Unused" 11 "Unused" 12 "Unused" 13 "Unused" 14 "Unused" 15 "Invalid" ;
VAL_ 2323816449 TailCtrlReq_Copy 0 "No Action(Default)" 1 "Tail Off" 2 "Tail On" 3 "Error Indicator" ;
VAL_ 2323816449 HazardCtrlReq_Copy 0 "No Action(Default)" 1 "Hazard Off" 2 "Hazard On" 3 "Error Indicator" ;
VAL_ 2323816449 HU_DATC_AirCleaningSet_Copy_1 0 "Air Cleaning System Off" 1 "Air Cleaning System On" 2 "Air Cleaning System Not Support" 3 "Invalid" ;
VAL_ 2323816449 C_PanicFromCCS_Copy_2 0 "Off" 1 "On (Remote Horn and Hazard On)" 2 "Reserved" 3 "Invalid" ;
VAL_ 2323816449 C_TeleFrontHeatingCmdIBOX_Copy_1 0 "Off (Default)" 1 "On (Remote Heating On)" 2 "Reserved" 3 "Invalid" ;
VAL_ 2323816449 RAC_AirCleaningCtrlReq_Copy_1 0 "Deactive air cleaning control" 1 "Active air cleaning control" 2 "Not used" 3 "invalid" ;
VAL_ 2323816449 C_PreCrankReq_Copy 0 "Default" 1 "Req On" 2 "Not Support" 3 "Invalid" ;
VAL_ 2323816450 HU_CDMOpenCmd_Copy_1 0 "Default" 1 "CDM Open" 2 "CDM Close" 3 "Invalid" ;
VAL_ 2323816450 CargoTrgTempSet 0 "-30~+30" 1 "-30~+30" 2 "-30~+30" 3 "-30~+30" 4 "-30~+30" 5 "-30~+30" 6 "-30~+30" 7 "-30~+30" 8 "-30~+30" 9 "-30~+30" 10 "-30~+30" 11 "-30~+30" 12 "-30~+30" 13 "-30~+30" 14 "-30~+30" 15 "-30~+30" 16 "-30~+30" 17 "-30~+30" 18 "-30~+30" 19 "-30~+30" 20 "-30~+30" 21 "-30~+30" 22 "-30~+30" 23 "-30~+30" 24 "-30~+30" 25 "-30~+30" 26 "-30~+30" 27 "-30~+30" 28 "-30~+30" 29 "-30~+30" 30 "-30~+30" 31 "-30~+30" 32 "-30~+30" 33 "-30~+30" 34 "-30~+30" 35 "-30~+30" 36 "-30~+30" 37 "-30~+30" 38 "-30~+30" 39 "-30~+30" 40 "-30~+30" 41 "-30~+30" 42 "-30~+30" 43 "-30~+30" 44 "-30~+30" 45 "-30~+30" 46 "-30~+30" 47 "-30~+30" 48 "-30~+30" 49 "-30~+30" 50 "-30~+30" 51 "-30~+30" 52 "-30~+30" 53 "-30~+30" 54 "-30~+30" 55 "-30~+30" 56 "-30~+30" 57 "-30~+30" 58 "-30~+30" 59 "-30~+30" 60 "-30~+30" 61 "RESERVED" 62 "RESERVED" 63 "Invaild" ;
VAL_ 2323816450 CompControlReq 0 "No Action(Default)" 1 "Off" 2 "On" 3 "Invaild" ;
VAL_ 2323816450 HU_StrgWhlHeatingSet_CCS_Copy 0 "Default (off)" 1 "Step1 On" 2 "Step2 On" 3 "Reserved" 4 "Reserved" 5 "Reserved" 6 "Reserved" 7 "Invalid" ;
VAL_ 2323816450 CargoControlMasterSet 0 "No Action(Default)" 1 "Off" 2 "On" 3 "Invaild" ;
VAL_ 2323816450 C_TeleTRSeatOpCmdIBOX_CCU 0 "Init" 1 "Unused" 2 "Seat Heat&Vent OFF" 3 "Seat_Vent_Low" 4 "Seat_Vent_Mid" 5 "Seat_Vent_High" 6 "Seat_Heat_Low" 7 "Seat_Heat_Mid" 8 "Seat_Heat_High" 9 "Unused" 10 "Unused" 11 "Unused" 12 "Unused" 13 "Unused" 14 "Unused" 15 "Invalid" ;
VAL_ 2323816450 C_TeleTLSeatOpCmdIBOX_CCU 0 "Init" 1 "Unused" 2 "Seat Heat&Vent OFF" 3 "Seat_Vent_Low" 4 "Seat_Vent_Mid" 5 "Seat_Vent_High" 6 "Seat_Heat_Low" 7 "Seat_Heat_Mid" 8 "Seat_Heat_High" 9 "Unused" 10 "Unused" 11 "Unused" 12 "Unused" 13 "Unused" 14 "Unused" 15 "Invalid" ;
VAL_ 2323816450 SetCargoWrngValue 0 "0~30" 1 "0~30" 2 "0~30" 3 "0~30" 4 "0~30" 5 "0~30" 6 "0~30" 7 "0~30" 8 "0~30" 9 "0~30" 10 "0~30" 11 "0~30" 12 "0~30" 13 "0~30" 14 "0~30" 15 "0~30" 16 "0~30" 17 "0~30" 18 "0~30" 19 "0~30" 20 "0~30" 21 "0~30" 22 "0~30" 23 "0~30" 24 "0~30" 25 "0~30" 26 "0~30" 27 "0~30" 28 "0~30" 29 "0~30" 30 "0~30" 31 "Invalid" ;
VAL_ 2323816450 FrunkCtrlReq 0 "No Action(Default)" 1 "Close" 2 "Open" 3 "invaild" ;
VAL_ 2323816450 C_EsyAcsProfileID_CCU 0 "Default" 1 "Guest" 2 "Profile 1" 3 "Profile 2" 4 "Profile 3" 5 "Profile 4" 6 "Profile 5" 7 "Profile 6" 8 "Profile 7" 9 "Profile 8" 10 "Profile 9" 11 "RESERVED" 12 "RESERVED" 13 "RESERVED" 14 "RESERVED" 15 "Invalid" ;
VAL_ 2382594049 DATC_Crc3Val 0 "0x0x0~0xFFFF:CRCValue" 65535 "0x0x0~0xFFFF:CRCValue" ;
VAL_ 2382594049 DATC_AlvCnt3Val 0 "0x0x0~0xFF:AlvCntValue" 255 "0x0x0~0xFF:AlvCntValue" ;
VAL_ 2382594049 DATC_DrvTempCDis 0 "Blank Display" 1 "'LO' Display" 254 "'HI' Display" 255 "Error Indicator" ;
VAL_ 2382594049 DATC_DrvTempFDis 0 "Blank Display" 1 "'LO' Display" 254 "'HI' Display" 255 "Error Indicator" ;
VAL_ 2382594049 DATC_PassTempCDis 0 "Blank Display" 1 "'LO' Display" 254 "'HI' Display" 255 "Error Indicator" ;
VAL_ 2382594049 DATC_PassTempFDis 0 "Blank Display" 1 "'LO' Display" 254 "'HI' Display" 255 "Error Indicator" ;
VAL_ 2382594049 DATC_TempDispSta 0 "OLD Set Temp Display range" 1 "NEW Set Temp Display Range(Default)" 2 "Reserved" 3 "Error Indicator" ;
VAL_ 2382594049 DATC_PreEngOnReq2 0 "Default" 1 "Off" 2 "PreEngineOn Request" 3 "Error Indicator" ;
VAL_ 2424580353 DATC_Crc12Val 0 "0x0x0~0xFFFF:CRCValue" 65535 "0x0x0~0xFFFF:CRCValue" ;
VAL_ 2424580353 DATC_AlvCnt12Val 0 "0x0x0~0xFF:AlvCntValue" 255 "0x0x0~0xFF:AlvCntValue" ;
VAL_ 2424580353 DATC_StrWhlHtrSwReq 0 "Default" 1 "OFF" 2 "ON" 3 "Error Indicator" ;
VAL_ 2424580353 DATC_FRStHtrSwReq 0 "Default" 1 "OFF" 2 "ON" 3 "Error Indicator" ;
VAL_ 2424580353 DATC_FRStVentSwReq 0 "Default" 1 "OFF" 2 "ON" 3 "Error Indicator" ;
VAL_ 2424580353 DATC_RrDefSw 0 "Default" 1 "OFF" 2 "ON" 3 "Error Indicator" ;
VAL_ 2424580353 DATC_FLStOpReq 0 "Default" 1 "Integrated control OFF" 2 "OFF" 3 "Left Seat Ventilation 1st ON" 4 "Left Seat Ventilation 1st&2nd ON" 5 "Left Seat Ventilation 1st&2nd&3rd ON" 6 "Left Seat Warmer 1st ON" 7 "Left Seat Warmer 1st&2nd ON" 8 "Left Seat Warmer 1st&2nd&3rd ON" 9 "Not Used" 10 "Not Used" 11 "Not Used" 12 "Not Used" 13 "Not Used" 14 "Not Used" 15 "Error Indicator" ;
VAL_ 2424580353 DATC_FRStOpReq 0 "Default" 1 "Integrated control OFF" 2 "OFF" 3 "Right Seat Ventilation 1st ON" 4 "Right Seat Ventilation 1st&2nd ON" 5 "Right Seat Ventilation 1st&2nd&3rd ON" 6 "Right Seat Warmer 1st ON" 7 "Right Seat Warmer 1st&2nd ON" 8 "Right Seat Warmer 1st&2nd&3rd ON" 9 "Not Used" 10 "Not Used" 11 "Not Used" 12 "Not Used" 13 "Not Used" 14 "Not Used" 15 "Error Indicaotr" ;
VAL_ 2424580353 DATC_FLStHtrSwReq 0 "Default" 1 "OFF" 2 "ON" 3 "Error Indicator" ;
VAL_ 2424580353 DATC_FLStVentSwReq 0 "Default" 1 "OFF" 2 "ON" 3 "Error Indicator" ;
VAL_ 2424580353 DATC_FLStTmblrSwReq 0 "Default" 1 "Up" 2 "Down" 3 "Error Indicator" ;
VAL_ 2424580353 DATC_FRStTmblrSwReq 0 "Default" 1 "Up" 2 "Down" 3 "Error Indicator" ;
VAL_ 2424580353 DATC_RRStHtrSwReq 0 "Default" 1 "OFF" 2 "ON" 3 "Error Indicator" ;
VAL_ 2424580353 DATC_RRStVentSwReq 0 "Default" 1 "OFF" 2 "ON" 3 "Error Indicator" ;
VAL_ 2424580353 DATC_RLStHtrSwReq 0 "Default" 1 "OFF" 2 "ON" 3 "Error Indicator" ;
VAL_ 2424580353 DATC_RLStVentSwReq 0 "Default" 1 "OFF" 2 "ON" 3 "Error Indicator" ;
VAL_ 2424580353 DATC_FRWndShldHtSW 0 "Default" 1 "Off" 2 "On" 3 "Error Indicator" ;
VAL_ 2424580353 DATC_WhistlelNoise 0 "Default" 1 "Off" 2 "On (Whistle Noise Prevent)" 3 "Error Indicator" ;
VAL_ 2424580353 DATC_WdwClsReq 0 "Default" 1 "Close Request" 2 "Reserved" 3 "Error Indicator" ;
VAL_ 2424580353 DATC_RRSyncDis 0 "Rear SYNC Off" 1 "Rear SYNC On" 2 "Not used" 3 "Error Indicator" ;
VAL_ 1219 BLTN_CAM_Rec_OWD_NvalueSet 0 "Default" 1 "Off" 2 "On" 3 "Invalid" ;
VAL_ 1219 BLTN_CAM_Time_Stm_NvalueSet 0 "Default" 1 "Off" 2 "On" 3 "Invalid" ;
VAL_ 1219 BLTN_CAM_Spd_Stm_NvalueSet 0 "Default" 1 "Off" 2 "On" 3 "Invalid" ;
VAL_ 1219 BLTN_CAM_Locatn_Stm_NvalueSet 0 "Default" 1 "Off" 2 "On" 3 "Invalid" ;
VAL_ 1219 BLTN_CAM_TrnSig_Stm_NvalueSet 0 "Default" 1 "Off" 2 "On" 3 "Invalid" ;
VAL_ 1219 BLTN_CAM_AclBrk_Stm_NvalueSet 0 "Default" 1 "Off" 2 "On" 3 "Invalid" ;
VAL_ 1219 BLTN_CAM_Rec_DEV_NvalueSet 0 "Default" 1 "Off" 2 "On" 3 "Invalid" ;
VAL_ 1219 BLTN_CAM_GearPos_Stm_NvalueSet 0 "Default" 1 "Off" 2 "On" 3 "Invalid" ;
VAL_ 1219 BLTN_CAM_EVSen_Stm_NvalueSet 0 "Default" 1 "Off" 2 "On" 3 "Invalid" ;
VAL_ 1219 BLTN_CAM_Strangl_Stm_NvalueSet 0 "Default" 1 "Off" 2 "On" 3 "Invalid" ;
VAL_ 1219 BLTN_CAM_EV_RecMaxTime_NvalueSet 0 "Default" 1 "Off" 2 "On" 3 "Invalid" ;
VAL_ 1219 BLTN_CAM_PrkTime_NvalueSet 0 "Default" 1 "0x01~0xFB:1~ 251  hr" 251 "0x01~0xFB:1~ 251  hr" 252 "RESERVED" 253 "RESERVED" 254 "Not Supported" 255 "Invalid" ;
VAL_ 1219 BLTN_CAM_EV_BfrTime_NvalueSet 0 "10~20 sec" 1 "10~20 sec" 2 "10~20 sec" 3 "10~20 sec" 4 "10~20 sec" 5 "10~20 sec" 6 "10~20 sec" 7 "10~20 sec" 8 "10~20 sec" 9 "10~20 sec" 10 "10~20 sec" 11 "RESERVED" 12 "RESERVED" 13 "RESERVED" 14 "RESERVED" 15 "RESERVED" 16 "RESERVED" 17 "RESERVED" 18 "RESERVED" 19 "RESERVED" 20 "RESERVED" 21 "RESERVED" 22 "RESERVED" 23 "RESERVED" 24 "RESERVED" 25 "RESERVED" 26 "RESERVED" 27 "RESERVED" 28 "RESERVED" 29 "RESERVED" 30 "RESERVED" 31 "Invalid" ;
VAL_ 1219 BLTN_CAM_Rec_OWP_NvalueSet 0 "Default" 1 "Off" 2 "On" 3 "Invalid" ;
VAL_ 1219 BLTN_CAM_EV_AftTime_NvalueSet 0 "10~20 sec" 1 "10~20 sec" 2 "10~20 sec" 3 "10~20 sec" 4 "10~20 sec" 5 "10~20 sec" 6 "10~20 sec" 7 "10~20 sec" 8 "10~20 sec" 9 "10~20 sec" 10 "10~20 sec" 11 "RESERVED" 12 "RESERVED" 13 "RESERVED" 14 "RESERVED" 15 "RESERVED" 16 "RESERVED" 17 "RESERVED" 18 "RESERVED" 19 "RESERVED" 20 "RESERVED" 21 "RESERVED" 22 "RESERVED" 23 "RESERVED" 24 "RESERVED" 25 "RESERVED" 26 "RESERVED" 27 "RESERVED" 28 "RESERVED" 29 "RESERVED" 30 "RESERVED" 31 "Invalid" ;
VAL_ 1219 BLTN_CAM_TML_Int_NvalueSet 0 "Default" 1 "1~ 10 sec" 2 "1~ 10 sec" 3 "1~ 10 sec" 4 "1~ 10 sec" 5 "1~ 10 sec" 6 "1~ 10 sec" 7 "1~ 10 sec" 8 "1~ 10 sec" 9 "1~ 10 sec" 10 "1~ 10 sec" 11 "Reserved" 12 "Reserved" 13 "Reserved" 14 "Reserved" 15 "Invalid" ;
VAL_ 1219 BLTN_CAM_Sen_DEV_NvalueSet 0 "Default" 1 "Level 1" 2 "Level 2" 3 "Level 3" 4 "Level 4" 5 "Level 5" 6 "Reserved" 7 "Reserved" 8 "Reserved" 9 "Reserved" 10 "Reserved" 11 "Reserved" 12 "Reserved" 13 "Reserved" 14 "Reserved" 15 "Invalid" ;
VAL_ 1219 BLTN_CAM_Sen_PEV_NvalueSet 0 "Default" 1 "Level 1" 2 "Level 2" 3 "Level 3" 4 "Level 4" 5 "Level 5" 6 "Reserved" 7 "Reserved" 8 "Reserved" 9 "Reserved" 10 "Reserved" 11 "Reserved" 12 "Reserved" 13 "Reserved" 14 "Reserved" 15 "Invalid" ;
VAL_ 1219 BLTN_CAM_Rec_PEV_NvalueSet 0 "Default" 1 "Off" 2 "On" 3 "Invalid" ;
VAL_ 1219 BLTN_CAM_AudRec_NvalueSet 0 "Default" 1 "Off" 2 "On" 3 "Invalid" ;
VAL_ 172 BLTN_CAM_FR_VerPos_NvalueSet 0 "Mid" 1 "Upper Level (1 ~ 10)" 2 "Upper Level (1 ~ 10)" 3 "Upper Level (1 ~ 10)" 4 "Upper Level (1 ~ 10)" 5 "Upper Level (1 ~ 10)" 6 "Upper Level (1 ~ 10)" 7 "Upper Level (1 ~ 10)" 8 "Upper Level (1 ~ 10)" 9 "Upper Level (1 ~ 10)" 10 "Upper Level (1 ~ 10)" 11 "RESERVED" 12 "RESERVED" 13 "RESERVED" 14 "RESERVED" 15 "RESERVED" 16 "RESERVED" 17 "Lower Level (-1 ~ -10)" 18 "Lower Level (-1 ~ -10)" 19 "Lower Level (-1 ~ -10)" 20 "Lower Level (-1 ~ -10)" 21 "Lower Level (-1 ~ -10)" 22 "Lower Level (-1 ~ -10)" 23 "Lower Level (-1 ~ -10)" 24 "Lower Level (-1 ~ -10)" 25 "Lower Level (-1 ~ -10)" 26 "Lower Level (-1 ~ -10)" 27 "RESERVED" 28 "RESERVED" 29 "RESERVED" 30 "RESERVED" 31 "Invalid" ;
VAL_ 172 BLTN_CAM_AppNoti_PEV_NvalueSet 0 "Default" 1 "Off" 2 "On" 3 "Invalid" ;
VAL_ 172 BLTN_CAM_WiFi_AutoOn_NvalueSet 0 "Default" 1 "Off" 2 "On" 3 "Invalid" ;
VAL_ 172 BLTN_CAM_StoProp_NvalueSet 0 "Normal" 1 "On While Recordings" 2 "On While Parked" 3 "Driving Events" 4 "Parked Events" 5 "Reserved" 6 "Reserved" 7 "Reserved" 8 "Reserved" 9 "Reserved" 10 "Reserved" 11 "Reserved" 12 "Reserved" 13 "Reserved" 14 "Reserved" 15 "Invalid" ;
VAL_ 172 CF_AVN_BLTN_CAM_USMReset 0 "Default" 1 "Built-in CAM USM Reset" 2 "Reserved" 3 "Invalid" ;
VAL_ 172 CF_AVN_BLTN_CAM_RecReset 0 "Default" 1 "Record Data Reset(format)" 2 "Reserved" 3 "Invalid" ;
VAL_ 172 BLTN_CAM_File_DEL_CPY_Cmd 0 "Default" 1 "Pause the operation" 2 "Cancel the operation" 3 "Continue operation" 4 "Reserved" 5 "Reserved" 6 "Reserved" 7 "Reserved" 8 "Reserved" 9 "Reserved" 10 "Reserved" 11 "Reserved" 12 "Reserved" 13 "Reserved" 14 "Reserved" 15 "Invalid" ;
VAL_ 172 BLTN_CAM_LVDS_Mode_Cmd 0 "Front and Rear Camera" 1 "Front Camera for AR Navi." 2 "Built-In Cam Engineer Mode" 3 "Reserved" ;
VAL_ 172 HU_BLTN_CAM_Disp_Touch_Pos_X 0 "0x0x0~0x77F:X position of the touch(Pixel)" 1919 "0x0x0~0x77F:X position of the touch(Pixel)" 2046 "Default" 2047 "Invalid" ;
VAL_ 172 HU_BLTN_CAM_Disp_Touch_Pos_Y 0 "0x0x0~0x3FD:Y position of the touch(Pixel)" 1021 "0x0x0~0x3FD:Y position of the touch(Pixel)" 1022 "Default" 1023 "Invalid" ;
VAL_ 172 MEV_Rec_Req 0 "Default" 1 "On" 2 "RESERVED" 3 "Invalid" ;
VAL_ 172 BLTN_CAM_RR_VerPos_NvalueSet 0 "Mid" 1 "Upper Level (1 ~ 10)" 2 "Upper Level (1 ~ 10)" 3 "Upper Level (1 ~ 10)" 4 "Upper Level (1 ~ 10)" 5 "Upper Level (1 ~ 10)" 6 "Upper Level (1 ~ 10)" 7 "Upper Level (1 ~ 10)" 8 "Upper Level (1 ~ 10)" 9 "Upper Level (1 ~ 10)" 10 "Upper Level (1 ~ 10)" 11 "RESERVED" 12 "RESERVED" 13 "RESERVED" 14 "RESERVED" 15 "RESERVED" 16 "RESERVED" 17 "Lower Level (-1 ~ -10)" 18 "Lower Level (-1 ~ -10)" 19 "Lower Level (-1 ~ -10)" 20 "Lower Level (-1 ~ -10)" 21 "Lower Level (-1 ~ -10)" 22 "Lower Level (-1 ~ -10)" 23 "Lower Level (-1 ~ -10)" 24 "Lower Level (-1 ~ -10)" 25 "Lower Level (-1 ~ -10)" 26 "Lower Level (-1 ~ -10)" 27 "RESERVED" 28 "RESERVED" 29 "RESERVED" 30 "RESERVED" 31 "Invalid" ;
VAL_ 172 TML_Rec_Req 0 "Default" 1 "Start Request" 2 "End Request" 3 "Invalid" ;
VAL_ 172 BLTN_CAM_SD_Card_UnMt_Mt_Req 0 "Default" 1 "UnMount Request" 2 "Mount Request" 3 "Invalid" ;
VAL_ 1239 HU_ADMSettingState 0 "ADM On (Setting Vaule in HU)" 1 "ADM Off" 2 "Reserved" 3 "Reserved" 4 "Reserved" 5 "Reserved" 6 "Reserved" 7 "Invalid" ;
VAL_ 1239 HU_PwrState 0 "Default" 1 "Normal On" 2 "ADM" 3 "Wait for door open" 4 "Logic Off" 5 "Remote Engine On" 6 "Reserved" 7 "Reserved" 8 "Reserved" 9 "Reserved" 10 "Reserved" 11 "Reserved" 12 "Reserved" 13 "Reserved" 14 "Reserved" 15 "Invalid" ;
VAL_ 1239 HU_MKBD_ModeSwitch 0 "Key off" 1 "AVNT mode on" 2 "DATC mode on" 3 "Invalid" ;
VAL_ 1239 HU_LCDState 0 "Default" 1 "On" 2 "Off" 3 "RESERVED" 4 "RESERVED" 5 "RESERVED" 6 "RESERVED" 7 "Invalid" ;
VAL_ 1239 HU_VehiclePwr 0 "Key out or Audio OFF" 1 "Not used" 2 "ACC or Audio ON" 3 "KBD Wake-up" 4 "Waiting for Good-Bye (Key out or Audio OFF)" 5 "Not used" 6 "Not used" 7 "Not used" 8 "Not used" 9 "Not used" 10 "Not used" 11 "Not used" 12 "Not used" 13 "Not used" 14 "Not used" 15 "Invalid" ;
VAL_ 1239 HU_BtnShowReq 0 "default" 1 "on" 2 "off" 3 "reserved" 4 "reserved" 5 "reserved" 6 "reserved" 7 "invalid" ;
VAL_ 1245 HU_CampModeSta 0 "Default" 1 "Off" 2 "On" 3 "Invalid" ;
VAL_ 1245 HU_LatchHoldReq 0 "Default" 1 "Latchhold Request" 2 "No Latchhold Request" 3 "Invalid" ;
VAL_ 1245 HU_HighPowerChargingkW 0 "Default(Keep default value)" 1 "Setting kW value" 2 "Setting kW value" 3 "Setting kW value" 4 "Setting kW value" 5 "Setting kW value" 6 "Setting kW value" 7 "Setting kW value" 8 "Setting kW value" 9 "Setting kW value" 10 "Setting kW value" 11 "Setting kW value" 12 "Setting kW value" 13 "Setting kW value" 14 "Setting kW value" 15 "Setting kW value" 16 "Setting kW value" 17 "Setting kW value" 18 "Setting kW value" 19 "Setting kW value" 20 "Setting kW value" 21 "Setting kW value" 22 "Setting kW value" 23 "Setting kW value" 24 "Setting kW value" 25 "Setting kW value" 26 "Setting kW value" 27 "Setting kW value" 28 "Setting kW value" 29 "Setting kW value" 30 "Setting kW value" 31 "Setting kW value" 32 "Setting kW value" 33 "Setting kW value" 34 "Setting kW value" 35 "Setting kW value" 36 "Setting kW value" 37 "Setting kW value" 38 "Setting kW value" 39 "Setting kW value" 40 "Setting kW value" 41 "Setting kW value" 42 "Setting kW value" 43 "Setting kW value" 44 "Setting kW value" 45 "Setting kW value" 46 "Setting kW value" 47 "Setting kW value" 48 "Setting kW value" 49 "Setting kW value" 50 "Setting kW value" 51 "Setting kW value" 52 "Setting kW value" 53 "Setting kW value" 54 "Setting kW value" 55 "Setting kW value" 56 "Setting kW value" 57 "Setting kW value" 58 "Setting kW value" 59 "Setting kW value" 60 "Setting kW value" 61 "Setting kW value" 62 "Setting kW value" 63 "invalid" ;
VAL_ 1245 HU_FastChargingkW 0 "Default(keep default value)" 1 "Setting kW value" 2 "Setting kW value" 3 "Setting kW value" 4 "Setting kW value" 5 "Setting kW value" 6 "Setting kW value" 7 "Setting kW value" 8 "Setting kW value" 9 "Setting kW value" 10 "Setting kW value" 11 "Setting kW value" 12 "Setting kW value" 13 "Setting kW value" 14 "Setting kW value" 15 "Setting kW value" 16 "Setting kW value" 17 "Setting kW value" 18 "Setting kW value" 19 "Setting kW value" 20 "Setting kW value" 21 "Setting kW value" 22 "Setting kW value" 23 "Setting kW value" 24 "Setting kW value" 25 "Setting kW value" 26 "Setting kW value" 27 "Setting kW value" 28 "Setting kW value" 29 "Setting kW value" 30 "Setting kW value" 31 "Setting kW value" 32 "Setting kW value" 33 "Setting kW value" 34 "Setting kW value" 35 "Setting kW value" 36 "Setting kW value" 37 "Setting kW value" 38 "Setting kW value" 39 "Setting kW value" 40 "Setting kW value" 41 "Setting kW value" 42 "Setting kW value" 43 "Setting kW value" 44 "Setting kW value" 45 "Setting kW value" 46 "Setting kW value" 47 "Setting kW value" 48 "Setting kW value" 49 "Setting kW value" 50 "Setting kW value" 51 "Setting kW value" 52 "Setting kW value" 53 "Setting kW value" 54 "Setting kW value" 55 "Setting kW value" 56 "Setting kW value" 57 "Setting kW value" 58 "Setting kW value" 59 "Setting kW value" 60 "Setting kW value" 61 "Setting kW value" 62 "Setting kW value" 63 "invalid" ;
VAL_ 1240 HU_DistanceUnit 0 "Km" 1 "Mile" 2 "RESERVED" 3 "Invalid" ;
VAL_ 1240 HU_ThemeType 0 "Default" 1 "Aqua(Hyundai)" 2 "Magenta(Kia)" 3 "Eco White" 4 "Eco Black" 5 "Genesis(IKPE)" 6 "Magenta White" 7 "RESERVED" 8 "RESERVED" 9 "RESERVED" 10 "RESERVED" 11 "RESERVED" 12 "RESERVED" 13 "RESERVED" 14 "RESERVED" 15 "Invalid" 16 "Copper" 17 "Copper Rust" 18 "RESERVED" 19 "RESERVED" 20 "RESERVED" 21 "RESERVED" 22 "RESERVED" 23 "RESERVED" 24 "RESERVED" 25 "RESERVED" 26 "RESERVED" 27 "RESERVED" 28 "RESERVED" 29 "RESERVED" 30 "RESERVED" 31 "RESERVED" 32 "ccIC Light" 33 "ccIC Dark" 34 "RESERVED" 35 "RESERVED" 36 "RESERVED" 37 "RESERVED" 38 "RESERVED" 39 "RESERVED" 40 "RESERVED" 41 "RESERVED" 42 "RESERVED" 43 "RESERVED" 44 "RESERVED" 45 "RESERVED" 46 "RESERVED" 47 "RESERVED" 48 "RESERVED" 49 "RESERVED" 50 "RESERVED" 51 "RESERVED" 52 "RESERVED" 53 "RESERVED" 54 "RESERVED" 55 "RESERVED" 56 "RESERVED" 57 "RESERVED" 58 "RESERVED" 59 "RESERVED" 60 "RESERVED" 61 "RESERVED" 62 "RESERVED" 63 "RESERVED" ;
VAL_ 1240 HU_MicActivity 0 "Deactivated" 1 "Activated" 2 "RESERVED" 3 "Invalid" ;
VAL_ 1240 HU_Scheduled_Setting 0 "Scheduled not set" 1 "Scheduled set" 2 "RESERVED" 3 "RESERVED" 4 "RESERVED" 5 "RESERVED" 6 "60% SoC Requested" 7 "70% SoC Requested" 8 "80% SoC Requested" 9 "90% SoC Requested" 10 "100% SoC Requested" 11 "RESERVED" 12 "RESERVED" 13 "RESERVED" 14 "RESERVED" 15 "Invalid" ;
VAL_ 1240 AVN_RSPA_ModeSelect 0 "None" 1 "CCP focus (1st menu on the left)" 2 "Touch or CCP confirm (1st menu on the left)" 3 "CCP focus (2nd menu on the left)" 4 "Touch or CCP confirm (2nd menu on the left)" 5 "CCP focus (1st menu on the right)" 6 "Touch or CCP confirm (1st menu on the right)" 7 "CCP focus (2nd menu on the right)" 8 "Touch or CCP confirm (2nd menu on the right)" 9 "Touch or CCP confirm (1st menu Forward perpendicular on the left)" 10 "Touch or CCP confirm (2nd menu Forward perpendicular on the left)" 11 "Touch or CCP confirm (1st menu Forward perpendicular on the right)" 12 "Touch or CCP confirm (2nd menu Forward perpendicular on the right)" 13 "RESERVED" 14 "RESERVED" 15 "Invalid" ;
VAL_ 1240 CF_HU_GPSFlt 0 "Normal" 1 "Fault operation" 2 "TimeOut" 3 "Invalid" ;
VAL_ 1240 AVN_RSPA_CancelInput 0 "Init" 1 "No Input" 2 "Cancel Input" 3 "Invalid" ;
VAL_ 1240 AVN_RSPA_Disp_Rdy 0 "Impossible to display" 1 "Possible to display" 2 "RESERVED" 3 "Invalid" ;
VAL_ 1240 CF_AVN_ProfileIDRValue 0 "Default" 1 "Guest" 2 "Profile 1" 3 "Profile 2" 4 "Profile 3" 5 "Profile 4" 6 "Profile 5" 7 "Profile 6" 8 "Profile 7" 9 "Profile 8" 10 "Profile 9" 11 "RESERVED" 12 "RESERVED" 13 "RESERVED" 14 "RESERVED" 15 "Invalid" ;
VAL_ 1240 HazardFromHUSVM 0 "inactive" 1 "active" 2 "RESERVED" 3 "invalid" ;
VAL_ 1240 OMUOSMirCtrl 0 "Off" 1 "Fold" 2 "Unfold" 3 "invalid" ;
VAL_ 1240 OTAUIStatus 0 "Not Ready" 1 "Ready" 2 "RESERVED" 3 "Invalid" ;
VAL_ 1240 C_TeleActiveStatus 0 "Active" 1 "Deactive" 2 "RESERVED" 3 "Invalid" ;
VAL_ 1240 HU_AliveStatus 0 "Not Ready" 1 "On Mode" 2 "Head Unit Update Mode" 3 "Invalid" ;
VAL_ 1240 HU_RTCCheck 0 "Ready" 1 "Checking" 2 "RESERVED" 3 "Invalid" ;
VAL_ 1247 Navi_ParkingLot 0 "Unknown" 1 "Parking Garage (Æó¼âÇü ÁÖÂ÷Àå)" 2 "RESERVED" 3 "Invalid" ;
VAL_ 1247 Navi_AirConditionWarning 0 "Unknown" 1 "On(Close)" 2 "Off" 3 "Invalid" ;
VAL_ 1247 ADP_NActiveSound 0 "None" 1 "On the circuit track" 2 "In the circuit area" 3 "Out of circuit area" 4 "RESERVED" 5 "RESERVED" 6 "RESERVED" 7 "Invalid" ;
VAL_ 1218 C_AVN_PTGHeightNValueSet 0 "Default" 1 "Level 1" 2 "Level 2" 3 "Level 3" 4 "Level 4" 5 "Reserved" 6 "User Setting" 7 "Invalid" ;
VAL_ 1218 CF_AVN_SCCMLReset 0 "Default" 1 "Reset" 2 "Reserved" 3 "Invalid" ;
VAL_ 1218 C_TgltAwayCloseNValue 0 "Default" 1 "Off" 2 "On" 3 "Invalid" ;
VAL_ 1218 C_HAnBNValueSet 0 "Default" 1 "Arm Disarm Buzzer Off" 2 "Arm Disarm Buzzer On" 3 "Invalid" ;
VAL_ 1218 CF_AVN_RrSeatRemindNValueSet 0 "Default" 1 "Off  (Disable)" 2 "On (Enable)" 3 "Invalid" ;
VAL_ 1218 CF_AVN_DSWNValueSet 0 "Default" 1 "Off" 2 "On" 3 "Invalid" ;
VAL_ 1218 CF_AVN_RRPSU_RLNValueSet 0 "Default" 1 "Off (Disable)" 2 "On (Enable)" 3 "Reserved" 4 "Reserved" 5 "Reserved" 6 "Reserved" 7 "Invalid" ;
VAL_ 1218 CF_AVN_APSUNValueSet 0 "Default" 1 "Off (Disable)" 2 "50mm On (Enable)" 3 "75mm On (Enable)" 4 "Reserved" 5 "Reserved" 6 "Reserved" 7 "Invalid" ;
VAL_ 1218 CF_AVN_NCC_CameraNValueSet 0 "Default" 1 "Function Off" 2 "Manual Resume (Function On)" 3 "Automatic Resume (Function On)" 4 "Reserved" 5 "Reserved" 6 "Reserved" 7 "Invalid" ;
VAL_ 1218 CF_AVN_RRPSU_RRNValueSet 0 "Default" 1 "Off (Disable)" 2 "On (Enable)" 3 "Reserved" 4 "Reserved" 5 "Reserved" 6 "Reserved" 7 "Invalid" ;
VAL_ 1218 CF_AVN_HtBlcAstNValueSet 0 "Default" 1 "Normal" 2 "Back 1" 3 "Back 2" 4 "Back 3" 5 "Cush 1" 6 "Cush 2" 7 "Cush 3" 8 "Reserved" 9 "Reserved" 10 "Reserved" 11 "Reserved" 12 "Reserved" 13 "Reserved" 14 "Reserved" 15 "Invalid" ;
VAL_ 1218 CF_AVN_HtBlcDrvNValueSet 0 "Default" 1 "Normal" 2 "Back 1" 3 "Back 2" 4 "Back 3" 5 "Cush 1" 6 "Cush 2" 7 "Cush 3" 8 "Reserved" 9 "Reserved" 10 "Reserved" 11 "Reserved" 12 "Reserved" 13 "Reserved" 14 "Reserved" 15 "Invalid" ;
VAL_ 1218 CF_AVN_SCCModeNValueSet 0 "Not applied" 1 "Drive mode" 2 "SCC-ML" 3 "Invalid" ;
VAL_ 1218 CF_AVN_SCCMLChar1Set 0 "None" 1 "Level 1(Weak)" 2 "Level 2" 3 "Level 3" 4 "Level 4" 5 "Level 5(Strong)" 6 "Reserved" 7 "Invalid" ;
VAL_ 1218 CF_AVN_UIPNValueSet 0 "Default" 1 "Off (Disable)" 2 "On (Enable)" 3 "Invalid" ;
VAL_ 1218 CF_AVN_SCCMLChar2Set 0 "None" 1 "Level 1(Short)" 2 "Level 2" 3 "Level 3" 4 "Level 4" 5 "Reserved" 6 "Reserved" 7 "Invalid" ;
VAL_ 1218 CF_AVN_SCCMLChar3Set 0 "None" 1 "Level 1(Slow)" 2 "Level 2" 3 "Level 3" 4 "Level 4" 5 "Level 5(Fast)" 6 "Reserved" 7 "Invalid" ;
VAL_ 1218 CF_AVN_HDALCFuncNValueSet 0 "Default" 1 "Off" 2 "On" 3 "Invalid" ;
VAL_ 1251 IAU_Crc13Val 0 "0x0x0~0xFF:CRCValue" 255 "0x0x0~0xFF:CRCValue" ;
VAL_ 1251 IAU_AlvCnt13Val 0 "AlvCntValue" 1 "AlvCntValue" 2 "AlvCntValue" 3 "AlvCntValue" 4 "AlvCntValue" 5 "AlvCntValue" 6 "AlvCntValue" 7 "AlvCntValue" 8 "AlvCntValue" 9 "AlvCntValue" 10 "AlvCntValue" 11 "AlvCntValue" 12 "AlvCntValue" 13 "AlvCntValue" 14 "AlvCntValue" 15 "AlvCntValue" ;
VAL_ 1251 IAU_EsyAcsProfileID 0 "Default" 1 "Profile 1" 2 "Profile 2" 3 "Guest" ;
VAL_ 1251 IAU_SmrtPhnID 0 "None" 1 "ID1" 2 "ID2" 3 "ID3" 4 "ID4" 5 "ID5" 6 "ID6" 7 "ID7" 8 "ID8" 9 "Reseved" 10 "Reseved" 11 "Reseved" 12 "Reseved" 13 "Reseved" 14 "Reseved" 15 "Reseved" ;
VAL_ 1251 IAU_SmrtPhnCmd 0 "None" 1 "RESERVED" 2 "RESERVED" 3 "RESERVED" 4 "RESERVED" 5 "RESERVED" 6 "RESERVED" 7 "Tele Cranking Stop" 8 "RESERVED" 9 "Forward (RSPA)" 10 "Backward/Parking (RSPA)" 11 "Pause (RSPA)" 12 "Normal Cranking" 13 "RESERVED" 14 "RESERVED" 15 "RESERVED" ;
VAL_ 1251 IAUwFRU_ISK_LearningReq 0 "Default (Normal)" 1 "Start with PSK #1" 2 "Start with PSK #2" 3 "Start with PSK #3" 4 "Start with PSK #4" 5 "Start with PSK #5" 6 "Stop" 7 "Neutral" 8 "Reserved" 9 "Reserved" 10 "Reserved" 11 "Reserved" 12 "Reserved" 13 "Reserved" 14 "Reserved" 15 "Invalid" ;
VAL_ 1251 IAUwFPM_ISK_LearningReq 0 "Default" 1 "Start with PSK #1" 2 "Start with PSK #2" 3 "Start with PSK #3" 4 "Start with PSK #4" 5 "Start with PSK #5" 6 "Stop" 7 "Neutral" 8 "Reserved" 9 "Reserved" 10 "Reserved" 11 "Reserved" 12 "Reserved" 13 "Reserved" 14 "Reserved" 15 "Invalid" ;
VAL_ 1251 IAU2FRU_ISKLearnFdbck 0 "Default" 1 "Positive" 2 "Negative" 3 "Invalid" ;
VAL_ 1251 IAU2FPM_ISKLearnFdbck 0 "Default" 1 "Positive" 2 "Negative" 3 "Invalid" ;
VAL_ 1251 RSPA_FuncInfo 0 "None" 1 "Remote forward/backward" 2 "Remote parallel exit left" 3 "Remote parallel exit right" 4 "Reverse perpendicular left" 5 "Reverse perpendicular right" 6 "Reverse Parallel left" 7 "Reverse Parallel right" 8 "Reverse diagonal left" 9 "Reverse diagonal right" 10 "Forward diagonal left" 11 "Forward diagonal right" 12 "RESERVED" 13 "RESERVED" 14 "RESERVED" 15 "RESERVED" ;
VAL_ 1227 DrvIMS_MemoryP1Req 0 "None" 1 "P1" 2 "Not Used" 3 "Error Indicator" ;
VAL_ 1227 DrvIMS_PlyBckP2Req 0 "None" 1 "P2" 2 "Not Used" 3 "Error Indicator" ;
VAL_ 1227 DrvIMS_PlyBckP3Req 0 "None" 1 "P3" 2 "Not Used" 3 "Error Indicator" ;
VAL_ 1227 DrvIMS_PlyBckStpReq 0 "Off" 1 "Stop" 2 "Not Used" 3 "Error Indicator" ;
VAL_ 1227 SmrtIMS_PlyBckReq 0 "None" 1 "0x1~0x97E:Smart IMS DB Number(1~2430)" 2430 "0x1~0x97E:Smart IMS DB Number(1~2430)" 2431 "0x97F~0xFFE:RESERVED" 4094 "0x97F~0xFFE:RESERVED" 4095 "Invalid" ;
VAL_ 1227 DrvIMS_MemoryP2Req 0 "None" 1 "P2" 2 "Not Used" 3 "Error Indicator" ;
VAL_ 1227 PSM_IMSReq 0 "None" 1 "Replay1" 2 "Replay2" 3 "Replay3" 4 "Memory1" 5 "Memory2" 6 "Memory3" 7 "Stop" ;
VAL_ 1227 SmrtIMS_ImgDBVal 0 "none" 1 "Smart IMS Image DB 1~30" 2 "Smart IMS Image DB 1~30" 3 "Smart IMS Image DB 1~30" 4 "Smart IMS Image DB 1~30" 5 "Smart IMS Image DB 1~30" 6 "Smart IMS Image DB 1~30" 7 "Smart IMS Image DB 1~30" 8 "Smart IMS Image DB 1~30" 9 "Smart IMS Image DB 1~30" 10 "Smart IMS Image DB 1~30" 11 "Smart IMS Image DB 1~30" 12 "Smart IMS Image DB 1~30" 13 "Smart IMS Image DB 1~30" 14 "Smart IMS Image DB 1~30" 15 "Smart IMS Image DB 1~30" 16 "Smart IMS Image DB 1~30" 17 "Smart IMS Image DB 1~30" 18 "Smart IMS Image DB 1~30" 19 "Smart IMS Image DB 1~30" 20 "Smart IMS Image DB 1~30" 21 "Smart IMS Image DB 1~30" 22 "Smart IMS Image DB 1~30" 23 "Smart IMS Image DB 1~30" 24 "Smart IMS Image DB 1~30" 25 "Smart IMS Image DB 1~30" 26 "Smart IMS Image DB 1~30" 27 "Smart IMS Image DB 1~30" 28 "Smart IMS Image DB 1~30" 29 "Smart IMS Image DB 1~30" 30 "Smart IMS Image DB 1~30" 31 "Invalid" ;
VAL_ 1227 SmrtIMS_PlyBckStpReq 0 "OFF" 1 "On" 2 "Not Used" 3 "Error Indicator" ;
VAL_ 1227 DrvIMS_MemoryP3Req 0 "None" 1 "P3" 2 "Not Used" 3 "Error Indicator" ;
VAL_ 1227 SmrtIMS_EnterSwSta 0 "off" 1 "on" 2 "reserved" 3 "invalid" ;
VAL_ 1227 DrvIMS_BzrReq 0 "Off" 1 "On" 2 "Not Used" 3 "Error Indicator" ;
VAL_ 1227 DrvIMS_ErrConWmgDis 0 "Off" 1 "On" 2 "Not Used" 3 "Error Indicator" ;
VAL_ 1227 PSM_DrvRlxReturn_Req 0 "Default" 1 "One touch relax" 2 "One touch return" 3 "Stop" 4 "Reserved" 5 "Reserved" 6 "Reserved" 7 "invalid" ;
VAL_ 1227 Drv_AutoRlxWrngDis 0 "Off" 1 "Auto Relax Enable" 2 "Mode-Fail (Vehicle Speed Warning)" 3 "Mode-Fail (Not P Warning)" 4 "Mode-Fail (2nd Seat Belted)" 5 "Mode-Fail (Not Initialized)" 6 "Mode-Fail (2nd Seat Position Warning)" 7 "Invalid" ;
VAL_ 1227 DrvIMS_AMPBzrReq 0 "Off" 1 "On (LHD)" 2 "On (RHD)" 3 "Error Indicator" ;
VAL_ 1227 Drv_AutoRlxWrngDis_2 0 "Off" 1 "2nd Seat Moving" 2 "2nd Seat Repositioning" 3 "RESERVED" 4 "RESERVED" 5 "RESERVED" 6 "RESERVED" 7 "Invalid" ;
VAL_ 1227 Drv_2ndStStdPosMovReq 0 "Default" 1 "ON" 2 "RESERVED" 3 "Invalid" ;
VAL_ 1227 DrvIMS_MemorySetEnaSta 0 "Disable" 1 "Enable" 2 "Not Used" 3 "Error Indicator" ;
VAL_ 1227 DrvIMS_PlyBckP1Req 0 "None" 1 "P1" 2 "Not Used" 3 "Error Indicator" ;
VAL_ 1252 RKE_Crc1Val 0 "0x0x0~0xFF:CRCValue" 255 "0x0x0~0xFF:CRCValue" ;
VAL_ 1252 RKE_AlvCnt1Val 0 "AlvCntValue" 1 "AlvCntValue" 2 "AlvCntValue" 3 "AlvCntValue" 4 "AlvCntValue" 5 "AlvCntValue" 6 "AlvCntValue" 7 "AlvCntValue" 8 "AlvCntValue" 9 "AlvCntValue" 10 "AlvCntValue" 11 "AlvCntValue" 12 "AlvCntValue" 13 "AlvCntValue" 14 "AlvCntValue" 15 "AlvCntValue" ;
VAL_ 1252 RKE_BtnReq 0 "None" 1 "Lock" 2 "Unlock" 3 "Trunk(Or Tail Gate)" 4 "Panic" 5 "Panic Stop" 6 "Two Step Unlock Warning or India Door Lock/Unlock Sound ON/OFF Set" 7 "Remote Cranking Stop" 8 "Remote Cranking Start" 9 "Forward(RSPA)" 10 "Backward/Parking(RSPA)" 11 "Pause(RSPA)" 12 "Front Trunk" 13 "Reserved" 14 "Charge Door / ImmeChg" 15 "Error Indicator" ;
VAL_ 1252 RKE_PsdBtnReq 0 "Off" 1 "LH On" 2 "RH On" 3 "PanicStop_PSD LH" 4 "PanicStop_PSD RH" 5 "Reseved" 6 "Reseved" 7 "Reserved" 8 "Reserved" 9 "Reserved" 10 "Reserved" 11 "Reserved" 12 "Reserved" 13 "Reserved" 14 "Not Used" 15 "Error Indicator" ;
VAL_ 1252 RKE_WdwUpDnReq 0 "None" 1 "Remote Window Open" 2 "Remote Window Close" 3 "Remote Window Stop" 4 "Reseved" 5 "Reseved" 6 "Not Used" 7 "Error Indicator" ;
VAL_ 1252 RKE_TrnkTlgtBtnReq 0 "Default" 1 "TailgateTrunkOn" 2 "Off" 3 "Reserved" 4 "Reserved" 5 "Reseved" 6 "Reseved" 7 "Error Indiator" ;
VAL_ 1252 RKE_ID 0 "None" 1 "ID1" 2 "ID2" 3 "ID3" 4 "ID4" 5 "Reseved" 6 "Not Used" 7 "Error Indicator" ;
VAL_ 1252 RKE_PwrDrAllOpnClsReq 0 "None" 1 "Open" 2 "Close" 3 "Stop" 4 "Reserved" 5 "Reserved" 6 "Reserved" 7 "Reserved" ;
VAL_ 1252 RKE_FrnkBtnReq 0 "None" 1 "Frunk Open" 2 "Frunk Panic Stop" 3 "RESERVED" 4 "RESERVED" 5 "RESERVED" 6 "RESERVED" 7 "Error Indicator" ;
VAL_ 1253 SMK_Crc1Val 0 "0x0x0~0xFF:CRCValue" 255 "0x0x0~0xFF:CRCValue" ;
VAL_ 1253 SMK_AlvCnt1Val 0 "AlvCntValue" 1 "AlvCntValue" 2 "AlvCntValue" 3 "AlvCntValue" 4 "AlvCntValue" 5 "AlvCntValue" 6 "AlvCntValue" 7 "AlvCntValue" 8 "AlvCntValue" 9 "AlvCntValue" 10 "AlvCntValue" 11 "AlvCntValue" 12 "AlvCntValue" 13 "AlvCntValue" 14 "AlvCntValue" 15 "AlvCntValue" ;
VAL_ 1253 DoorLock_PsvDrLkReq 0 "None" 1 "Lock" 2 "PassiveTrunkLock" 3 "Reserved" 4 "Reserved" 5 "Reseved" 6 "Not Used" 7 "Error Indicator" ;
VAL_ 1253 DoorLock_PsvDrUnLkReq 0 "None" 1 "UnLock" 2 "Unlock only DRV Door" 3 "PIC_Key_Reminder" 4 "Reserved" 5 "Reseved" 6 "Not Used" 7 "Error Indicator" ;
VAL_ 1253 DoorLock_DrvDrPsvAcsReq 0 "Off" 1 "On" 2 "Not Used" 3 "Error Indicator" ;
VAL_ 1253 DoorLock_AsstDrPsvAcsReq 0 "Off" 1 "On" 2 "Not Used" 3 "Error Indicator" ;
VAL_ 1253 DoorLock_TrnkTlgtPsvAcsReq 0 "Off" 1 "On" 2 "Not Used" 3 "Error Indicator" ;
VAL_ 1253 DoorLock_RrLftDrPsvAcsReq 0 "Off" 1 "On" 2 "Not Used" 3 "Error Indicator" ;
VAL_ 1253 DoorLock_RrRtDrPsvAcsReq 0 "Off" 1 "On" 2 "Not Used" 3 "Error Indicator" ;
VAL_ 1253 DoorLock_PsdPsvAcsReq 0 "Off" 1 "Drv On" 2 "Ast On" 3 "Reserved" 4 "Reserved" 5 "Reseved" 6 "Not Used" 7 "Error Indicator" ;
VAL_ 1253 Auth_Req 0 "None" 1 "Auth request for CHINA BLE" 2 "Auth Request for Terminal Function" 3 "Reserved" 4 "Reserved" 5 "Reserved" 6 "Reserved" 7 "Invalid" ;
VAL_ 1253 RSPA_DigitalKeyAuth 0 "Default" 1 "Digital Key Auth" 2 "Not used" 3 "Error Indicator" ;
VAL_ 1253 Auth_Method 0 "None Auth" 1 "Auth by FOB" 2 "Auth by TP" 3 "Auth by FP" 4 "Auth by NFC (DK or Card)" 5 "Auth Fail" 6 "Auth by BLE (CHINA)" 7 "FRU" 8 "Auth by Digital Key RKE" 9 "Auth by Digital Key Passive" 10 "Reserve" 11 "Reserve" 12 "Reserve" 13 "Reserve" 14 "Not used" 15 "Error Indicator" ;
VAL_ 1253 DoorLock_StrgbxPsvAcsReq 0 "Off" 1 "On" 2 "Not Used" 3 "Error Indicator" ;
VAL_ 1253 Auth_ISKLearnFdbck 0 "Default (Normal)" 1 "Positive" 2 "Mismatch ISK" 3 "Mismatch RN" 4 "Save Failed ISK" 5 "Timeout" 6 "Not Learnt" 7 "Reserved" 8 "Reserved" 9 "Reserved" 10 "Reserved" 11 "Reserved" 12 "Reserved" 13 "Reserved" 14 "not used" 15 "Error Indicator" ;
VAL_ 1253 DoorLock_FrnkWrngOpnReq 0 "Off" 1 "On" 2 "Reserved" 3 "Error Indicator" ;
VAL_ 1253 DoorLock_SmrtPsdPsvAcsReq 0 "Off" 1 "Drv Door Open" 2 "Ast Door Open" 3 "Reserved" 4 "Reserved" 5 "Reserved" 6 "Not Used" 7 "Error Indicator" ;
VAL_ 1253 Auth_Event 0 "Default" 1 "Lock" 2 "Unlcok" 3 "Start" 4 "Trunk" 5 "Reserved" 6 "Reserved" 7 "Reserved" 8 "Reserved" 9 "Reserved" 10 "Reserved" 11 "Reserved" 12 "Reserved" 13 "Reserved" 14 "Not Used" 15 "Invalid" ;
VAL_ 1237 SWRC_Crc2Val 0 "0x0x0~0xFF:CRCValue" 255 "0x0x0~0xFF:CRCValue" ;
VAL_ 1237 SWRC_AlvCnt2Val 0 "AlvCntValue" 1 "AlvCntValue" 2 "AlvCntValue" 3 "AlvCntValue" 4 "AlvCntValue" 5 "AlvCntValue" 6 "AlvCntValue" 7 "AlvCntValue" 8 "AlvCntValue" 9 "AlvCntValue" 10 "AlvCntValue" 11 "AlvCntValue" 12 "AlvCntValue" 13 "AlvCntValue" 14 "AlvCntValue" 15 "AlvCntValue" ;
VAL_ 1237 Audio_VolEncoderSta 0 "Reserved" 1 "0x01~0x7F:Clockwise(Up)" 127 "0x01~0x7F:Clockwise(Up)" 128 "0x80~0xFE:Counterclockwise (Down)" 254 "0x80~0xFE:Counterclockwise (Down)" 255 "Invalid" ;
VAL_ 1237 Cluster_ScrlEncoderSta 0 "Reserved" 1 "0x01~0x7F:Clockwise(Up)" 127 "0x01~0x7F:Clockwise(Up)" 128 "0x80~0xFE:Counterclockwise (Down)" 254 "0x80~0xFE:Counterclockwise (Down)" 255 "Invalid" ;
VAL_ 139 SWRC_Crc5Val 0 "0x0x0~0xFF:CRCValue" 255 "0x0x0~0xFF:CRCValue" ;
VAL_ 139 SWRC_AlvCnt5Val 0 "AlvCntValue" 1 "AlvCntValue" 2 "AlvCntValue" 3 "AlvCntValue" 4 "AlvCntValue" 5 "AlvCntValue" 6 "AlvCntValue" 7 "AlvCntValue" 8 "AlvCntValue" 9 "AlvCntValue" 10 "AlvCntValue" 11 "AlvCntValue" 12 "AlvCntValue" 13 "AlvCntValue" 14 "AlvCntValue" 15 "AlvCntValue" ;
VAL_ 139 SWRC_DriveModCWSwSta 0 "Off" 1 "On" 2 "Reserved" 3 "Invalid" ;
VAL_ 139 SWRC_DriveModCCWSwSta 0 "Off" 1 "On" 2 "Reserved" 3 "Invalid" ;
VAL_ 139 SWRC_BoostSwSta 0 "Off" 1 "Key On" 2 "Reserved" 3 "Invalid" ;
VAL_ 139 SWRC_DriveModeSwSta 0 "Off" 1 "On" 2 "Reserved" 3 "Invalid" ;
VAL_ 139 SWRC_TerrainModeSwSta 0 "Off" 1 "On" 2 "Reserved" 3 "Invalid" ;
VAL_ 139 SWRC_N1SwSta 0 "Off" 1 "Key On" 2 "RESERVED" 3 "Invalid" ;
VAL_ 139 SWRC_N2SwSta 0 "Off" 1 "Key On" 2 "RESERVED" 3 "Invalid" ;
VAL_ 139 SWRC_4wdLocking 0 "Off" 1 "On" 2 "Invalid" 3 "RESERVED" ;
VAL_ 139 SWRC_GTSWSta 0 "Off" 1 "On" 2 "RESERVED" 3 "Invalid" ;
